VERSION "$Format:%h$"

NS_ :

BS_:

BU_: APB APP APS BCCEN BDY DAS DBG EAS EPAS EPAS2 EPAS3S EPB EPBM ESP GTW GTWU IBST IC MCU OCS PARK PARK3 RADAR RCM RT3000 SCCM SDM SEC TAS TAS2 TAS2DBG TOOL TPMS VCSEATD VCSEATP

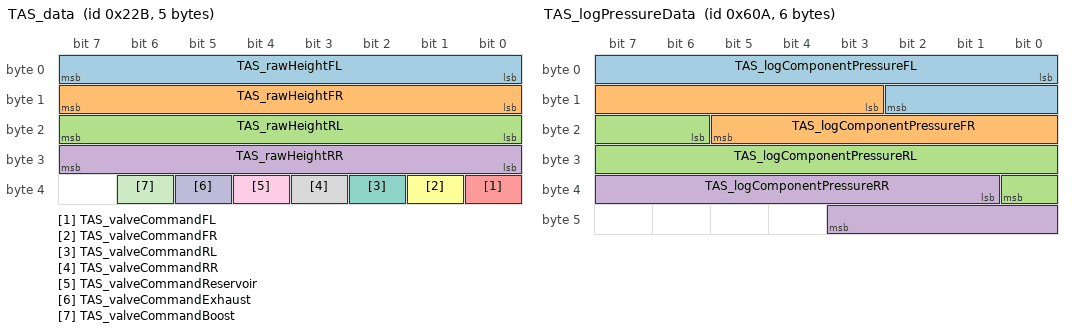
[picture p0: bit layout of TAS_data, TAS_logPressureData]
BO_ 555 TAS_data: 5 TAS
 SG_ TAS_rawHeightFL : 0|8@1+ (1,-128) [-128|127] "mm" GTW
 SG_ TAS_rawHeightFR : 8|8@1+ (1,-128) [-128|127] "mm" GTW
 SG_ TAS_rawHeightRL : 16|8@1+ (1,-128) [-128|127] "mm" GTW
 SG_ TAS_rawHeightRR : 24|8@1+ (1,-128) [-128|127] "mm" GTW
 SG_ TAS_valveCommandFL : 32|1@1+ (1,0) [0|1] "" GTW
 SG_ TAS_valveCommandFR : 33|1@1+ (1,0) [0|1] "" GTW
 SG_ TAS_valveCommandRL : 34|1@1+ (1,0) [0|1] "" GTW
 SG_ TAS_valveCommandRR : 35|1@1+ (1,0) [0|1] "" GTW
 SG_ TAS_valveCommandReservoir : 36|1@1+ (1,0) [0|1] "" GTW
 SG_ TAS_valveCommandExhaust : 37|1@1+ (1,0) [0|1] "" GTW
 SG_ TAS_valveCommandBoost : 38|1@1+ (1,0) [0|1] "" GTW

BO_ 1610 TAS_debugStates: 2 TAS
 SG_ TAS_debugStates M : 0|1@1+ (1,0) [0|1] "" Vector__XXX
 SG_ TAS_launchModeState m1 : 8|3@1+ (1,0) [0|4] "" Vector__XXX

BO_ 1307 TAS_info: 8 TAS
 SG_ TAS_infoIndex M : 0|8@1+ (1,0) [0|255] "" GTW,GTWU
 SG_ TAS_infoBuildType m10 : 8|8@1+ (1,0) [0|4] "" GTW
 SG_ TAS_infoBuildConfigId m10 : 16|16@1+ (1,0) [0|65535] "" GTW
 SG_ TAS_infoHardwareId m10 : 32|1@1+ (1,0) [0|1] "" GTW
 SG_ TAS_infoComponentId m10 : 48|16@1+ (1,0) [0|65535] "" GTW
 SG_ TAS_infoPcbaId m11 : 16|8@1+ (1,0) [0|255] "" GTW,GTWU
 SG_ TAS_infoAssemblyId m11 : 24|8@1+ (1,0) [0|255] "" GTW,GTWU
 SG_ TAS_infoUsageId m11 : 32|16@1+ (1,0) [0|65535] "" GTW,GTWU
 SG_ TAS_infoSubUsageId m11 : 48|16@1+ (1,0) [0|65535] "" GTW
 SG_ TAS_infoAppCrc m13 : 32|32@1+ (1,0) [0|4294967295] "" GTW,GTWU
 SG_ TAS_infoBootloaderSvnRevision m14 : 8|24@1+ (1,0) [0|16777215] "" GTW
 SG_ TAS_infoAppGitHash m17 : 8|56@1+ (1,0) [0|7.20575940379279E+16] "" GTW
 SG_ TAS_infoBootGitHash m18 : 8|56@1+ (1,0) [0|7.20575940379279E+16] "" GTW
 SG_ TAS_infoPlatformType m19 : 8|8@1+ (1,0) [0|255] "" GTW
 SG_ TAS_infoMajorVersion m19 : 16|8@1+ (1,0) [0|255] "" GTW
 SG_ TAS_infoBranchOrigin m19 : 24|8@1+ (1,0) [0|255] "" GTW
 SG_ TAS_infoMaturity m19 : 32|8@1+ (1,0) [0|255] "" GTW
 SG_ TAS_infoHardwareRevision m19 : 40|8@1+ (1,0) [0|255] "" GTW
 SG_ TAS_infoBootUdsProtoVersion m20 : 8|8@1+ (1,0) [0|255] "" GTW,GTWU
 SG_ TAS_infoBootCrc m20 : 32|32@1+ (1,0) [0|4294967295] "" GTW

BO_ 1546 TAS_logPressureData: 6 TAS
 SG_ TAS_logComponentPressureFL : 0|11@1+ (0.01,0) [0|20.47] "bara" GTW
 SG_ TAS_logComponentPressureFR : 11|11@1+ (0.01,0) [0|20.47] "bara" GTW
 SG_ TAS_logComponentPressureRL : 22|11@1+ (0.01,0) [0|20.47] "bara" GTW
 SG_ TAS_logComponentPressureRR : 33|11@1+ (0.01,0) [0|20.47] "bara" GTW

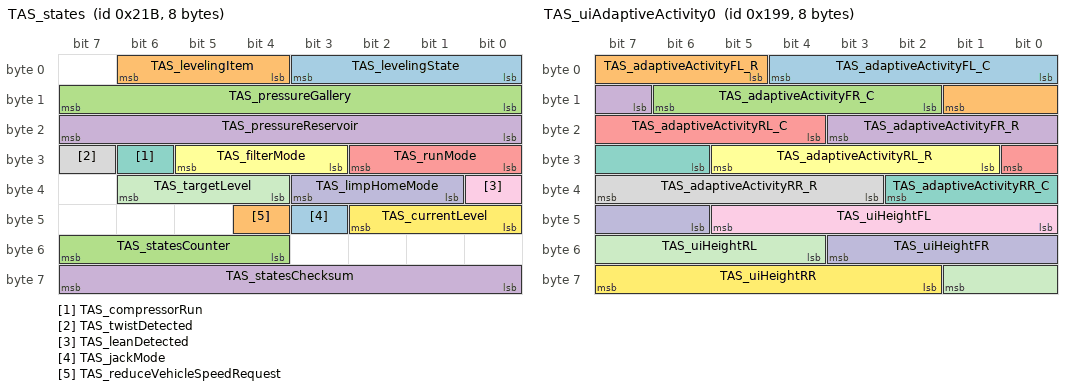
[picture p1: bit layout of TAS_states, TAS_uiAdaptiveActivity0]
BO_ 539 TAS_states: 8 TAS
 SG_ TAS_levelingState : 0|4@1+ (1,0) [0|12] "" GTW
 SG_ TAS_levelingItem : 4|3@1+ (1,0) [0|7] "" BCCEN,GTW
 SG_ TAS_pressureGallery : 8|8@1+ (0.1,0) [0|25.5] "bara" GTW
 SG_ TAS_pressureReservoir : 16|8@1+ (0.1,0) [0|25.5] "bara" GTW
 SG_ TAS_runMode : 24|3@1+ (1,0) [0|6] "" GTW
 SG_ TAS_filterMode : 27|3@1+ (1,0) [0|7] "" GTW
 SG_ TAS_compressorRun : 30|1@1+ (1,0) [0|1] "" GTW
 SG_ TAS_twistDetected : 31|1@1+ (1,0) [0|1] "" GTW
 SG_ TAS_leanDetected : 32|1@1+ (1,0) [0|1] "" GTW
 SG_ TAS_limpHomeMode : 33|3@1+ (1,0) [0|4] "" GTW
 SG_ TAS_targetLevel : 36|3@1+ (1,0) [0|4] "" GTW
 SG_ TAS_currentLevel : 40|3@1+ (1,0) [0|4] "" DAS,GTW
 SG_ TAS_jackMode : 43|1@1+ (1,0) [0|1] "" GTW
 SG_ TAS_reduceVehicleSpeedRequest : 44|1@1+ (1,0) [0|1] "" GTW
 SG_ TAS_statesCounter : 52|4@1+ (1,0) [0|15] "" GTW
 SG_ TAS_statesChecksum : 56|8@1+ (1,0) [0|255] "" GTW

BO_ 1627 TAS_udsResponse: 8 TAS
 SG_ TAS_udsResponseData : 7|64@0+ (1,0) [0|1.84467440737096E+19] "" GTW,GTWU

BO_ 409 TAS_uiAdaptiveActivity0: 8 TAS
 SG_ TAS_adaptiveActivityFL_C : 0|5@1+ (0.04,0) [0|1] "-" GTW
 SG_ TAS_adaptiveActivityFL_R : 5|5@1+ (0.04,0) [0|1] "-" GTW
 SG_ TAS_adaptiveActivityFR_C : 10|5@1+ (0.04,0) [0|1] "-" GTW
 SG_ TAS_adaptiveActivityFR_R : 15|5@1+ (0.04,0) [0|1] "-" GTW
 SG_ TAS_adaptiveActivityRL_C : 20|5@1+ (0.04,0) [0|1] "-" GTW
 SG_ TAS_adaptiveActivityRL_R : 25|5@1+ (0.04,0) [0|1] "-" GTW
 SG_ TAS_adaptiveActivityRR_C : 30|5@1+ (0.04,0) [0|1] "-" GTW
 SG_ TAS_adaptiveActivityRR_R : 35|5@1+ (0.04,0) [0|1] "-" GTW
 SG_ TAS_uiHeightFL : 40|6@1+ (4,-128) [-128|124] "mm" GTW
 SG_ TAS_uiHeightFR : 46|6@1+ (4,-128) [-128|124] "mm" GTW
 SG_ TAS_uiHeightRL : 52|6@1+ (4,-128) [-128|124] "mm" GTW
 SG_ TAS_uiHeightRR : 58|6@1+ (4,-128) [-128|124] "mm" GTW

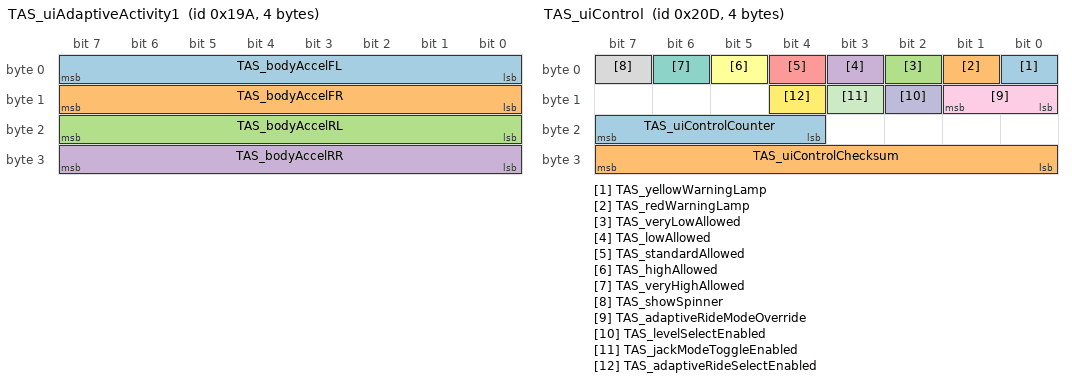
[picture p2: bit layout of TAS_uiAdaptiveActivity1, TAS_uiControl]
BO_ 410 TAS_uiAdaptiveActivity1: 4 TAS
 SG_ TAS_bodyAccelFL : 0|8@1+ (0.05,-5) [-5|5] "g" GTW
 SG_ TAS_bodyAccelFR : 8|8@1+ (0.05,-5) [-5|5] "g" GTW
 SG_ TAS_bodyAccelRL : 16|8@1+ (0.05,-5) [-5|5] "g" GTW
 SG_ TAS_bodyAccelRR : 24|8@1+ (0.05,-5) [-5|5] "g" GTW

BO_ 525 TAS_uiControl: 4 TAS
 SG_ TAS_yellowWarningLamp : 0|1@1+ (1,0) [0|1] "" GTW
 SG_ TAS_redWarningLamp : 1|1@1+ (1,0) [0|1] "" GTW
 SG_ TAS_veryLowAllowed : 2|1@1+ (1,0) [0|1] "" GTW
 SG_ TAS_lowAllowed : 3|1@1+ (1,0) [0|1] "" GTW
 SG_ TAS_standardAllowed : 4|1@1+ (1,0) [0|1] "" GTW
 SG_ TAS_highAllowed : 5|1@1+ (1,0) [0|1] "" GTW
 SG_ TAS_veryHighAllowed : 6|1@1+ (1,0) [0|1] "" GTW
 SG_ TAS_showSpinner : 7|1@1+ (1,0) [0|1] "" GTW
 SG_ TAS_adaptiveRideModeOverride : 8|2@1+ (1,0) [0|3] "" GTW
 SG_ TAS_levelSelectEnabled : 10|1@1+ (1,0) [0|1] "" GTW
 SG_ TAS_jackModeToggleEnabled : 11|1@1+ (1,0) [0|1] "" GTW
 SG_ TAS_adaptiveRideSelectEnabled : 12|1@1+ (1,0) [0|1] "" GTW
 SG_ TAS_uiControlCounter : 20|4@1+ (1,0) [0|15] "" GTW
 SG_ TAS_uiControlChecksum : 24|8@1+ (1,0) [0|255] "" GTW

BO_ 843 TAS_warningMatrix1: 8 TAS
 SG_ TAS_a001_WatchdogReset : 0|1@1+ (1,0) [0|1] "" GTW
 SG_ TAS_a002_PowerLossReset : 1|1@1+ (1,0) [0|1] "" GTW
 SG_ TAS_a003_SWAssertion : 2|1@1+ (1,0) [0|1] "" GTW
 SG_ TAS_a012_CPUReset : 11|1@1+ (1,0) [0|1] "" GTW
 SG_ TAS_a015_NVMMAlert : 14|1@1+ (1,0) [0|1] "" GTW
 SG_ TAS_a021_TaskSchedulerError : 20|1@1+ (1,0) [0|1] "" GTW
 SG_ TAS_a022_TaskInitError : 21|1@1+ (1,0) [0|1] "" GTW
 SG_ TAS_a025_CrashEvent : 24|1@1+ (1,0) [0|1] "" GTW
 SG_ TAS_a030_PWMerrorFL : 29|1@1+ (1,0) [0|1] "" GTW
 SG_ TAS_a031_PWMerrorFR : 30|1@1+ (1,0) [0|1] "" GTW
 SG_ TAS_a032_PWMerrorRL : 31|1@1+ (1,0) [0|1] "" GTW
 SG_ TAS_a033_PWMerrorRR : 32|1@1+ (1,0) [0|1] "" GTW
 SG_ TAS_a034_PWMshortFL : 33|1@1+ (1,0) [0|1] "" GTW
 SG_ TAS_a035_PWMshortFR : 34|1@1+ (1,0) [0|1] "" GTW
 SG_ TAS_a036_PWMshortRL : 35|1@1+ (1,0) [0|1] "" GTW
 SG_ TAS_a037_PWMshortRR : 36|1@1+ (1,0) [0|1] "" GTW
 SG_ TAS_a038_PWMopenFL : 37|1@1+ (1,0) [0|1] "" GTW
 SG_ TAS_a039_PWMopenFR : 38|1@1+ (1,0) [0|1] "" GTW
 SG_ TAS_a040_PWMopenRL : 39|1@1+ (1,0) [0|1] "" GTW
 SG_ TAS_a041_PWMopenRR : 40|1@1+ (1,0) [0|1] "" GTW
 SG_ TAS_a043_Task1msError : 42|1@1+ (1,0) [0|1] "" GTW
 SG_ TAS_a044_Task10msError : 43|1@1+ (1,0) [0|1] "" GTW
 SG_ TAS_a045_Task100msError : 44|1@1+ (1,0) [0|1] "" GTW
 SG_ TAS_a046_Task1000msError : 45|1@1+ (1,0) [0|1] "" GTW
 SG_ TAS_a061_XCPConnected : 60|1@1+ (1,0) [0|1] "" GTW
 SG_ TAS_a062_XCPWasConnected : 61|1@1+ (1,0) [0|1] "" GTW

BO_ 859 TAS_warningMatrix2: 8 TAS
 SG_ TAS_a070_underVoltage12V : 5|1@1+ (1,0) [0|1] "" GTW
 SG_ TAS_a071_overVoltage12V : 6|1@1+ (1,0) [0|1] "" GTW
 SG_ TAS_a072_shortCircuit5VOnBoard : 7|1@1+ (1,0) [0|1] "" GTW
 SG_ TAS_a073_underVoltage5VOnBoard : 8|1@1+ (1,0) [0|1] "" GTW
 SG_ TAS_a074_shortCircuit5VOffBoard : 9|1@1+ (1,0) [0|1] "" GTW
 SG_ TAS_a075_underVoltage5VOffBoard : 10|1@1+ (1,0) [0|1] "" GTW
 SG_ TAS_a076_overVoltage5VOffBoard : 11|1@1+ (1,0) [0|1] "" GTW
 SG_ TAS_a077_pressureSigVTooLow : 12|1@1+ (1,0) [0|1] "" GTW
 SG_ TAS_a078_pressureSigVTooHigh : 13|1@1+ (1,0) [0|1] "" GTW
 SG_ TAS_a093_OTPError : 28|1@1+ (1,0) [0|1] "" GTW
 SG_ TAS_a098_MCU_MIA : 33|1@1+ (1,0) [0|1] "" GTW
 SG_ TAS_a099_EFUSE_MIA : 34|1@1+ (1,0) [0|1] "" GTW
 SG_ TAS_a100_SCCM_MIA : 35|1@1+ (1,0) [0|1] "" GTW
 SG_ TAS_a101_ESP_MIA : 36|1@1+ (1,0) [0|1] "" GTW
 SG_ TAS_a102_DI_MIA : 37|1@1+ (1,0) [0|1] "" GTW
 SG_ TAS_a103_GTW_MIA : 38|1@1+ (1,0) [0|1] "" GTW
 SG_ TAS_a105_ECUDebugMode : 40|1@1+ (1,0) [0|1] "" GTW
 SG_ TAS_a106_HighCPULoad : 41|1@1+ (1,0) [0|1] "" GTW
 SG_ TAS_a107_HighStackUsage : 42|1@1+ (1,0) [0|1] "" GTW
 SG_ TAS_a121_maxDutyFL : 56|1@1+ (1,0) [0|1] "" GTW
 SG_ TAS_a122_maxDutyFR : 57|1@1+ (1,0) [0|1] "" GTW
 SG_ TAS_a123_maxDutyRL : 58|1@1+ (1,0) [0|1] "" GTW
 SG_ TAS_a124_maxDutyRR : 59|1@1+ (1,0) [0|1] "" GTW
 SG_ TAS_a125_maxDutyReservoir : 60|1@1+ (1,0) [0|1] "" GTW
 SG_ TAS_a126_maxDutyExhaust : 61|1@1+ (1,0) [0|1] "" GTW
 SG_ TAS_a127_maxDutyBoost : 62|1@1+ (1,0) [0|1] "" GTW
 SG_ TAS_a128_maxDutyCompressor : 63|1@1+ (1,0) [0|1] "" GTW

BO_ 875 TAS_warningMatrix3: 8 TAS
 SG_ TAS_a129_openCircuitFL : 0|1@1+ (1,0) [0|1] "" GTW
 SG_ TAS_a130_openCircuitFR : 1|1@1+ (1,0) [0|1] "" GTW
 SG_ TAS_a131_openCircuitRL : 2|1@1+ (1,0) [0|1] "" GTW
 SG_ TAS_a132_openCircuitRR : 3|1@1+ (1,0) [0|1] "" GTW
 SG_ TAS_a133_openCircuitReservoir : 4|1@1+ (1,0) [0|1] "" GTW
 SG_ TAS_a134_openCircuitExhaust : 5|1@1+ (1,0) [0|1] "" GTW
 SG_ TAS_a135_openCircuitBoost : 6|1@1+ (1,0) [0|1] "" GTW
 SG_ TAS_a136_openCircuitCompressor : 7|1@1+ (1,0) [0|1] "" GTW
 SG_ TAS_a137_shortCircuitFL : 8|1@1+ (1,0) [0|1] "" GTW
 SG_ TAS_a138_shortCircuitFR : 9|1@1+ (1,0) [0|1] "" GTW
 SG_ TAS_a139_shortCircuitRL : 10|1@1+ (1,0) [0|1] "" GTW
 SG_ TAS_a140_shortCircuitRR : 11|1@1+ (1,0) [0|1] "" GTW
 SG_ TAS_a141_shortCircuitReservoir : 12|1@1+ (1,0) [0|1] "" GTW
 SG_ TAS_a142_shortCircuitExhaust : 13|1@1+ (1,0) [0|1] "" GTW
 SG_ TAS_a143_shortCircuitBoost : 14|1@1+ (1,0) [0|1] "" GTW
 SG_ TAS_a144_shortCircuitCompressor : 15|1@1+ (1,0) [0|1] "" GTW
 SG_ TAS_a145_boardFaultFL : 16|1@1+ (1,0) [0|1] "" GTW
 SG_ TAS_a146_boardFaultFR : 17|1@1+ (1,0) [0|1] "" GTW
 SG_ TAS_a147_boardFaultRL : 18|1@1+ (1,0) [0|1] "" GTW
 SG_ TAS_a148_boardFaultRR : 19|1@1+ (1,0) [0|1] "" GTW
 SG_ TAS_a149_boardFaultReservoir : 20|1@1+ (1,0) [0|1] "" GTW
 SG_ TAS_a150_boardFaultExhaust : 21|1@1+ (1,0) [0|1] "" GTW
 SG_ TAS_a151_boardFaultBoost : 22|1@1+ (1,0) [0|1] "" GTW
 SG_ TAS_a152_boardFaultCompressor : 23|1@1+ (1,0) [0|1] "" GTW
 SG_ TAS_a153_otherCircuitFL : 24|1@1+ (1,0) [0|1] "" GTW
 SG_ TAS_a154_otherCircuitFR : 25|1@1+ (1,0) [0|1] "" GTW
 SG_ TAS_a155_otherCircuitRL : 26|1@1+ (1,0) [0|1] "" GTW
 SG_ TAS_a156_otherCircuitRR : 27|1@1+ (1,0) [0|1] "" GTW
 SG_ TAS_a157_otherCircuitReservoir : 28|1@1+ (1,0) [0|1] "" GTW
 SG_ TAS_a158_otherCircuitExhaust : 29|1@1+ (1,0) [0|1] "" GTW
 SG_ TAS_a159_otherCircuitBoost : 30|1@1+ (1,0) [0|1] "" GTW
 SG_ TAS_a160_otherCircuitCompressor : 31|1@1+ (1,0) [0|1] "" GTW
 SG_ TAS_a161_valveBlockOpenGND : 32|1@1+ (1,0) [0|1] "" GTW
 SG_ TAS_a162_compressorValveOpenGND : 33|1@1+ (1,0) [0|1] "" GTW
 SG_ TAS_a163_reservoirFillDisabled : 34|1@1+ (1,0) [0|1] "" GTW
 SG_ TAS_a173_staticLeakDetectFL : 44|1@1+ (1,0) [0|1] "" GTW
 SG_ TAS_a174_staticLeakDetectFR : 45|1@1+ (1,0) [0|1] "" GTW
 SG_ TAS_a175_staticLeakDetectRL : 46|1@1+ (1,0) [0|1] "" GTW
 SG_ TAS_a176_staticLeakDetectRR : 47|1@1+ (1,0) [0|1] "" GTW

BO_ 891 TAS_warningMatrix4: 8 TAS
 SG_ TAS_a200_jackModeActive : 7|1@1+ (1,0) [0|1] "" GTW
 SG_ TAS_a201_lowHVBattery : 8|1@1+ (1,0) [0|1] "" GTW
 SG_ TAS_a210_outOfRangeCalibration : 17|1@1+ (1,0) [0|1] "" GTW
 SG_ TAS_a211_noRideHeightCalib : 18|1@1+ (1,0) [0|1] "" GTW
 SG_ TAS_a213_yellowWarningLamp : 20|1@1+ (1,0) [0|1] "" GTW
 SG_ TAS_a214_redWarningLamp : 21|1@1+ (1,0) [0|1] "" GTW
 SG_ TAS_a215_limpHomeMode10 : 22|1@1+ (1,0) [0|1] "" GTW
 SG_ TAS_a216_limpHomeMode20 : 23|1@1+ (1,0) [0|1] "" GTW
 SG_ TAS_a217_limpHomeMode30 : 24|1@1+ (1,0) [0|1] "" GTW
 SG_ TAS_a218_limpHomeMode40 : 25|1@1+ (1,0) [0|1] "" GTW
 SG_ TAS_a220_exhaustGalleryFault : 27|1@1+ (1,0) [0|1] "" GTW
 SG_ TAS_a221_valveLeakDetected : 28|1@1+ (1,0) [0|1] "" GTW
 SG_ TAS_a222_compressorPrefillFault : 29|1@1+ (1,0) [0|1] "" GTW
 SG_ TAS_a223_blockedAirline : 30|1@1+ (1,0) [0|1] "" GTW
 SG_ TAS_a224_openAirline : 31|1@1+ (1,0) [0|1] "" GTW
 SG_ TAS_a225_galleryPressureTooHigh : 32|1@1+ (1,0) [0|1] "" GTW
 SG_ TAS_a226_PWMfastDetectFL : 33|1@1+ (1,0) [0|1] "" GTW
 SG_ TAS_a227_PWMfastDetectFR : 34|1@1+ (1,0) [0|1] "" GTW
 SG_ TAS_a228_PWMfastDetectRL : 35|1@1+ (1,0) [0|1] "" GTW
 SG_ TAS_a229_PWMfastDetectRR : 36|1@1+ (1,0) [0|1] "" GTW
 SG_ TAS_a230_geofenceNotification : 37|1@1+ (1,0) [0|1] "" GTW

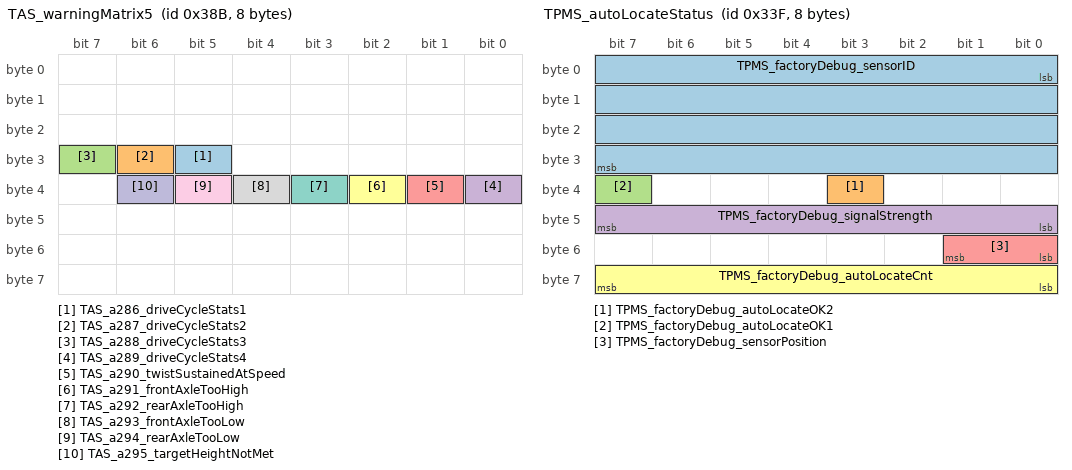
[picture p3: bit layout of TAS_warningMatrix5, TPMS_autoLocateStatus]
BO_ 907 TAS_warningMatrix5: 8 TAS
 SG_ TAS_a286_driveCycleStats1 : 29|1@1+ (1,0) [0|1] "" GTW
 SG_ TAS_a287_driveCycleStats2 : 30|1@1+ (1,0) [0|1] "" GTW
 SG_ TAS_a288_driveCycleStats3 : 31|1@1+ (1,0) [0|1] "" GTW
 SG_ TAS_a289_driveCycleStats4 : 32|1@1+ (1,0) [0|1] "" GTW
 SG_ TAS_a290_twistSustainedAtSpeed : 33|1@1+ (1,0) [0|1] "" GTW
 SG_ TAS_a291_frontAxleTooHigh : 34|1@1+ (1,0) [0|1] "" GTW
 SG_ TAS_a292_rearAxleTooHigh : 35|1@1+ (1,0) [0|1] "" GTW
 SG_ TAS_a293_frontAxleTooLow : 36|1@1+ (1,0) [0|1] "" GTW
 SG_ TAS_a294_rearAxleTooLow : 37|1@1+ (1,0) [0|1] "" GTW
 SG_ TAS_a295_targetHeightNotMet : 38|1@1+ (1,0) [0|1] "" GTW

BO_ 1851 TAS_xcpResponse: 8 TAS
 SG_ TAS_xcpResponse : 7|64@0+ (1,0) [0|1.84467440737096E+19] "" DBG

BO_ 895 TPMS_DebugC: 8 TPMS

BO_ 879 TPMS_StatusC: 8 TPMS
 SG_ TPMS_c_globalHardWarning : 0|1@1+ (1,0) [0|0] "" GTW,RCM
 SG_ TPMS_c_globalSoftWarning : 1|1@1+ (1,0) [0|0] "" GTW,RCM
 SG_ TPMS_systemMalfunction : 2|1@1+ (1,0) [0|0] "" GTW,RCM
 SG_ TPMS_WA_version : 3|1@1+ (1,0) [0|0] "" GTW
 SG_ TPMS_globalDeltaPressure : 4|1@1+ (1,0) [0|0] "" GTW
 SG_ TPMS_newSensorLearnt : 5|1@1+ (1,0) [0|0] "" GTW
 SG_ TPMS_softWarningRR : 8|1@1+ (1,0) [0|0] "" GTW
 SG_ TPMS_hardWarningRR : 9|1@1+ (1,0) [0|0] "" GTW
 SG_ TPMS_softWarningRL : 10|1@1+ (1,0) [0|0] "" GTW
 SG_ TPMS_hardWarningRL : 11|1@1+ (1,0) [0|0] "" GTW
 SG_ TPMS_softWarningFR : 12|1@1+ (1,0) [0|0] "" GTW
 SG_ TPMS_hardWarningFR : 13|1@1+ (1,0) [0|0] "" GTW
 SG_ TPMS_softWarningFL : 14|1@1+ (1,0) [0|0] "" GTW
 SG_ TPMS_hardWarningFL : 15|1@1+ (1,0) [0|0] "" GTW
 SG_ TPMS_learningStatus : 16|2@1+ (1,0) [0|0] "" GTW
 SG_ TPMS_localisationStatus : 18|2@1+ (1,0) [0|0] "" GTW
 SG_ TPMS_deltaPressWarningFL : 20|1@1+ (1,0) [0|0] "" GTW
 SG_ TPMS_deltaPressWarningFR : 21|1@1+ (1,0) [0|0] "" GTW
 SG_ TPMS_deltaPressWarningRL : 22|1@1+ (1,0) [0|0] "" GTW
 SG_ TPMS_deltaPressWarningRR : 23|1@1+ (1,0) [0|0] "" GTW
 SG_ TPMS_sensorNoResponseFL : 24|1@1+ (1,0) [0|0] "" GTW
 SG_ TPMS_sensorNoResponseFR : 25|1@1+ (1,0) [0|0] "" GTW
 SG_ TPMS_sensorNoResponseRL : 26|1@1+ (1,0) [0|0] "" GTW
 SG_ TPMS_sensorNoResponseRR : 27|1@1+ (1,0) [0|0] "" GTW
 SG_ TPMS_sensorThermShutdownFL : 28|1@1+ (1,0) [0|0] "" GTW
 SG_ TPMS_sensorThermShutdownFR : 29|1@1+ (1,0) [0|0] "" GTW
 SG_ TPMS_sensorThermShutdownRL : 30|1@1+ (1,0) [0|0] "" GTW
 SG_ TPMS_sensorThermShutdownRR : 31|1@1+ (1,0) [0|0] "" GTW
 SG_ TPMS_c_sensorBatteryLowFL : 32|1@1+ (1,0) [0|0] "" GTW
 SG_ TPMS_c_sensorBatteryLowFR : 33|1@1+ (1,0) [0|0] "" GTW
 SG_ TPMS_c_sensorBatteryLowRL : 34|1@1+ (1,0) [0|0] "" GTW
 SG_ TPMS_c_sensorBatteryLowRR : 35|1@1+ (1,0) [0|0] "" GTW
 SG_ TPMS_sensorDefectiveFL : 36|1@1+ (1,0) [0|0] "" GTW
 SG_ TPMS_sensorDefectiveFR : 37|1@1+ (1,0) [0|0] "" GTW
 SG_ TPMS_sensorDefectiveRL : 38|1@1+ (1,0) [0|0] "" GTW
 SG_ TPMS_sensorDefectiveRR : 39|1@1+ (1,0) [0|0] "" GTW
 SG_ TPMS_ecuUnderVoltage : 40|1@1+ (1,0) [0|0] "" GTW
 SG_ TPMS_ecuOverVoltage : 41|1@1+ (1,0) [0|0] "" GTW
 SG_ TPMS_ecuRamRomNvMFail : 42|1@1+ (1,0) [0|0] "" GTW
 SG_ TPMS_rfReceiverFail : 43|1@1+ (1,0) [0|0] "" GTW
 SG_ TPMS_wheelPulseMissing : 44|1@1+ (1,0) [0|0] "" GTW
 SG_ TPMS_vehicleSpeedFail : 45|1@1+ (1,0) [0|0] "" GTW
 SG_ TPMS_externalTemperatureFail : 46|1@1+ (1,0) [0|0] "" GTW
 SG_ TPMS_eolNotCompleted : 47|1@1+ (1,0) [0|0] "" GTW
 SG_ TPMS_rcpFront : 48|8@1+ (0.025,0) [0|6.375] "bar" GTW
 SG_ TPMS_rcpRear : 56|8@1+ (0.025,0) [0|6.375] "bar" GTW

BO_ 863 TPMS_antennaStatus: 8 TPMS
 SG_ TPMS_startupFlagRR : 0|1@1+ (1,0) [0|0] "" GTW
 SG_ TPMS_startupFlagRL : 1|1@1+ (1,0) [0|0] "" GTW
 SG_ TPMS_startupFlagFR : 2|1@1+ (1,0) [0|0] "" GTW
 SG_ TPMS_startupFlagFL : 3|1@1+ (1,0) [0|0] "" GTW
 SG_ TPMS_startupFlagTPMS : 4|1@1+ (1,0) [0|0] "" GTW
 SG_ TPMS_autoLearnFinishedFlag : 6|1@1+ (1,0) [0|0] "" GTW
 SG_ TPMS_requiredAutoLearnResult : 7|1@1+ (1,0) [0|0] "" GTW
 SG_ TPMS_IDWriteErrorFlag : 8|1@1+ (1,0) [0|0] "" GTW
 SG_ TPMS_modeInfoTPMS : 9|1@1+ (1,0) [0|0] "" GTW
 SG_ TPMS_wheelSizeInfo : 10|1@1+ (1,0) [0|0] "" GTW
 SG_ TPMS_autoLearnDebugInfo : 11|1@1+ (1,0) [0|0] "" GTW
 SG_ TPMS_errorRSSI : 14|1@1+ (1,0) [0|0] "" GTW
 SG_ TPMS_sideInformationError : 15|1@1+ (1,0) [0|0] "" GTW
 SG_ TPMS_startUpTimeout : 16|8@1+ (1,0) [0|0] "" GTW
 SG_ TPMS_speedUpTimeout : 24|8@1+ (1,0) [0|0] "" GTW
 SG_ TPMS_noResponseTimeoutFL : 32|8@1+ (1,0) [0|0] "" GTW
 SG_ TPMS_noResponseTimeoutFR : 40|8@1+ (1,0) [0|0] "" GTW
 SG_ TPMS_noResponseTimeoutRL : 48|8@1+ (1,0) [0|0] "" GTW
 SG_ TPMS_noResponseTimeoutRR : 56|8@1+ (1,0) [0|0] "" GTW

BO_ 831 TPMS_autoLocateStatus: 8 TPMS
 SG_ TPMS_factoryDebug_sensorID : 0|32@1+ (1,0) [0|0] "" DBG
 SG_ TPMS_factoryDebug_autoLocateOK2 : 35|1@1+ (1,0) [0|0] "" DBG
 SG_ TPMS_factoryDebug_autoLocateOK1 : 39|1@1+ (1,0) [0|0] "" DBG
 SG_ TPMS_factoryDebug_signalStrength : 40|8@1+ (1,0) [0|0] "" DBG
 SG_ TPMS_factoryDebug_sensorPosition : 48|2@1+ (1,0) [0|0] "" DBG
 SG_ TPMS_factoryDebug_autoLocateCnt : 56|8@1+ (1,0) [0|0] "" DBG

BO_ 1535 TPMS_bootID: 8 TPMS
 SG_ TPMS_bootIdData : 0|64@1+ (1,0) [0|0] "" GTWU

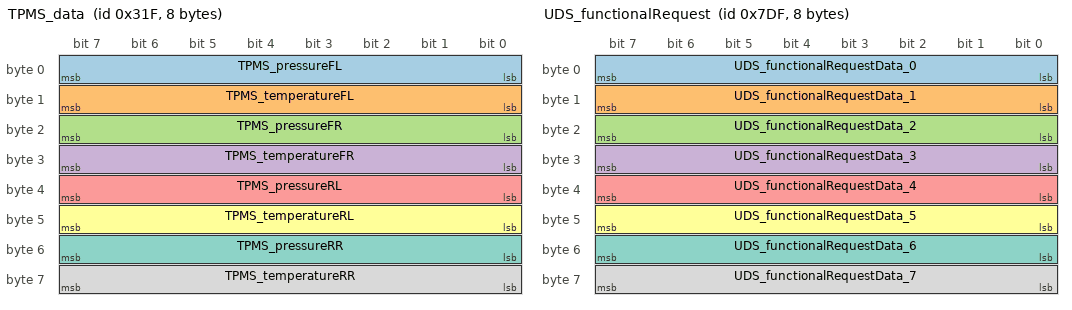
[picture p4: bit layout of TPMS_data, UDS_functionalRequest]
BO_ 799 TPMS_data: 8 TPMS
 SG_ TPMS_pressureFL : 0|8@1+ (0.025,0) [0|6.375] "bar" GTW
 SG_ TPMS_temperatureFL : 8|8@1+ (1,-40) [-40|215] "C" GTW
 SG_ TPMS_pressureFR : 16|8@1+ (0.025,0) [0|6.375] "bar" GTW
 SG_ TPMS_temperatureFR : 24|8@1+ (1,-40) [-40|215] "C" GTW
 SG_ TPMS_pressureRL : 32|8@1+ (0.025,0) [0|6.375] "bar" GTW
 SG_ TPMS_temperatureRL : 40|8@1+ (1,-40) [-40|215] "C" GTW
 SG_ TPMS_pressureRR : 48|8@1+ (0.025,0) [0|6.375] "bar" GTW
 SG_ TPMS_temperatureRR : 56|8@1+ (1,-40) [-40|215] "C" GTW

BO_ 1519 TPMS_info: 8 TPMS
 SG_ TPMS_infoIdx M : 0|8@1+ (1,0) [0|0] "" GTW,GTWU
 SG_ TPMS_infoComponentID m10 : 48|16@1+ (1,0) [0|0] "" GTW,GTWU
 SG_ TPMS_infoPcbaID m11 : 16|8@1+ (1,0) [0|0] "" GTW,GTWU
 SG_ TPMS_infoAssemblyID m11 : 24|8@1+ (1,0) [0|255] "" GTW,GTWU
 SG_ TPMS_infoUsageID m11 : 32|16@1+ (1,0) [0|65535] "" GTW,GTWU
 SG_ TPMS_infoApplicationCRC m13 : 32|32@1+ (1,0) [0|0] "" GTW,GTWU
 SG_ TPMS_infoBootUdsProtoVersion m20 : 8|8@1+ (1,0) [0|0] "" GTW,GTWU
 SG_ TPMS_infoBootloaderCRC m20 : 32|32@1+ (1,0) [0|0] "" GTW

BO_ 882 TPMS_sensorIDs: 8 TPMS
 SG_ TPMS_sensorIDIndex M : 0|8@1+ (1,0) [0|3] "" GTW
 SG_ TPMS_sensorIDFL m0 : 32|32@1+ (1,0) [0|4294967295] "" GTW
 SG_ TPMS_sensorIDRR m1 : 32|32@1+ (1,0) [0|4294967295] "" GTW
 SG_ TPMS_sensorIDFR m2 : 32|32@1+ (1,0) [0|4294967295] "" GTW
 SG_ TPMS_sensorIDRL m3 : 32|32@1+ (1,0) [0|4294967295] "" GTW

BO_ 783 TPMS_status: 8 TPMS
 SG_ TPMS_globalHardWarning : 0|1@1+ (1,0) [0|0] "" GTW
 SG_ TPMS_globalSoftWarning : 1|1@1+ (1,0) [0|0] "" GTW
 SG_ TPMS_globalVMaxPresWarning : 2|1@1+ (1,0) [0|0] "" GTW
 SG_ TPMS_globalOverPresWarning : 3|1@1+ (1,0) [0|0] "" GTW
 SG_ TPMS_globalLowPresWarning : 4|1@1+ (1,0) [0|0] "" GTW
 SG_ TPMS_globalDeltaPressureWarning : 5|1@1+ (1,0) [0|0] "" GTW
 SG_ TPMS_globalTireTempWarning : 6|1@1+ (1,0) [0|0] "" GTW
 SG_ TPMS_globalRunFlatWarning : 7|1@1+ (1,0) [0|0] "" GTW
 SG_ TPMS_batteryVoltageLow : 16|1@1+ (1,0) [0|0] "" GTW
 SG_ TPMS_batteryVoltageHigh : 17|1@1+ (1,0) [0|0] "" GTW
 SG_ TPMS_circuitVoltageLow : 18|1@1+ (1,0) [0|0] "" GTW
 SG_ TPMS_circuitVoltageHigh : 19|1@1+ (1,0) [0|0] "" GTW
 SG_ TPMS_referenceVoltageLow : 20|1@1+ (1,0) [0|0] "" GTW
 SG_ TPMS_referenceVoltageHigh : 21|1@1+ (1,0) [0|0] "" GTW
 SG_ TPMS_noPingReponseFL : 24|1@1+ (1,0) [0|0] "" GTW
 SG_ TPMS_noPingResponseFR : 25|1@1+ (1,0) [0|0] "" GTW
 SG_ TPMS_noPingResponseRL : 26|1@1+ (1,0) [0|0] "" GTW
 SG_ TPMS_noPingResponseRR : 27|1@1+ (1,0) [0|0] "" GTW
 SG_ TPMS_unableToLearnFL : 28|1@1+ (1,0) [0|0] "" GTW
 SG_ TPMS_unableToLearnFR : 29|1@1+ (1,0) [0|0] "" GTW
 SG_ TPMS_unableToLearnRL : 30|1@1+ (1,0) [0|0] "" GTW
 SG_ TPMS_unableToLearnRR : 31|1@1+ (1,0) [0|0] "" GTW
 SG_ TPMS_sensorBatteryLowFL : 32|1@1+ (1,0) [0|0] "" GTW
 SG_ TPMS_sensorBatteryLowFR : 33|1@1+ (1,0) [0|0] "" GTW
 SG_ TPMS_sensorBatteryLowRL : 34|1@1+ (1,0) [0|0] "" GTW
 SG_ TPMS_sensorBatteryLowRR : 35|1@1+ (1,0) [0|0] "" GTW
 SG_ TPMS_sensorInfoErrorFL : 36|1@1+ (1,0) [0|0] "" GTW
 SG_ TPMS_sensorInfoErrorFR : 37|1@1+ (1,0) [0|0] "" GTW
 SG_ TPMS_sensorInfoErrorRL : 38|1@1+ (1,0) [0|0] "" GTW
 SG_ TPMS_sensorInfoErrorRR : 39|1@1+ (1,0) [0|0] "" GTW
 SG_ TPMS_overflowPressureFL : 40|1@1+ (1,0) [0|0] "" GTW
 SG_ TPMS_overflowPressureFR : 41|1@1+ (1,0) [0|0] "" GTW
 SG_ TPMS_overflowPressureRL : 42|1@1+ (1,0) [0|0] "" GTW
 SG_ TPMS_overflowPressureRR : 43|1@1+ (1,0) [0|0] "" GTW
 SG_ TPMS_sensorTempWarnFlagFL : 44|1@1+ (1,0) [0|0] "" GTW
 SG_ TPMS_sensorTempWarnFlagFR : 45|1@1+ (1,0) [0|0] "" GTW
 SG_ TPMS_sensorTempWarnFlagRL : 46|1@1+ (1,0) [0|0] "" GTW
 SG_ TPMS_sensorTempWarnFlagRR : 47|1@1+ (1,0) [0|0] "" GTW
 SG_ TPMS_carMovingFlag : 48|1@1+ (1,0) [0|0] "" GTW
 SG_ TPMS_systemFault : 49|1@1+ (1,0) [0|0] "" GTW
 SG_ TPMS_overTempPSU : 51|1@1+ (1,0) [0|0] "" GTW
 SG_ TPMS_noDataRxCANError : 52|1@1+ (1,0) [0|0] "" GTW
 SG_ TPMS_dataRxCANError : 53|1@1+ (1,0) [0|0] "" GTW
 SG_ TPMS_lowPressHiSpeedMode : 54|1@1+ (1,0) [0|0] "" GTW
 SG_ TPMS_checkingInProgress : 56|1@1+ (1,0) [0|0] "" GTW
 SG_ TPMS_learningInProgress : 57|1@1+ (1,0) [0|0] "" GTW
 SG_ TPMS_statusLearned : 58|1@1+ (1,0) [0|0] "" GTW
 SG_ TPMS_autoLearnResult : 59|1@1+ (1,0) [0|0] "" GTW
 SG_ TPMS_autoLocationResult : 60|1@1+ (1,0) [0|0] "" GTW
 SG_ TPMS_IDLearnActiveByPwrON : 61|1@1+ (1,0) [0|0] "" GTW
 SG_ TPMS_autoLocationRequired : 62|1@1+ (1,0) [0|0] "" GTW
 SG_ TPMS_autoLearnRequired : 63|1@1+ (1,0) [0|0] "" GTW

BO_ 1631 TPMS_udsResponse: 8 TPMS
 SG_ TPMS_udsResponseData : 7|64@0+ (1,0) [0|0] "" GTW,GTWU

BO_ 1609 UDS_dasRequest: 8 GTW
 SG_ UDS_dasRequestData : 7|64@0+ (1,0) [0|0] "" DAS

BO_ 1584 UDS_epas3pRequest: 8 GTW
 SG_ UDS_epas3pRequestData : 7|64@0+ (1,0) [0|1.84467440737095E+19] "" DAS

BO_ 1840 UDS_epasRequest: 8 GTW
 SG_ UDS_epasRequestData : 7|64@0+ (1,0) [0|0] "" EPAS,EPAS2,EPAS3S

BO_ 1604 UDS_epbRequest: 8 GTW
 SG_ UDS_epbRequestData_H : 7|32@0+ (1,0) [0|4294967295] "" EPB
 SG_ UDS_epbRequestData_L : 39|32@0+ (1,0) [0|4294967295] "" EPB

BO_ 1607 UDS_epbmRequest: 8 GTW
 SG_ UDS_epbmRequestData_H : 7|32@0+ (1,0) [0|4294967295] "" EPBM
 SG_ UDS_epbmRequestData_L : 39|32@0+ (1,0) [0|4294967295] "" EPBM

BO_ 1605 UDS_espRequest: 8 GTW
 SG_ UDS_espRequestData : 7|64@0+ (1,0) [0|0] "" ESP

BO_ 2015 UDS_functionalRequest: 8 GTW
 SG_ UDS_functionalRequestData_0 : 7|8@0+ (1,0) [0|0] "" PARK,EAS,TPMS,SCCM,EPAS,EPAS2,EPAS3S,OCS,ESP,RCM,SDM,TAS,DAS
 SG_ UDS_functionalRequestData_1 : 15|8@0+ (1,0) [0|0] "" PARK,EAS,TPMS,SCCM,EPAS,EPAS2,EPAS3S,OCS,ESP,RCM,SDM,TAS,DAS
 SG_ UDS_functionalRequestData_2 : 23|8@0+ (1,0) [0|0] "" PARK,EAS,TPMS,SCCM,EPAS,EPAS2,EPAS3S,OCS,ESP,RCM,SDM,TAS,DAS
 SG_ UDS_functionalRequestData_3 : 31|8@0+ (1,0) [0|0] "" PARK,EAS,TPMS,SCCM,EPAS,EPAS2,EPAS3S,OCS,ESP,RCM,SDM,TAS,DAS
 SG_ UDS_functionalRequestData_4 : 39|8@0+ (1,0) [0|0] "" PARK,EAS,TPMS,SCCM,EPAS,EPAS2,EPAS3S,OCS,ESP,RCM,SDM,TAS,DAS
 SG_ UDS_functionalRequestData_5 : 47|8@0+ (1,0) [0|0] "" PARK,EAS,TPMS,SCCM,EPAS,EPAS2,EPAS3S,OCS,ESP,RCM,SDM,TAS,DAS
 SG_ UDS_functionalRequestData_6 : 55|8@0+ (1,0) [0|0] "" PARK,EAS,TPMS,SCCM,EPAS,EPAS2,EPAS3S,OCS,ESP,RCM,SDM,TAS,DAS
 SG_ UDS_functionalRequestData_7 : 63|8@0+ (1,0) [0|0] "" PARK,EAS,TPMS,SCCM,EPAS,EPAS2,EPAS3S,OCS,ESP,RCM,SDM,TAS,DAS

BO_ 1613 UDS_ibstRequest: 8 GTW
 SG_ UDS_ibstRequestData : 7|64@0+ (1,0) [0|0] "" IBST

BO_ 1612 UDS_icRequest: 8 GTW
 SG_ UDS_icRequestData : 7|64@0+ (1,0) [0|0] "" IC

BO_ 1603 UDS_ocsRequest: 8 GTW
 SG_ UDS_ocsRequestData : 7|64@0+ (1,0) [0|0] "" OCS

BO_ 1614 UDS_parkRequest: 8 GTW
 SG_ UDS_parkRequestData : 7|64@0+ (1,0) [0|0] "" PARK

BO_ 1649 UDS_radcRequest: 8 GTW
 SG_ UDS_radcRequestData : 7|64@0+ (1,0) [0|0] "" DAS

BO_ 1652 UDS_radflRequest: 8 GTW
 SG_ UDS_radflRequestData : 7|64@0+ (1,0) [0|0] "" Vector__XXX

BO_ 1653 UDS_radfrRequest: 8 GTW
 SG_ UDS_radfrRequestData : 7|64@0+ (1,0) [0|0] "" Vector__XXX

BO_ 1650 UDS_radrlRequest: 8 GTW
 SG_ UDS_radrlRequestData : 7|64@0+ (1,0) [0|0] "" Vector__XXX

BO_ 1651 UDS_radrrRequest: 8 GTW
 SG_ UDS_radrrRequestData : 7|64@0+ (1,0) [0|0] "" Vector__XXX

BO_ 2033 UDS_rcmDisposalRequest: 8 GTW
 SG_ UDS_rcmDisposalRequestData : 7|64@0+ (1,0) [0|0] "" RCM,OCS

BO_ 1601 UDS_rcmRequest: 8 GTW
 SG_ UDS_rcmRequestData : 7|64@0+ (1,0) [0|0] "" RCM

BO_ 1936 UDS_sccmRequest: 8 GTW
 SG_ UDS_sccmRequestData : 7|64@0+ (1,0) [0|0] "" SCCM

BO_ 1611 UDS_tasRequest: 8 GTW
 SG_ UDS_tasRequestData_H : 7|32@0+ (1,0) [0|4294967295] "" TAS
 SG_ UDS_tasRequestData_L : 39|32@0+ (1,0) [0|4294967295] "" TAS

BO_ 1615 UDS_tpmsRequest: 8 GTW
 SG_ UDS_tpmsRequestData : 7|64@0+ (1,0) [0|0] "" TPMS

BO_ 1760 UDS_vcseatdRequest: 8 DBG
 SG_ UDS_vcseatdRequestData_H : 7|32@0+ (1,0) [0|4294967295] "" VCSEATD
 SG_ UDS_vcseatdRequestData_L : 39|32@0+ (1,0) [0|4294967295] "" VCSEATD

BO_ 1762 UDS_vcseatpRequest: 8 DBG
 SG_ UDS_vcseatpRequestData_H : 7|32@0+ (1,0) [0|4294967295] "" VCSEATP
 SG_ UDS_vcseatpRequestData_L : 39|32@0+ (1,0) [0|4294967295] "" VCSEATP

BO_ 1006 UI_autopilotControl: 8 GTW
 SG_ UI_autopilotControlIndex M : 0|3@1+ (1,0) [0|7] "" APP,APS
 SG_ UI_hovEnabled m0 : 3|1@1+ (1,0) [0|0] "" APP,APS
 SG_ UI_donDisableAutoWiperDuration m0 : 4|3@1+ (1,0) [0|0] "" APP,APS
 SG_ UI_donDisableOnAutoWiperSpeed m0 : 7|4@1+ (1,0) [0|0] "" APP,APS
 SG_ UI_blindspotMinSpeed m0 : 11|4@1+ (1,0) [0|0] "" APP,APS
 SG_ UI_blindspotDistance m0 : 15|3@1+ (1,0) [0|0] "" APP,APS
 SG_ UI_blindspotTTC m0 : 18|3@1+ (1,0) [0|0] "" APP,APS
 SG_ UI_donStopEndOfRampBuffer m0 : 21|3@1+ (1,0) [0|0] "" APP,APS
 SG_ UI_donDisableCutin m0 : 24|1@1+ (1,0) [0|0] "" APP,APS
 SG_ UI_donMinGoreWidthForAbortMap m0 : 25|4@1+ (1,0) [0|0] "" APP,APS
 SG_ UI_donAlcProgGoreAbortThres m0 : 29|4@1+ (1,0) [0|0] "" APP,APS
 SG_ UI_donMinGoreWidthForAbortNotMap m0 : 33|4@1+ (1,0) [0|0] "" APP,APS
 SG_ UI_fsdVisualizationEnabled m0 : 37|1@1+ (1,0) [0|1] "" APP
 SG_ UI_fsdStopsControlEnabled m0 : 38|1@1+ (1,0) [0|1] "" APP
 SG_ UI_homelinkNearby m0 : 45|1@1+ (1,0) [0|0] "" APP,APS
 SG_ UI_driverMonitorConfirmation m1 : 17|1@1+ (1,0) [0|0] "" APP,APS
 SG_ UI_applyEceR79 m1 : 19|1@1+ (1,0) [0|0] "" APP,APS
 SG_ UI_enableMapStops m1 : 20|1@1+ (1,0) [0|0] "" APP,APS
 SG_ UI_disableMain m1 : 23|1@1+ (1,0) [0|0] "" APP,APS
 SG_ UI_disableNarrow m1 : 24|1@1+ (1,0) [0|0] "" APP,APS
 SG_ UI_disableFisheye m1 : 25|1@1+ (1,0) [0|0] "" APP,APS
 SG_ UI_disableLeftPillar m1 : 26|1@1+ (1,0) [0|0] "" APP,APS
 SG_ UI_disableRightPillar m1 : 27|1@1+ (1,0) [0|0] "" APP,APS
 SG_ UI_disableLeftRepeater m1 : 28|1@1+ (1,0) [0|0] "" APP,APS
 SG_ UI_disableRightRepeater m1 : 29|1@1+ (1,0) [0|0] "" APP,APS
 SG_ UI_disableBackup m1 : 30|1@1+ (1,0) [0|0] "" APP,APS
 SG_ UI_disableRadar m1 : 31|1@1+ (1,0) [0|0] "" APP,APS
 SG_ UI_noStalkConfirmAlertHaptic m1 : 32|1@1+ (1,0) [0|0] "" APP,APS
 SG_ UI_ulcSnooze m1 : 36|1@1+ (1,0) [0|0] "" APP,APS
 SG_ UI_noStalkConfirmAlertChime m1 : 37|1@1+ (1,0) [0|0] "" APP,APS
 SG_ UI_cameraPoweringOff m1 : 38|1@1+ (1,0) [0|0] "" APP,APS
 SG_ UI_factorySummonEnable m1 : 39|1@1+ (1,0) [0|0] "" APP,APS
 SG_ UI_apmv3Branch m1 : 40|3@1+ (1,0) [0|7] "" APP,APS
 SG_ UI_enableAutopilotStopWarning m1 : 44|1@1+ (1,0) [0|1] "" APP,APS
 SG_ UI_showLaneGraph m1 : 45|1@1+ (1,0) [0|1] "" APP,APS
 SG_ UI_showTrackLabels m1 : 46|1@1+ (1,0) [0|1] "" APP,APS
 SG_ UI_hardCoreSummon m1 : 47|1@1+ (1,0) [0|1] "" APP,APS

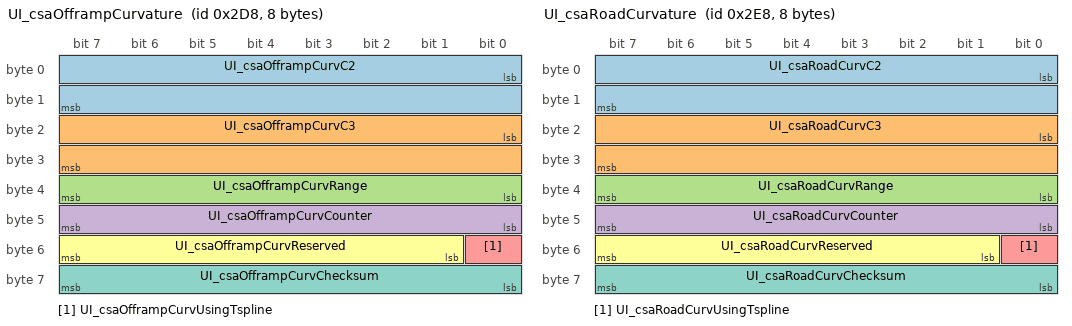
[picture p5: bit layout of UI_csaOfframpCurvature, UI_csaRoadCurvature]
BO_ 728 UI_csaOfframpCurvature: 8 GTW
 SG_ UI_csaOfframpCurvC2 : 0|16@1- (1E-06,0) [-0.032768|0.032767] "1/m" DAS
 SG_ UI_csaOfframpCurvC3 : 16|16@1- (4E-09,0) [-0.000131072|0.000131068] "1/m2" DAS
 SG_ UI_csaOfframpCurvRange : 32|8@1+ (2,0) [0|510] "m" DAS
 SG_ UI_csaOfframpCurvCounter : 40|8@1+ (1,0) [0|255] "" Vector__XXX
 SG_ UI_csaOfframpCurvUsingTspline : 48|1@1+ (1,0) [0|1] "" DAS
 SG_ UI_csaOfframpCurvReserved : 49|7@1+ (1,0) [0|0] "" Vector__XXX
 SG_ UI_csaOfframpCurvChecksum : 56|8@1+ (1,0) [0|0] "" Vector__XXX

BO_ 744 UI_csaRoadCurvature: 8 GTW
 SG_ UI_csaRoadCurvC2 : 0|16@1- (1E-06,0) [-0.032768|0.032767] "1/m" DAS
 SG_ UI_csaRoadCurvC3 : 16|16@1- (4E-09,0) [-0.000131072|0.000131068] "1/m2" DAS
 SG_ UI_csaRoadCurvRange : 32|8@1+ (2,0) [0|510] "m" DAS
 SG_ UI_csaRoadCurvCounter : 40|8@1+ (1,0) [0|255] "" Vector__XXX
 SG_ UI_csaRoadCurvUsingTspline : 48|1@1+ (1,0) [0|1] "" DAS
 SG_ UI_csaRoadCurvReserved : 49|7@1+ (1,0) [0|0] "" Vector__XXX
 SG_ UI_csaRoadCurvChecksum : 56|8@1+ (1,0) [0|0] "" Vector__XXX

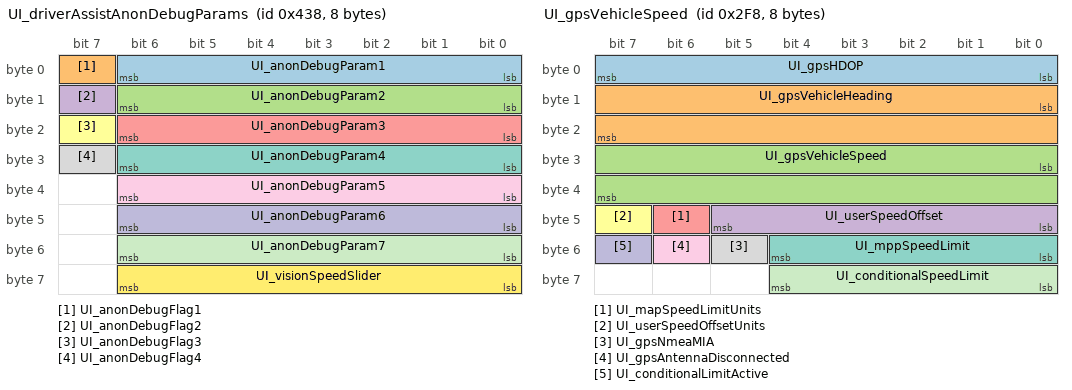
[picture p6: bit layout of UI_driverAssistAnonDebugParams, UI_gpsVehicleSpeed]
BO_ 1080 UI_driverAssistAnonDebugParams: 8 GTW
 SG_ UI_anonDebugParam1 : 0|7@1+ (1,0) [0|100] "" DAS
 SG_ UI_anonDebugFlag1 : 7|1@1+ (1,0) [0|0] "" DAS
 SG_ UI_anonDebugParam2 : 8|7@1+ (1,0) [0|100] "" DAS
 SG_ UI_anonDebugFlag2 : 15|1@1+ (1,0) [0|0] "" DAS
 SG_ UI_anonDebugParam3 : 16|7@1+ (1,0) [0|100] "" DAS
 SG_ UI_anonDebugFlag3 : 23|1@1+ (1,0) [0|0] "" DAS
 SG_ UI_anonDebugParam4 : 24|7@1+ (1,0) [0|100] "" DAS
 SG_ UI_anonDebugFlag4 : 31|1@1+ (1,0) [0|0] "" DAS
 SG_ UI_anonDebugParam5 : 32|7@1+ (1,0) [0|100] "" DAS
 SG_ UI_anonDebugParam6 : 40|7@1+ (1,0) [0|100] "" DAS
 SG_ UI_anonDebugParam7 : 48|7@1+ (1,0) [0|100] "" DAS
 SG_ UI_visionSpeedSlider : 56|7@1+ (1,0) [0|100] "" DAS

BO_ 1000 UI_driverAssistControl: 8 GTW
 SG_ UI_autopilotControlRequest : 0|1@1+ (1,0) [1|0] "" DAS
 SG_ UI_ulcStalkConfirm : 1|1@1+ (1,0) [1|0] "" DAS
 SG_ UI_summonHeartbeat : 2|2@1+ (1,0) [0|0] "" DAS
 SG_ UI_curvSpeedAdaptDisable : 4|1@1+ (1,0) [0|0] "" DAS
 SG_ UI_dasDeveloper : 5|1@1+ (1,0) [0|0] "" DAS
 SG_ UI_enableVinAssociation : 6|1@1+ (1,0) [0|0] "" DAS
 SG_ UI_lssLkaEnabled : 7|1@1+ (1,0) [0|0] "" DAS
 SG_ UI_lssLdwEnabled : 8|1@1+ (1,0) [0|0] "" DAS
 SG_ UI_coastToCoast : 9|1@1+ (1,0) [0|1] "" APP
 SG_ UI_autoSummonEnable : 10|1@1+ (1,0) [0|1] "" DAS
 SG_ UI_exceptionListEnable : 11|1@1+ (1,0) [0|1] "" APP
 SG_ UI_roadCheckDisable : 12|1@1+ (1,0) [0|0] "" DAS
 SG_ UI_driveOnMapsEnable : 13|1@1+ (1,0) [0|0] "" DAS
 SG_ UI_handsOnRequirementDisable : 14|1@1+ (1,0) [0|0] "" DAS
 SG_ UI_fuseLanesDisable : 16|1@1+ (1,0) [0|0] "" DAS
 SG_ UI_fuseHPPDisable : 17|1@1+ (1,0) [0|0] "" DAS
 SG_ UI_fuseVehiclesDisable : 18|1@1+ (1,0) [0|0] "" DAS
 SG_ UI_visionSpeedType : 20|2@1+ (1,0) [0|0] "" APP
 SG_ UI_curvatureDatabaseOnly : 22|1@1+ (1,0) [0|0] "" DAS
 SG_ UI_lssElkEnabled : 23|1@1+ (1,0) [0|0] "" DAS
 SG_ UI_summonExitType : 24|2@1+ (1,0) [0|3] "" DAS
 SG_ UI_summonEntryType : 26|2@1+ (1,0) [0|3] "" DAS
 SG_ UI_selfParkRequest : 28|4@1+ (1,0) [0|15] "" DAS,PARK
 SG_ UI_summonReverseDist : 32|6@1+ (1,0) [0|63] "" DAS
 SG_ UI_undertakeAssistEnable : 38|1@1+ (1,0) [0|0] "" DAS
 SG_ UI_adaptiveSetSpeedEnable : 39|1@1+ (1,0) [0|0] "" DAS
 SG_ UI_drivingSide : 40|2@1+ (1,0) [0|3] "" DAS
 SG_ UI_enableClipTelemetry : 42|1@1+ (1,0) [0|0] "" APP
 SG_ UI_enableTripTelemetry : 43|1@1+ (1,0) [0|0] "" APP
 SG_ UI_enableRoadSegmentTelemetry : 44|1@1+ (1,0) [0|0] "" APP
 SG_ UI_followNavRouteEnable : 46|1@1+ (1,0) [0|0] "" APP
 SG_ UI_hasDriveOnNav : 47|1@1+ (1,0) [0|0] "" APP
 SG_ UI_ulcSpeedConfig : 48|2@1+ (1,0) [0|3] "" APP
 SG_ UI_ulcBlindSpotConfig : 50|2@1+ (1,0) [0|3] "" APP
 SG_ UI_alcOffHighwayEnable : 54|1@1+ (1,0) [0|1] "" APP
 SG_ UI_validationLoop : 55|1@1+ (1,0) [0|1] "" APP
 SG_ UI_ulcOffHighway : 56|1@1+ (1,0) [0|1] "" APP
 SG_ UI_smartSummonType : 57|2@1+ (1,0) [0|0] "" APP
 SG_ UI_bluetoothDeviceInRange : 59|1@1+ (1,0) [0|1] "" DAS
 SG_ UI_source3D : 60|3@1+ (1,0) [0|7] "" APP
 SG_ UI_enableVisionOnlyStops : 63|1@1+ (1,0) [0|1] "" APP

BO_ 968 UI_driverAssistMapData: 8 GTW
 SG_ UI_mapSpeedLimitDependency : 0|3@1+ (1,0) [0|0] "" DAS
 SG_ UI_roadClass : 3|3@1+ (1,0) [0|0] "" DAS
 SG_ UI_inSuperchargerGeofence : 6|1@1+ (1,0) [0|0] "" DAS
 SG_ UI_mapSpeedUnits : 7|1@1+ (1,0) [0|0] "" DAS
 SG_ UI_mapSpeedLimit : 8|5@1+ (1,0) [0|0] "" DAS
 SG_ UI_mapSpeedLimitType : 13|3@1+ (1,0) [0|0] "" DAS
 SG_ UI_countryCode : 16|10@1+ (1,0) [0|0] "" DAS
 SG_ UI_streetCount : 26|2@1+ (1,0) [0|0] "" DAS
 SG_ UI_gpsRoadMatch : 28|1@1+ (1,0) [0|0] "" DAS
 SG_ UI_navRouteActive : 29|1@1+ (1,0) [0|0] "" DAS
 SG_ UI_parallelAutoparkEnabled : 30|1@1+ (1,0) [0|1] "" DAS
 SG_ UI_perpendicularAutoparkEnabled : 31|1@1+ (1,0) [0|1] "" DAS
 SG_ UI_nextBranchDist : 32|5@1+ (10,0) [0|300] "m" DAS
 SG_ UI_controlledAccess : 37|1@1+ (1,0) [0|0] "" DAS,TAS
 SG_ UI_nextBranchLeftOffRamp : 38|1@1+ (1,0) [0|0] "" DAS
 SG_ UI_nextBranchRightOffRamp : 39|1@1+ (1,0) [0|0] "" DAS
 SG_ UI_rejectLeftLane : 40|1@1+ (1,0) [0|0] "" DAS
 SG_ UI_rejectRightLane : 41|1@1+ (1,0) [0|0] "" DAS
 SG_ UI_rejectHPP : 42|1@1+ (1,0) [0|0] "" DAS
 SG_ UI_rejectNav : 43|1@1+ (1,0) [0|0] "" DAS
 SG_ UI_rejectLeftFreeSpace : 44|1@1+ (1,0) [0|0] "" DAS
 SG_ UI_rejectRightFreeSpace : 45|1@1+ (1,0) [0|0] "" DAS
 SG_ UI_rejectAutosteer : 46|1@1+ (1,0) [0|0] "" DAS
 SG_ UI_rejectHandsOn : 47|1@1+ (1,0) [0|0] "" DAS
 SG_ UI_acceptBottsDots : 48|1@1+ (1,0) [0|0] "" DAS
 SG_ UI_autosteerRestricted : 49|1@1+ (1,0) [0|0] "" DAS
 SG_ UI_pmmEnabled : 50|1@1+ (1,0) [0|0] "" DAS
 SG_ UI_scaEnabled : 51|1@1+ (1,0) [0|0] "" DAS
 SG_ UI_mapDataCounter : 52|4@1+ (1,0) [0|0] "" DAS
 SG_ UI_mapDataChecksum : 56|8@1+ (1,0) [0|0] "" DAS

BO_ 568 UI_driverAssistRoadSign: 8 GTW
 SG_ UI_roadSign M : 0|8@1+ (1,0) [0|0] "" DAS
 SG_ UI_splineLocConfidence : 40|7@1+ (1,0) [0|100] "" DAS
 SG_ UI_splineID : 48|4@1+ (1,0) [0|15] "" Vector__XXX
 SG_ UI_roadSignCounter : 52|4@1+ (1,0) [0|0] "" Vector__XXX
 SG_ UI_roadSignChecksum : 56|8@1+ (1,0) [0|0] "" Vector__XXX
 SG_ UI_dummyData m0 : 8|1@1+ (1,0) [0|0] "" Vector__XXX
 SG_ UI_stopSignStopLineDist m1 : 8|10@1+ (0.25,-8) [-8|247.5] "m" Vector__XXX
 SG_ UI_stopSignStopLineConf m1 : 18|7@1+ (1,0) [0|100] "" Vector__XXX
 SG_ UI_trafficLightStopLineDist m2 : 8|10@1+ (0.25,-8) [-8|247.5] "m" Vector__XXX
 SG_ UI_trafficLightStopLineConf m2 : 18|7@1+ (1,0) [0|100] "" Vector__XXX
 SG_ UI_baseMapSpeedLimitMPS m3 : 8|8@1+ (0.25,0) [0|63.75] "m/s" DAS
 SG_ UI_bottomQrtlFleetSpeedMPS m3 : 16|8@1+ (0.25,0) [0|63.75] "m/s" DAS
 SG_ UI_topQrtlFleetSpeedMPS m3 : 24|8@1+ (0.25,0) [0|63.75] "m/s" DAS
 SG_ UI_meanFleetSplineSpeedMPS m4 : 8|8@1+ (0.25,0) [0|63.75] "m/s" DAS
 SG_ UI_medianFleetSpeedMPS m4 : 16|8@1+ (0.25,0) [0|63.75] "m/s" DAS
 SG_ UI_meanFleetSplineAccelMPS2 m4 : 24|8@1+ (0.05,-6.35) [-6.35|6.4] "m/s^2" DAS
 SG_ UI_rampType m4 : 32|3@1+ (1,0) [0|7] "" DAS
 SG_ UI_valhallaRamp m4 : 35|2@1+ (1,0) [0|3] "" APP
 SG_ UI_overRideACM m4 : 37|1@1+ (1,0) [0|1] "" APP
 SG_ UI_overrideACMFleetSpeed m4 : 38|1@1+ (1,0) [0|1] "" APP
 SG_ UI_currSplineIdFull m5 : 8|32@1+ (1,0) [0|1] "" APP

BO_ 641 UI_driverProfileRecall: 8 GTW
 SG_ UI_driverProfileRecallIndex M : 0|3@1+ (1,0) [0|5] "" VCSEATD
 SG_ UI_driverProfileRecallStop : 3|1@1+ (1,0) [0|1] "" VCSEATD
 SG_ UI_frontSeatRecallActive m1 : 4|1@1+ (1,0) [0|1] "" VCSEATD
 SG_ UI_frontSeatTrackPos m1 : 5|10@1- (4,0) [-2048|2044] "mm" VCSEATD
 SG_ UI_frontSeatBackPos m1 : 16|12@1- (0.1,0) [-204.8|204.7] "deg" VCSEATD
 SG_ UI_frontSeatLiftPos m1 : 32|10@1- (4,0) [-2048|2044] "mm" VCSEATD
 SG_ UI_frontSeatTiltPos m1 : 48|12@1- (0.1,0) [-204.8|204.7] "deg" VCSEATD
 SG_ UI_columnAndLumbarRecallActive m2 : 4|1@1+ (1,0) [0|1] "" VCSEATD
 SG_ UI_lumbarAPressureHpa m2 : 16|16@1+ (1,0) [0|65535] "" VCSEATD
 SG_ UI_lumbarBPressureHpa m2 : 32|16@1+ (1,0) [0|65535] "" VCSEATD

BO_ 760 UI_gpsVehicleSpeed: 8 GTW
 SG_ UI_gpsHDOP : 0|8@1+ (0.1,0) [0|25.5] "1" DAS
 SG_ UI_gpsVehicleHeading : 8|16@1+ (0.0078125,0) [0|511.9921875] "deg" DAS
 SG_ UI_gpsVehicleSpeed : 24|16@1+ (0.00390625,0) [0|250.996] "km/hr" Vector__XXX
 SG_ UI_userSpeedOffset : 40|6@1+ (1,-30) [-30|33] "kph/mph" DAS
 SG_ UI_mapSpeedLimitUnits : 46|1@1+ (1,0) [0|1] "" DAS
 SG_ UI_userSpeedOffsetUnits : 47|1@1+ (1,0) [0|1] "" DAS
 SG_ UI_mppSpeedLimit : 48|5@1+ (5,0) [0|155] "kph/mph" DAS
 SG_ UI_gpsNmeaMIA : 53|1@1+ (1,0) [0|0] "" DAS
 SG_ UI_gpsAntennaDisconnected : 54|1@1+ (1,0) [0|0] "" DAS
 SG_ UI_conditionalLimitActive : 55|1@1+ (1,0) [0|1] "" APP
 SG_ UI_conditionalSpeedLimit : 56|5@1+ (5,0) [0|150] "kph/mph" APP

BO_ 990 UI_locationOffset: 8 GTW
 SG_ UI_latitudeOffset : 0|28@1- (1E-06,0) [0|0] "deg" APS,APP
 SG_ UI_longitudeOffset : 28|29@1- (1E-06,0) [0|0] "deg" APS,APP

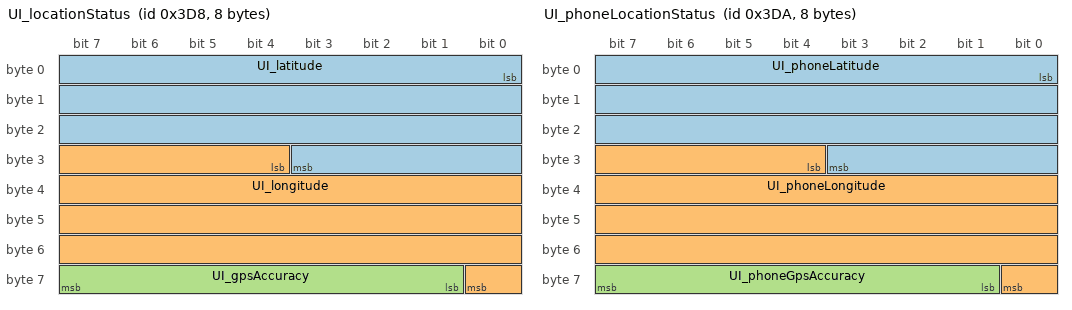
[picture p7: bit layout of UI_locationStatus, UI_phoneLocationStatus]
BO_ 984 UI_locationStatus: 8 GTW
 SG_ UI_latitude : 0|28@1- (1E-06,0) [0|0] "deg" DAS
 SG_ UI_longitude : 28|29@1- (1E-06,0) [0|0] "deg" DAS
 SG_ UI_gpsAccuracy : 57|7@1+ (0.2,0) [0|0] "m" DAS

BO_ 986 UI_phoneLocationStatus: 8 GTW
 SG_ UI_phoneLatitude : 0|28@1- (1E-06,0) [0|0] "deg" APS,APP
 SG_ UI_phoneLongitude : 28|29@1- (1E-06,0) [0|0] "deg" APS,APP
 SG_ UI_phoneGpsAccuracy : 57|7@1+ (0.5,0) [0|0] "m" APP

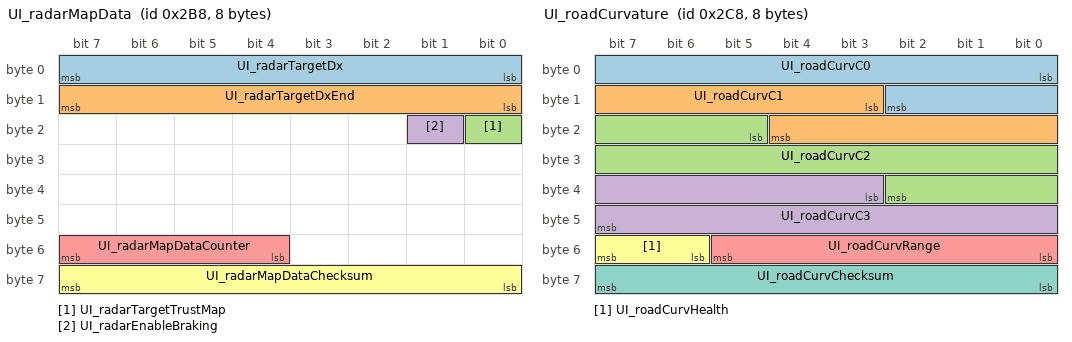
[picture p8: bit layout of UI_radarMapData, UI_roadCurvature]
BO_ 696 UI_radarMapData: 8 GTW
 SG_ UI_radarTargetDx : 0|8@1+ (1,-95) [-95|160] "m" DAS
 SG_ UI_radarTargetDxEnd : 8|8@1+ (1,0) [0|255] "m" DAS
 SG_ UI_radarTargetTrustMap : 16|1@1+ (1,0) [0|1] "" DAS
 SG_ UI_radarEnableBraking : 17|1@1+ (1,0) [0|1] "" DAS
 SG_ UI_radarMapDataCounter : 52|4@1+ (1,0) [0|0] "" DAS
 SG_ UI_radarMapDataChecksum : 56|8@1+ (1,0) [0|0] "" DAS

BO_ 712 UI_roadCurvature: 8 GTW
 SG_ UI_roadCurvC0 : 0|11@1- (0.02,0) [-20.48|20.46] "m" DAS
 SG_ UI_roadCurvC1 : 11|10@1- (0.00075,0) [-0.384|0.38325] "1" DAS
 SG_ UI_roadCurvC2 : 21|14@1- (7.5E-06,0) [-0.03072|0.03071625] "1/m" DAS
 SG_ UI_roadCurvC3 : 35|13@1- (3E-08,0) [-0.00012288|0.00012285] "1/m2" DAS
 SG_ UI_roadCurvRange : 48|6@1+ (4,0) [0|252] "m" DAS
 SG_ UI_roadCurvHealth : 54|2@1+ (1,0) [0|0] "" DAS
 SG_ UI_roadCurvChecksum : 56|8@1+ (1,0) [0|0] "" Vector__XXX

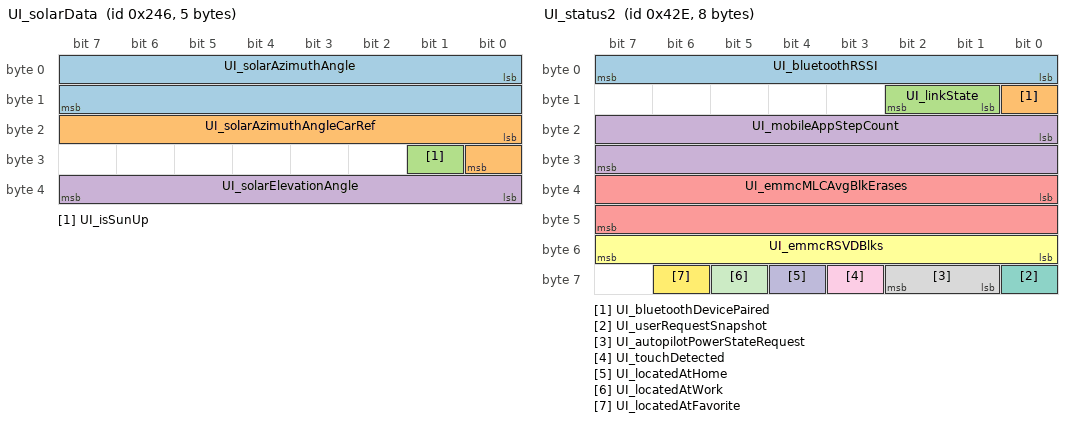
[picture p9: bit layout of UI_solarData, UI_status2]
BO_ 582 UI_solarData: 5 GTW
 SG_ UI_solarAzimuthAngle : 0|16@1- (1,0) [0|360] "deg" Vector__XXX
 SG_ UI_solarAzimuthAngleCarRef : 16|9@1- (1,0) [-180|180] "deg" Vector__XXX
 SG_ UI_isSunUp : 25|1@1+ (1,0) [0|0] "" Vector__XXX
 SG_ UI_solarElevationAngle : 32|8@1- (1,0) [-90|90] "deg" APP

BO_ 824 UI_status: 8 GTW
 SG_ UI_touchActive : 0|1@1+ (1,0) [0|0] "" IC
 SG_ UI_audioActive : 1|1@1+ (1,0) [0|0] "" IC,APP
 SG_ UI_bluetoothActive : 2|1@1+ (1,0) [0|0] "" IC
 SG_ UI_cellActive : 3|1@1+ (1,0) [0|0] "" IC
 SG_ UI_displayReady : 4|1@1+ (1,0) [0|0] "" IC
 SG_ UI_gpsActive : 5|1@1+ (1,0) [0|0] "" IC
 SG_ UI_wifiConnected : 6|1@1+ (1,0) [0|0] "" IC,APP
 SG_ UI_systemActive : 7|1@1+ (1,0) [0|0] "" IC
 SG_ UI_xmActive : 8|1@1+ (1,0) [0|0] "" IC
 SG_ UI_displayOn : 9|1@1+ (1,0) [0|0] "" IC,APP
 SG_ UI_readyForDrive : 10|1@1+ (1,0) [0|0] "" IC
 SG_ UI_cellConnected : 11|1@1+ (1,0) [0|0] "" IC,APP
 SG_ UI_vpnActive : 12|1@1+ (1,0) [0|0] "" IC,APP
 SG_ UI_wifiActive : 13|1@1+ (1,0) [0|0] "" IC
 SG_ UI_cameraActive : 14|1@1+ (1,0) [0|0] "" IC,APP
 SG_ UI_usbActive : 15|1@1+ (1,0) [0|0] "" IC
 SG_ UI_screenshotActive : 16|1@1+ (1,0) [0|0] "" IC,APP
 SG_ UI_monitorModemPower : 17|1@1+ (1,0) [0|0] "" Vector__XXX
 SG_ UI_factoryReset : 18|2@1+ (1,0) [0|3] "" Vector__XXX
 SG_ UI_cellNetworkTechnology : 20|4@1+ (1,0) [0|15] "" APP
 SG_ UI_tegraCoreTemperature : 24|8@1+ (1,-64) [0|0] "deg C" IC
 SG_ UI_tegraAmbientTemperature : 32|8@1+ (1,-64) [0|0] "deg C" IC
 SG_ UI_googleWifiUsages : 40|8@1+ (1,0) [0|0] "" Vector__XXX
 SG_ UI_autopilotTrial : 48|2@1+ (1,0) [0|0] "" APP
 SG_ UI_cellSignalBars : 50|3@1+ (1,0) [0|7] "" APP
 SG_ UI_hardwareType : 53|2@1+ (1,0) [0|3] "" DAS
 SG_ UI_developmentCar : 55|1@1+ (1,0) [0|0] "" Vector__XXX
 SG_ UI_cellReceiverPower : 56|8@1+ (1,-128) [-128|127] "dB" APP

BO_ 1070 UI_status2: 8 GTW
 SG_ UI_bluetoothRSSI : 0|8@1+ (1,-254) [-254|1] "dB" APP
 SG_ UI_bluetoothDevicePaired : 8|1@1+ (1,0) [0|1] "" APP
 SG_ UI_linkState : 9|2@1+ (1,0) [0|2] "" APP
 SG_ UI_mobileAppStepCount : 16|16@1+ (1,0) [0|65535] "" APP
 SG_ UI_emmcMLCAvgBlkErases : 32|16@1+ (1,0) [0|8191] "" Vector__XXX
 SG_ UI_emmcRSVDBlks : 48|8@1+ (1,0) [0|255] "" Vector__XXX
 SG_ UI_userRequestSnapshot : 56|1@1+ (1,0) [0|1] "" APP
 SG_ UI_autopilotPowerStateRequest : 57|2@1+ (1,0) [0|2] "" APP,APS
 SG_ UI_touchDetected : 59|1@1+ (1,0) [0|1] "" APP
 SG_ UI_locatedAtHome : 60|1@1+ (1,0) [0|1] "" APP
 SG_ UI_locatedAtWork : 61|1@1+ (1,0) [0|1] "" APP
 SG_ UI_locatedAtFavorite : 62|1@1+ (1,0) [0|1] "" APP

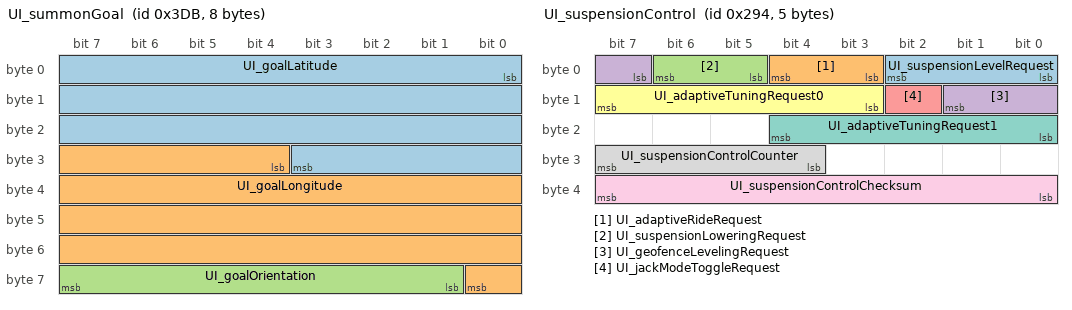
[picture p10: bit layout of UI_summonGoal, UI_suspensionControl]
BO_ 987 UI_summonGoal: 8 GTW
 SG_ UI_goalLatitude : 0|28@1- (1E-06,0) [0|0] "deg" APS,APP
 SG_ UI_goalLongitude : 28|29@1- (1E-06,0) [0|0] "deg" APS,APP
 SG_ UI_goalOrientation : 57|7@1+ (2.8125,0) [0|357.1875] "deg" APS,APP

BO_ 660 UI_suspensionControl: 5 GTW
 SG_ UI_suspensionLevelRequest : 0|3@1+ (1,0) [0|7] "" TAS
 SG_ UI_adaptiveRideRequest : 3|2@1+ (1,0) [0|3] "" TAS
 SG_ UI_suspensionLoweringRequest : 5|2@1+ (1,0) [0|3] "" TAS
 SG_ UI_geofenceLevelingRequest : 7|3@1+ (1,0) [0|5] "" TAS
 SG_ UI_jackModeToggleRequest : 10|1@1+ (1,0) [0|1] "" TAS
 SG_ UI_adaptiveTuningRequest0 : 11|5@1- (0.1,0) [-1|1] "-" TAS
 SG_ UI_adaptiveTuningRequest1 : 16|5@1- (0.1,0) [-1|1] "-" TAS
 SG_ UI_suspensionControlCounter : 28|4@1+ (1,0) [0|15] "" TAS
 SG_ UI_suspensionControlChecksum : 32|8@1+ (1,0) [0|255] "" TAS

BO_ 1064 UI_telemetryControl: 8 GTW
 SG_ UI_TCR_enable : 0|1@1+ (1,0) [0|0] "" DAS
 SG_ UI_TCR_moveStateStanding : 1|1@1+ (1,0) [0|0] "" DAS
 SG_ UI_TCR_moveStateStopped : 2|1@1+ (1,0) [0|0] "" DAS
 SG_ UI_TCR_moveStateMoving : 3|1@1+ (1,0) [0|0] "" DAS
 SG_ UI_TCR_moveStateIndeterm : 4|1@1+ (1,0) [0|0] "" DAS
 SG_ UI_TCR_classConstElem : 5|1@1+ (1,0) [0|0] "" DAS
 SG_ UI_TCR_classMovingPed : 6|1@1+ (1,0) [0|0] "" DAS
 SG_ UI_TCR_classMovingTwoWheel : 7|1@1+ (1,0) [0|0] "" DAS
 SG_ UI_TCR_classMovingFourWheel : 8|1@1+ (1,0) [0|0] "" DAS
 SG_ UI_TCR_classUnknown : 9|1@1+ (1,0) [0|0] "" DAS
 SG_ UI_TCR_downSampleFactor : 16|4@1+ (1,0) [0|15] "" Vector__XXX
 SG_ UI_TCR_wExist : 24|5@1+ (1,0) [0|31] "" Vector__XXX
 SG_ UI_TCR_vehSpeed : 32|8@1+ (1,0) [0|0] "" Vector__XXX
 SG_ UI_TCR_minRCS : 40|8@1+ (0.25,-14) [-14|49.75] "dB" Vector__XXX
 SG_ UI_TCR_maxDy : 48|5@1+ (0.5,0) [0|15.5] "m" Vector__XXX
 SG_ UI_TCR_maxObjects : 56|5@1+ (1,0) [0|31] "" Vector__XXX
 SG_ UI_TCR_maxRoadClass : 61|3@1+ (1,0) [0|7] "" Vector__XXX

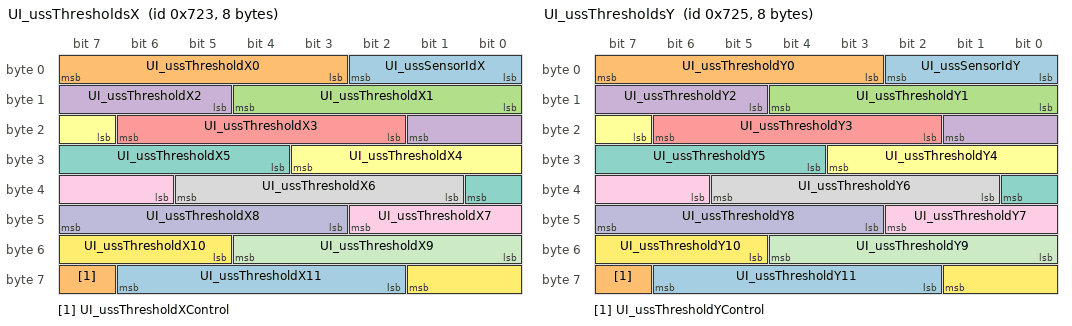
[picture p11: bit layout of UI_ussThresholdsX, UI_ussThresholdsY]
BO_ 1827 UI_ussThresholdsX: 8 GTW
 SG_ UI_ussSensorIdX : 0|3@1+ (1,0) [0|7] "" APS
 SG_ UI_ussThresholdX0 : 3|5@1+ (1,0) [0|31] "" APS
 SG_ UI_ussThresholdX1 : 8|5@1+ (1,0) [0|31] "" APS
 SG_ UI_ussThresholdX2 : 13|5@1+ (1,0) [0|31] "" APS
 SG_ UI_ussThresholdX3 : 18|5@1+ (1,0) [0|31] "" APS
 SG_ UI_ussThresholdX4 : 23|5@1+ (1,0) [0|31] "" APS
 SG_ UI_ussThresholdX5 : 28|5@1+ (1,0) [0|31] "" APS
 SG_ UI_ussThresholdX6 : 33|5@1+ (1,0) [0|31] "" APS
 SG_ UI_ussThresholdX7 : 38|5@1+ (1,0) [0|31] "" APS
 SG_ UI_ussThresholdX8 : 43|5@1+ (1,0) [0|31] "" APS
 SG_ UI_ussThresholdX9 : 48|5@1+ (1,0) [0|31] "" APS
 SG_ UI_ussThresholdX10 : 53|5@1+ (1,0) [0|31] "" APS
 SG_ UI_ussThresholdX11 : 58|5@1+ (1,0) [0|31] "" APS
 SG_ UI_ussThresholdXControl : 63|1@1+ (1,0) [0|1] "" APS

BO_ 1829 UI_ussThresholdsY: 8 GTW
 SG_ UI_ussSensorIdY : 0|3@1+ (1,0) [0|7] "" APS
 SG_ UI_ussThresholdY0 : 3|5@1+ (1,0) [0|31] "" APS
 SG_ UI_ussThresholdY1 : 8|5@1+ (1,0) [0|31] "" APS
 SG_ UI_ussThresholdY2 : 13|5@1+ (1,0) [0|31] "" APS
 SG_ UI_ussThresholdY3 : 18|5@1+ (1,0) [0|31] "" APS
 SG_ UI_ussThresholdY4 : 23|5@1+ (1,0) [0|31] "" APS
 SG_ UI_ussThresholdY5 : 28|5@1+ (1,0) [0|31] "" APS
 SG_ UI_ussThresholdY6 : 33|5@1+ (1,0) [0|31] "" APS
 SG_ UI_ussThresholdY7 : 38|5@1+ (1,0) [0|31] "" APS
 SG_ UI_ussThresholdY8 : 43|5@1+ (1,0) [0|31] "" APS
 SG_ UI_ussThresholdY9 : 48|5@1+ (1,0) [0|31] "" APS
 SG_ UI_ussThresholdY10 : 53|5@1+ (1,0) [0|31] "" APS
 SG_ UI_ussThresholdY11 : 58|5@1+ (1,0) [0|31] "" APS
 SG_ UI_ussThresholdYControl : 63|1@1+ (1,0) [0|1] "" APS

BO_ 627 UI_vehicleControl: 6 GTW
 SG_ UI_driverSeatHeatReq : 42|2@1+ (1,0) [0|3] "" VCSEATD
 SG_ UI_passengerSeatHeatReq : 44|2@1+ (1,0) [0|3] "" VCSEATP

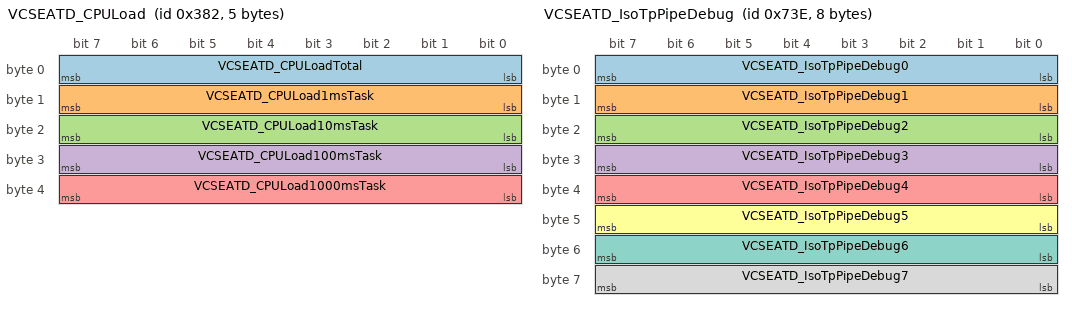
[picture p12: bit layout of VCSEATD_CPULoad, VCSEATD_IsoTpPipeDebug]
BO_ 898 VCSEATD_CPULoad: 5 VCSEATD
 SG_ VCSEATD_CPULoadTotal : 0|8@1+ (1,0) [0|255] "" Vector__XXX
 SG_ VCSEATD_CPULoad1msTask : 8|8@1+ (1,0) [0|255] "" Vector__XXX
 SG_ VCSEATD_CPULoad10msTask : 16|8@1+ (1,0) [0|255] "" Vector__XXX
 SG_ VCSEATD_CPULoad100msTask : 24|8@1+ (1,0) [0|255] "" Vector__XXX
 SG_ VCSEATD_CPULoad1000msTask : 32|8@1+ (1,0) [0|255] "" Vector__XXX

BO_ 1854 VCSEATD_IsoTpPipeDebug: 8 VCSEATD
 SG_ VCSEATD_IsoTpPipeDebug0 : 0|8@1+ (1,0) [0|255] "" Vector__XXX
 SG_ VCSEATD_IsoTpPipeDebug1 : 8|8@1+ (1,0) [0|255] "" Vector__XXX
 SG_ VCSEATD_IsoTpPipeDebug2 : 16|8@1+ (1,0) [0|255] "" Vector__XXX
 SG_ VCSEATD_IsoTpPipeDebug3 : 24|8@1+ (1,0) [0|255] "" Vector__XXX
 SG_ VCSEATD_IsoTpPipeDebug4 : 32|8@1+ (1,0) [0|255] "" Vector__XXX
 SG_ VCSEATD_IsoTpPipeDebug5 : 40|8@1+ (1,0) [0|255] "" Vector__XXX
 SG_ VCSEATD_IsoTpPipeDebug6 : 48|8@1+ (1,0) [0|255] "" Vector__XXX
 SG_ VCSEATD_IsoTpPipeDebug7 : 56|8@1+ (1,0) [0|255] "" Vector__XXX

BO_ 578 VCSEATD_LVPowerState: 1 VCSEATD
 SG_ VCSEATD_lumbarLVState : 0|2@1+ (1,0) [0|3] "" GTW

BO_ 1314 VCSEATD_alertCleared: 2 VCSEATD
 SG_ VCSEATD_alertClearedID : 0|15@1+ (1,0) [0|445] "" Vector__XXX

BO_ 1373 VCSEATD_alertLog: 8 VCSEATD
 SG_ VCSEATD_alertID M : 0|15@1+ (1,0) [0|445] "" GTW
 SG_ VCSEATD_alertType : 15|1@1+ (1,0) [0|1] "" GTW
 SG_ VCSEATD_a000_alertDataW0 m0 : 16|16@1+ (1,0) [0|65535] "" Vector__XXX
 SG_ VCSEATD_a000_alertDataW1 m0 : 32|16@1+ (1,0) [0|65535] "" Vector__XXX
 SG_ VCSEATD_a000_alertDataW2 m0 : 48|16@1+ (1,0) [0|65535] "" Vector__XXX
 SG_ VCSEATD_a001_InternalWatchdog m1 : 16|1@1+ (1,0) [0|1] "" GTW
 SG_ VCSEATD_a002_CPUUndervoltage m2 : 16|1@1+ (1,0) [0|1] "" GTW
 SG_ VCSEATD_a002_PowerOnReset m2 : 17|1@1+ (1,0) [0|1] "" GTW
 SG_ VCSEATD_a003_AssertID m3 : 16|16@1+ (1,0) [0|65535] "" GTW
 SG_ VCSEATD_a003_LineNumber m3 : 32|16@1+ (1,0) [0|65535] "" GTW
 SG_ VCSEATD_a003_Data m3 : 48|16@1+ (1,0) [0|65535] "" GTW
 SG_ VCSEATD_a005_busID0 m5 : 16|4@1+ (1,0) [0|15] "" GTW
 SG_ VCSEATD_a005_faults0 m5 : 20|12@1+ (1,0) [0|4095] "" GTW
 SG_ VCSEATD_a005_busID1 m5 : 32|4@1+ (1,0) [0|15] "" GTW
 SG_ VCSEATD_a005_faults1 m5 : 36|12@1+ (1,0) [0|4095] "" GTW
 SG_ VCSEATD_a010_UnderVoltDetected m10 : 16|1@1+ (1,0) [0|1] "" GTW
 SG_ VCSEATD_a010_UnderVoltTimeout m10 : 17|1@1+ (1,0) [0|1] "" GTW
 SG_ VCSEATD_a012_ClockError m12 : 16|1@1+ (1,0) [0|1] "" GTW
 SG_ VCSEATD_a012_FlashError m12 : 17|1@1+ (1,0) [0|1] "" GTW
 SG_ VCSEATD_a012_SoftwareReset m12 : 18|1@1+ (1,0) [0|1] "" GTW
 SG_ VCSEATD_a012_CheckstopReset m12 : 19|1@1+ (1,0) [0|1] "" GTW
 SG_ VCSEATD_a012_DebugReset m12 : 20|1@1+ (1,0) [0|1] "" GTW
 SG_ VCSEATD_a012_ExternalReset m12 : 21|1@1+ (1,0) [0|1] "" GTW
 SG_ VCSEATD_a013_LogQueueFull m13 : 16|1@1+ (1,0) [0|1] "" GTW
 SG_ VCSEATD_a013_ClearQueueFull m13 : 17|1@1+ (1,0) [0|1] "" GTW
 SG_ VCSEATD_a015_NVMMRecordNotFound m15 : 16|1@1+ (1,0) [0|1] "" GTW
 SG_ VCSEATD_a015_NVMMCRCMismatch m15 : 17|1@1+ (1,0) [0|1] "" GTW
 SG_ VCSEATD_a015_NVMMVersionMismatch m15 : 18|1@1+ (1,0) [0|1] "" GTW
 SG_ VCSEATD_a015_NVMMRecordUpgraded m15 : 19|1@1+ (1,0) [0|1] "" GTW
 SG_ VCSEATD_a015_NVMMMemOverflow m15 : 20|1@1+ (1,0) [0|1] "" GTW
 SG_ VCSEATD_a015_NVMMWriteFailed m15 : 21|1@1+ (1,0) [0|1] "" GTW
 SG_ VCSEATD_a021_Task1msLate m21 : 16|1@1+ (1,0) [0|1] "" GTW
 SG_ VCSEATD_a021_Task1msStarved m21 : 17|1@1+ (1,0) [0|1] "" GTW
 SG_ VCSEATD_a021_Task1msMissed m21 : 18|1@1+ (1,0) [0|1] "" GTW
 SG_ VCSEATD_a021_Task10msLate m21 : 19|1@1+ (1,0) [0|1] "" GTW
 SG_ VCSEATD_a021_Task10msStarved m21 : 20|1@1+ (1,0) [0|1] "" GTW
 SG_ VCSEATD_a021_Task10msMissed m21 : 21|1@1+ (1,0) [0|1] "" GTW
 SG_ VCSEATD_a021_Task100msLate m21 : 22|1@1+ (1,0) [0|1] "" GTW
 SG_ VCSEATD_a021_Task100msStarved m21 : 23|1@1+ (1,0) [0|1] "" GTW
 SG_ VCSEATD_a021_Task100msMissed m21 : 24|1@1+ (1,0) [0|1] "" GTW
 SG_ VCSEATD_a021_Task1000msLate m21 : 25|1@1+ (1,0) [0|1] "" GTW
 SG_ VCSEATD_a021_Task1000msStarved m21 : 26|1@1+ (1,0) [0|1] "" GTW
 SG_ VCSEATD_a021_Task1000msMissed m21 : 27|1@1+ (1,0) [0|1] "" GTW
 SG_ VCSEATD_a022_TaskInitErrorCount m22 : 16|8@1+ (1,0) [0|255] "" GTW
 SG_ VCSEATD_a022_TaskInitError0 m22 : 24|8@1+ (1,0) [0|255] "" GTW
 SG_ VCSEATD_a022_TaskInitError1 m22 : 32|8@1+ (1,0) [0|255] "" GTW
 SG_ VCSEATD_a022_TaskInitError2 m22 : 40|8@1+ (1,0) [0|255] "" GTW
 SG_ VCSEATD_a022_TaskInitError3 m22 : 48|8@1+ (1,0) [0|255] "" GTW
 SG_ VCSEATD_a022_TaskInitError4 m22 : 56|8@1+ (1,0) [0|255] "" GTW
 SG_ VCSEATD_a030_logId m30 : 16|4@1+ (1,0) [0|15] "" GTW
 SG_ VCSEATD_a031_uds_bytes_0 m31 : 16|8@1+ (1,0) [0|255] "" GTW
 SG_ VCSEATD_a031_uds_bytes_1 m31 : 24|8@1+ (1,0) [0|255] "" GTW
 SG_ VCSEATD_a031_uds_bytes_2 m31 : 32|8@1+ (1,0) [0|255] "" GTW
 SG_ VCSEATD_a031_uds_bytes_3 m31 : 40|8@1+ (1,0) [0|255] "" GTW
 SG_ VCSEATD_a031_uds_bytes_4 m31 : 48|8@1+ (1,0) [0|255] "" GTW
 SG_ VCSEATD_a031_uds_bytes_5 m31 : 56|8@1+ (1,0) [0|255] "" GTW
 SG_ VCSEATD_a041_CPULoadTotal m41 : 16|8@1+ (1,0) [0|255] "" GTW
 SG_ VCSEATD_a041_CPULoad1msTask m41 : 24|8@1+ (1,0) [0|255] "" GTW
 SG_ VCSEATD_a041_CPULoad10msTask m41 : 32|8@1+ (1,0) [0|255] "" GTW
 SG_ VCSEATD_a041_CPULoad100msTask m41 : 40|8@1+ (1,0) [0|255] "" GTW
 SG_ VCSEATD_a041_CPULoad1000msTask m41 : 48|8@1+ (1,0) [0|255] "" GTW
 SG_ VCSEATD_a041_CPULoadNVMMTask m41 : 56|8@1+ (1,0) [0|255] "" GTW
 SG_ VCSEATD_a042_Usage1msTask m42 : 16|8@1+ (1,0) [0|255] "" GTW
 SG_ VCSEATD_a042_Usage10msTask m42 : 24|8@1+ (1,0) [0|255] "" GTW
 SG_ VCSEATD_a042_Usage100msTask m42 : 32|8@1+ (1,0) [0|255] "" GTW
 SG_ VCSEATD_a042_Usage1000msTask m42 : 40|8@1+ (1,0) [0|255] "" GTW
 SG_ VCSEATD_a042_UsageUDSTask m42 : 48|8@1+ (1,0) [0|255] "" GTW
 SG_ VCSEATD_a042_UsageNVMMTask m42 : 56|8@1+ (1,0) [0|255] "" GTW
 SG_ VCSEATD_a043_CallTrace0 m43 : 16|24@1+ (1,0) [0|16777215] "" GTW
 SG_ VCSEATD_a043_CallTrace1 m43 : 40|24@1+ (1,0) [0|16777215] "" GTW
 SG_ VCSEATD_a044_CallTrace0 m44 : 16|24@1+ (1,0) [0|16777215] "" GTW
 SG_ VCSEATD_a044_CallTrace1 m44 : 40|24@1+ (1,0) [0|16777215] "" GTW
 SG_ VCSEATD_a045_CallTrace0 m45 : 16|24@1+ (1,0) [0|16777215] "" GTW
 SG_ VCSEATD_a045_CallTrace1 m45 : 40|24@1+ (1,0) [0|16777215] "" GTW
 SG_ VCSEATD_a046_CallTrace0 m46 : 16|24@1+ (1,0) [0|16777215] "" GTW
 SG_ VCSEATD_a046_CallTrace1 m46 : 40|24@1+ (1,0) [0|16777215] "" GTW
 SG_ VCSEATD_a058_voltageDrop m58 : 16|12@1+ (0.005443676098,0) [0|22.29185362131] "V" GTW
 SG_ VCSEATD_a058_current m58 : 28|11@1+ (0.1,0) [0|204.7] "A" GTW
 SG_ VCSEATD_a058_prevREstimate m58 : 39|12@1+ (0.00061,0) [0|2.49795] "Ohms" GTW
 SG_ VCSEATD_a058_newREstimate m58 : 51|12@1+ (0.00061,0) [0|2.49795] "Ohms" GTW
 SG_ VCSEATD_a058_faultReason m58 : 63|1@1+ (1,0) [0|1] "" GTW
 SG_ VCSEATD_a059_voltageDrop m59 : 16|12@1+ (0.005443676098,0) [0|22.29185362131] "V" GTW
 SG_ VCSEATD_a059_resistanceEstimate m59 : 28|12@1+ (0.00244,0) [0|9.9918] "Ohms" GTW
 SG_ VCSEATD_a059_current m59 : 40|12@1+ (0.05,0) [0|204.75] "A" GTW
 SG_ VCSEATD_a060_lockoutDisabled m60 : 16|1@1+ (1,0) [0|1] "" GTW
 SG_ VCSEATD_a060_resetUnlocked m60 : 17|1@1+ (1,0) [0|1] "" GTW
 SG_ VCSEATD_a063_switchChannel m63 : 16|8@1+ (1,0) [0|255] "" GTW
 SG_ VCSEATD_a063_switchType m63 : 24|8@1+ (1,0) [0|255] "" GTW
 SG_ VCSEATD_a063_ADCVoltage m63 : 32|8@1+ (0.025,0) [0|6.375] "V" GTW
 SG_ VCSEATD_a063_disconnected m63 : 40|1@1+ (1,0) [0|1] "" GTW
 SG_ VCSEATD_a063_indeterminate m63 : 41|1@1+ (1,0) [0|1] "" GTW
 SG_ VCSEATD_a063_stuckActive m63 : 42|1@1+ (1,0) [0|1] "" GTW
 SG_ VCSEATD_a063_faulted m63 : 43|1@1+ (1,0) [0|1] "" GTW
 SG_ VCSEATD_a064_busBitField m64 : 16|8@1+ (1,0) [0|255] "" GTW
 SG_ VCSEATD_a200_voltage m200 : 16|7@1+ (0.15,0) [0|19] "V" GTW
 SG_ VCSEATD_a200_motorChannels m200 : 23|16@1+ (1,0) [0|65535] "" GTW
 SG_ VCSEATD_a200_encoderVoltage m200 : 39|6@1+ (0.15,0) [0|9] "V" GTW
 SG_ VCSEATD_a200_encoder8vEn m200 : 45|1@1+ (1,0) [0|1] "" GTW
 SG_ VCSEATD_a200_motorPosition m200 : 46|7@1+ (20,0) [0|2540] "ticks" GTW
 SG_ VCSEATD_a200_phantomTicks m200 : 53|11@1- (1,0) [-1024|1023] "ticks" GTW
 SG_ VCSEATD_a201_voltage m201 : 16|7@1+ (0.15,0) [0|19] "V" GTW
 SG_ VCSEATD_a201_motorChannels m201 : 24|16@1+ (1,0) [0|65535] "" GTW
 SG_ VCSEATD_a218_motorChannels m218 : 16|16@1+ (1,0) [0|65535] "" GTW
 SG_ VCSEATD_a218_voltage m218 : 32|10@1+ (0.02,0) [0|19] "V" GTW
 SG_ VCSEATD_a218_motorCurrent m218 : 42|10@1- (0.04,0) [-20|20] "A" GTW
 SG_ VCSEATD_a218_motorDutyCycle m218 : 52|10@1+ (0.1,0) [0|100] "A" GTW
 SG_ VCSEATD_a219_motorChannels m219 : 16|16@1+ (1,0) [0|65535] "" GTW
 SG_ VCSEATD_a219_dropoutCount m219 : 32|12@1+ (1,0) [0|4095] "" GTW
 SG_ VCSEATD_a220_seatMotorCalibrated m220 : 16|1@1+ (1,0) [0|1] "" GTW
 SG_ VCSEATD_a220_seatMotorCurrent m220 : 17|12@1- (0.01,0) [-20.48|20.47] "A" GTW
 SG_ VCSEATD_a220_seatMotorPosReal m220 : 32|12@1- (1,0) [-2048|2047] "mm" GTW
 SG_ VCSEATD_a220_seatMotorState m220 : 44|3@1+ (1,0) [0|5] "" GTW
 SG_ VCSEATD_a220_seatSwitchBack m220 : 48|2@1+ (1,0) [0|3] "" GTW
 SG_ VCSEATD_a220_seatSwitchForward m220 : 50|2@1+ (1,0) [0|3] "" GTW
 SG_ VCSEATD_a221_seatMotorCalibrated m221 : 16|1@1+ (1,0) [0|1] "" GTW
 SG_ VCSEATD_a221_seatMotorCurrent m221 : 17|12@1- (0.01,0) [-20.48|20.47] "A" GTW
 SG_ VCSEATD_a221_seatMotorPosReal m221 : 32|12@1- (1,0) [-2048|2047] "mm" GTW
 SG_ VCSEATD_a221_seatMotorState m221 : 44|3@1+ (1,0) [0|5] "" GTW
 SG_ VCSEATD_a221_seatSwitchBack m221 : 48|2@1+ (1,0) [0|3] "" GTW
 SG_ VCSEATD_a221_seatSwitchForward m221 : 50|2@1+ (1,0) [0|3] "" GTW
 SG_ VCSEATD_a222_seatMotorCalibrated m222 : 16|1@1+ (1,0) [0|1] "" GTW
 SG_ VCSEATD_a222_seatMotorCurrent m222 : 17|12@1- (0.01,0) [-20.48|20.47] "A" GTW
 SG_ VCSEATD_a222_seatMotorPosReal m222 : 32|12@1- (1,0) [-2048|2047] "mm" GTW
 SG_ VCSEATD_a222_seatMotorState m222 : 44|3@1+ (1,0) [0|5] "" GTW
 SG_ VCSEATD_a222_seatSwitchBack m222 : 48|2@1+ (1,0) [0|3] "" GTW
 SG_ VCSEATD_a222_seatSwitchForward m222 : 50|2@1+ (1,0) [0|3] "" GTW
 SG_ VCSEATD_a223_seatMotorCalibrated m223 : 16|1@1+ (1,0) [0|1] "" GTW
 SG_ VCSEATD_a223_seatMotorCurrent m223 : 17|12@1- (0.01,0) [-20.48|20.47] "A" GTW
 SG_ VCSEATD_a223_seatMotorPosReal m223 : 32|12@1- (1,0) [-2048|2047] "mm" GTW
 SG_ VCSEATD_a223_seatMotorState m223 : 44|3@1+ (1,0) [0|5] "" GTW
 SG_ VCSEATD_a223_seatSwitchBack m223 : 48|2@1+ (1,0) [0|3] "" GTW
 SG_ VCSEATD_a223_seatSwitchForward m223 : 50|2@1+ (1,0) [0|3] "" GTW
 SG_ VCSEATD_a224_seatMotorCalibrated m224 : 16|1@1+ (1,0) [0|1] "" GTW
 SG_ VCSEATD_a224_seatMotorCurrent m224 : 17|12@1- (0.01,0) [-20.48|20.47] "A" GTW
 SG_ VCSEATD_a224_seatMotorState m224 : 29|3@1+ (1,0) [0|5] "" GTW
 SG_ VCSEATD_a224_seatSwitchBack m224 : 32|2@1+ (1,0) [0|3] "" GTW
 SG_ VCSEATD_a224_seatSwitchForward m224 : 34|2@1+ (1,0) [0|3] "" GTW
 SG_ VCSEATD_a225_seatMotorCalibrated m225 : 16|1@1+ (1,0) [0|1] "" GTW
 SG_ VCSEATD_a225_seatMotorCurrent m225 : 17|12@1- (0.01,0) [-20.48|20.47] "A" GTW
 SG_ VCSEATD_a225_seatMotorState m225 : 29|3@1+ (1,0) [0|5] "" GTW
 SG_ VCSEATD_a225_seatSwitchBack m225 : 32|2@1+ (1,0) [0|3] "" GTW
 SG_ VCSEATD_a225_seatSwitchForward m225 : 34|2@1+ (1,0) [0|3] "" GTW
 SG_ VCSEATD_a226_seatMotorCalibrated m226 : 16|1@1+ (1,0) [0|1] "" GTW
 SG_ VCSEATD_a226_seatMotorCurrent m226 : 17|12@1- (0.01,0) [-20.48|20.47] "A" GTW
 SG_ VCSEATD_a226_seatMotorState m226 : 29|3@1+ (1,0) [0|5] "" GTW
 SG_ VCSEATD_a226_seatSwitchBack m226 : 32|2@1+ (1,0) [0|3] "" GTW
 SG_ VCSEATD_a226_seatSwitchForward m226 : 34|2@1+ (1,0) [0|3] "" GTW
 SG_ VCSEATD_a227_seatMotorCalibrated m227 : 16|1@1+ (1,0) [0|1] "" GTW
 SG_ VCSEATD_a227_seatMotorCurrent m227 : 17|12@1- (0.01,0) [-20.48|20.47] "A" GTW
 SG_ VCSEATD_a227_seatMotorState m227 : 29|3@1+ (1,0) [0|5] "" GTW
 SG_ VCSEATD_a227_seatSwitchBack m227 : 32|2@1+ (1,0) [0|3] "" GTW
 SG_ VCSEATD_a227_seatSwitchForward m227 : 34|2@1+ (1,0) [0|3] "" GTW
 SG_ VCSEATD_a228_seatMotorCalibrated m228 : 16|1@1+ (1,0) [0|1] "" GTW
 SG_ VCSEATD_a228_seatMotorCurrent m228 : 17|12@1- (0.01,0) [-20.48|20.47] "A" GTW
 SG_ VCSEATD_a228_seatMotorPosReal m228 : 32|12@1- (1,0) [-2048|2047] "mm" GTW
 SG_ VCSEATD_a228_seatMotorState m228 : 44|3@1+ (1,0) [0|5] "" GTW
 SG_ VCSEATD_a228_seatSwitchBack m228 : 48|2@1+ (1,0) [0|3] "" GTW
 SG_ VCSEATD_a228_seatSwitchForward m228 : 50|2@1+ (1,0) [0|3] "" GTW
 SG_ VCSEATD_a229_seatMotorCalibrated m229 : 16|1@1+ (1,0) [0|1] "" GTW
 SG_ VCSEATD_a229_seatMotorCurrent m229 : 17|12@1- (0.01,0) [-20.48|20.47] "A" GTW
 SG_ VCSEATD_a229_seatMotorPosReal m229 : 32|12@1- (1,0) [-2048|2047] "mm" GTW
 SG_ VCSEATD_a229_seatMotorState m229 : 44|3@1+ (1,0) [0|5] "" GTW
 SG_ VCSEATD_a229_seatSwitchBack m229 : 48|2@1+ (1,0) [0|3] "" GTW
 SG_ VCSEATD_a229_seatSwitchForward m229 : 50|2@1+ (1,0) [0|3] "" GTW
 SG_ VCSEATD_a230_seatMotorCalibrated m230 : 16|1@1+ (1,0) [0|1] "" GTW
 SG_ VCSEATD_a230_seatMotorCurrent m230 : 17|12@1- (0.01,0) [-20.48|20.47] "A" GTW
 SG_ VCSEATD_a230_seatMotorPosReal m230 : 32|12@1- (1,0) [-2048|2047] "mm" GTW
 SG_ VCSEATD_a230_seatMotorState m230 : 44|3@1+ (1,0) [0|5] "" GTW
 SG_ VCSEATD_a230_seatSwitchBack m230 : 48|2@1+ (1,0) [0|3] "" GTW
 SG_ VCSEATD_a230_seatSwitchForward m230 : 50|2@1+ (1,0) [0|3] "" GTW
 SG_ VCSEATD_a231_seatMotorCalibrated m231 : 16|1@1+ (1,0) [0|1] "" GTW
 SG_ VCSEATD_a231_seatMotorCurrent m231 : 17|12@1- (0.01,0) [-20.48|20.47] "A" GTW
 SG_ VCSEATD_a231_seatMotorPosReal m231 : 32|12@1- (1,0) [-2048|2047] "mm" GTW
 SG_ VCSEATD_a231_seatMotorState m231 : 44|3@1+ (1,0) [0|5] "" GTW
 SG_ VCSEATD_a231_seatSwitchBack m231 : 48|2@1+ (1,0) [0|3] "" GTW
 SG_ VCSEATD_a231_seatSwitchForward m231 : 50|2@1+ (1,0) [0|3] "" GTW
 SG_ VCSEATD_a232_seatMotorCurrent m232 : 16|12@1- (0.01,0) [-20.48|20.47] "A" GTW
 SG_ VCSEATD_a232_seatMotorPosReal m232 : 28|12@1- (1,0) [-2048|2047] "mm" GTW
 SG_ VCSEATD_a232_seatMotorState m232 : 40|3@1+ (1,0) [0|5] "" GTW
 SG_ VCSEATD_a232_seatSwitchBack m232 : 43|2@1+ (1,0) [0|3] "" GTW
 SG_ VCSEATD_a232_seatSwitchForward m232 : 45|2@1+ (1,0) [0|3] "" GTW
 SG_ VCSEATD_a233_seatMotorCurrent m233 : 16|12@1- (0.01,0) [-20.48|20.47] "A" GTW
 SG_ VCSEATD_a233_seatMotorPosReal m233 : 28|12@1- (1,0) [-2048|2047] "mm" GTW
 SG_ VCSEATD_a233_seatMotorState m233 : 40|3@1+ (1,0) [0|5] "" GTW
 SG_ VCSEATD_a233_seatSwitchBack m233 : 43|2@1+ (1,0) [0|3] "" GTW
 SG_ VCSEATD_a233_seatSwitchForward m233 : 45|2@1+ (1,0) [0|3] "" GTW
 SG_ VCSEATD_a234_seatMotorCurrent m234 : 16|12@1- (0.01,0) [-20.48|20.47] "A" GTW
 SG_ VCSEATD_a234_seatMotorPosReal m234 : 28|12@1- (1,0) [-2048|2047] "mm" GTW
 SG_ VCSEATD_a234_seatMotorState m234 : 40|3@1+ (1,0) [0|5] "" GTW
 SG_ VCSEATD_a234_seatSwitchBack m234 : 43|2@1+ (1,0) [0|3] "" GTW
 SG_ VCSEATD_a234_seatSwitchForward m234 : 45|2@1+ (1,0) [0|3] "" GTW
 SG_ VCSEATD_a235_seatMotorCurrent m235 : 16|12@1- (0.01,0) [-20.48|20.47] "A" GTW
 SG_ VCSEATD_a235_seatMotorPosReal m235 : 28|12@1- (1,0) [-2048|2047] "mm" GTW
 SG_ VCSEATD_a235_seatMotorState m235 : 40|3@1+ (1,0) [0|5] "" GTW
 SG_ VCSEATD_a235_seatSwitchBack m235 : 43|2@1+ (1,0) [0|3] "" GTW
 SG_ VCSEATD_a235_seatSwitchForward m235 : 45|2@1+ (1,0) [0|3] "" GTW
 SG_ VCSEATD_a236_lumbarAPressureHpa m236 : 16|16@1+ (1,0) [0|65535] "" GTW
 SG_ VCSEATD_a236_lumbarBPressureHpa m236 : 32|16@1+ (1,0) [0|65535] "" GTW
 SG_ VCSEATD_a236_lumbarDiagStatus m236 : 48|1@1+ (1,0) [0|1] "" GTW
 SG_ VCSEATD_a236_lumbarAState m236 : 49|3@1+ (1,0) [0|5] "" GTW
 SG_ VCSEATD_a236_lumbarBState m236 : 52|3@1+ (1,0) [0|5] "" GTW
 SG_ VCSEATD_a237_lumbarAPressureHpa m237 : 16|16@1+ (1,0) [0|65535] "" GTW
 SG_ VCSEATD_a237_lumbarBPressureHpa m237 : 32|16@1+ (1,0) [0|65535] "" GTW
 SG_ VCSEATD_a237_lumbarDiagStatus m237 : 48|1@1+ (1,0) [0|1] "" GTW
 SG_ VCSEATD_a237_lumbarAState m237 : 49|3@1+ (1,0) [0|5] "" GTW
 SG_ VCSEATD_a237_lumbarBState m237 : 52|3@1+ (1,0) [0|5] "" GTW
 SG_ VCSEATD_a238_lumbarAPressureHpa m238 : 16|16@1+ (1,0) [0|65535] "" GTW
 SG_ VCSEATD_a238_lumbarBPressureHpa m238 : 32|16@1+ (1,0) [0|65535] "" GTW
 SG_ VCSEATD_a238_lumbarDiagStatus m238 : 48|1@1+ (1,0) [0|1] "" GTW
 SG_ VCSEATD_a238_lumbarAState m238 : 49|3@1+ (1,0) [0|5] "" GTW
 SG_ VCSEATD_a238_lumbarBState m238 : 52|3@1+ (1,0) [0|5] "" GTW
 SG_ VCSEATD_a239_seatHeatCurrent m239 : 16|12@1+ (0.01,0) [0|40.95] "A" GTW
 SG_ VCSEATD_a239_seatHeatTmp m239 : 28|12@1- (0.05,0) [-40|80] "degC" GTW
 SG_ VCSEATD_a239_seatHeatTmpTarget m239 : 40|8@1- (0.5,0) [0|60] "degC" GTW
 SG_ VCSEATD_a240_seatHeatCurrent m240 : 16|12@1+ (0.01,0) [0|40.95] "A" GTW
 SG_ VCSEATD_a240_seatHeatTmp m240 : 28|12@1- (0.05,0) [-40|80] "degC" GTW
 SG_ VCSEATD_a241_seatHeatTmp m241 : 16|12@1- (0.05,0) [-40|80] "degC" GTW
 SG_ VCSEATD_a241_seatHeatTmpTarget m241 : 32|8@1- (0.5,0) [0|60] "degC" GTW
 SG_ VCSEATD_a242_snsShortCircuit m242 : 16|1@1+ (1,0) [0|1] "" GTW
 SG_ VCSEATD_a242_snsDisconnect m242 : 17|1@1+ (1,0) [0|1] "" GTW
 SG_ VCSEATD_a242_snsRateChangeUp m242 : 18|1@1+ (1,0) [0|1] "" GTW
 SG_ VCSEATD_a242_snsRateChangeDown m242 : 19|1@1+ (1,0) [0|1] "" GTW
 SG_ VCSEATD_a251_seatMotorCurrent m251 : 16|12@1- (0.01,0) [-20.48|20.47] "A" GTW
 SG_ VCSEATD_a251_seatMotorPosReal m251 : 28|12@1- (1,0) [-2048|2047] "mm" GTW
 SG_ VCSEATD_a251_seatMotorState m251 : 40|3@1+ (1,0) [0|5] "" GTW
 SG_ VCSEATD_a251_seatSwitchBack m251 : 43|2@1+ (1,0) [0|3] "" GTW
 SG_ VCSEATD_a251_seatSwitchForward m251 : 45|2@1+ (1,0) [0|3] "" GTW
 SG_ VCSEATD_a252_seatMotorCurrent m252 : 16|12@1- (0.01,0) [-20.48|20.47] "A" GTW
 SG_ VCSEATD_a252_seatMotorPosReal m252 : 28|12@1- (1,0) [-2048|2047] "mm" GTW
 SG_ VCSEATD_a252_seatMotorState m252 : 40|3@1+ (1,0) [0|5] "" GTW
 SG_ VCSEATD_a252_seatSwitchBack m252 : 43|2@1+ (1,0) [0|3] "" GTW
 SG_ VCSEATD_a252_seatSwitchForward m252 : 45|2@1+ (1,0) [0|3] "" GTW
 SG_ VCSEATD_a253_seatMotorCurrent m253 : 16|12@1- (0.01,0) [-20.48|20.47] "A" GTW
 SG_ VCSEATD_a253_seatMotorPosReal m253 : 28|12@1- (1,0) [-2048|2047] "mm" GTW
 SG_ VCSEATD_a253_seatMotorState m253 : 40|3@1+ (1,0) [0|5] "" GTW
 SG_ VCSEATD_a253_seatSwitchBack m253 : 43|2@1+ (1,0) [0|3] "" GTW
 SG_ VCSEATD_a253_seatSwitchForward m253 : 45|2@1+ (1,0) [0|3] "" GTW
 SG_ VCSEATD_a254_seatMotorCurrent m254 : 16|12@1- (0.01,0) [-20.48|20.47] "A" GTW
 SG_ VCSEATD_a254_seatMotorPosReal m254 : 28|12@1- (1,0) [-2048|2047] "mm" GTW
 SG_ VCSEATD_a254_seatMotorState m254 : 40|3@1+ (1,0) [0|5] "" GTW
 SG_ VCSEATD_a254_seatSwitchBack m254 : 43|2@1+ (1,0) [0|3] "" GTW
 SG_ VCSEATD_a254_seatSwitchForward m254 : 45|2@1+ (1,0) [0|3] "" GTW
 SG_ VCSEATD_a263_seatMotorCurrent m263 : 16|12@1- (0.01,0) [-20.48|20.47] "A" GTW
 SG_ VCSEATD_a263_seatMotorDCurrent m263 : 28|12@1- (0.01,0) [-20.48|20.47] "A" GTW
 SG_ VCSEATD_a263_seatMotorPosReal m263 : 40|12@1- (1,0) [-2048|2047] "mm" GTW
 SG_ VCSEATD_a263_seatMotorState m263 : 52|3@1+ (1,0) [0|5] "" GTW
 SG_ VCSEATD_a264_seatMotorCurrent m264 : 16|12@1- (0.01,0) [-20.48|20.47] "A" GTW
 SG_ VCSEATD_a264_seatMotorDCurrent m264 : 28|12@1- (0.01,0) [-20.48|20.47] "A" GTW
 SG_ VCSEATD_a264_seatMotorPosReal m264 : 40|12@1- (1,0) [-2048|2047] "mm" GTW
 SG_ VCSEATD_a264_seatMotorState m264 : 52|3@1+ (1,0) [0|5] "" GTW
 SG_ VCSEATD_a265_seatMotorCurrent m265 : 16|12@1- (0.01,0) [-20.48|20.47] "A" GTW
 SG_ VCSEATD_a265_seatMotorDCurrent m265 : 28|12@1- (0.01,0) [-20.48|20.47] "A" GTW
 SG_ VCSEATD_a265_seatMotorPosReal m265 : 40|12@1- (1,0) [-2048|2047] "mm" GTW
 SG_ VCSEATD_a265_seatMotorState m265 : 52|3@1+ (1,0) [0|5] "" GTW
 SG_ VCSEATD_a266_seatMotorCurrent m266 : 16|12@1- (0.01,0) [-20.48|20.47] "A" GTW
 SG_ VCSEATD_a266_seatMotorDCurrent m266 : 28|12@1- (0.01,0) [-20.48|20.47] "A" GTW
 SG_ VCSEATD_a266_seatMotorPosReal m266 : 40|12@1- (1,0) [-2048|2047] "mm" GTW
 SG_ VCSEATD_a266_seatMotorState m266 : 52|3@1+ (1,0) [0|5] "" GTW
 SG_ VCSEATD_a267_seatMotorCurrent m267 : 16|12@1- (0.01,0) [-20.48|20.47] "A" GTW
 SG_ VCSEATD_a267_seatMotorDCurrent m267 : 28|12@1- (0.01,0) [-20.48|20.47] "A" GTW
 SG_ VCSEATD_a267_seatMotorPosReal m267 : 40|12@1- (1,0) [-2048|2047] "mm" GTW
 SG_ VCSEATD_a267_seatMotorState m267 : 52|3@1+ (1,0) [0|5] "" GTW
 SG_ VCSEATD_a268_seatMotorCurrent m268 : 16|12@1- (0.01,0) [-20.48|20.47] "A" GTW
 SG_ VCSEATD_a268_seatMotorDCurrent m268 : 28|12@1- (0.01,0) [-20.48|20.47] "A" GTW
 SG_ VCSEATD_a268_seatMotorPosReal m268 : 40|12@1- (1,0) [-2048|2047] "mm" GTW
 SG_ VCSEATD_a268_seatMotorState m268 : 52|3@1+ (1,0) [0|5] "" GTW
 SG_ VCSEATD_a269_seatMotorCurrent m269 : 16|12@1- (0.01,0) [-20.48|20.47] "A" GTW
 SG_ VCSEATD_a269_seatMotorDCurrent m269 : 28|12@1- (0.01,0) [-20.48|20.47] "A" GTW
 SG_ VCSEATD_a269_seatMotorPosReal m269 : 40|12@1- (1,0) [-2048|2047] "mm" GTW
 SG_ VCSEATD_a269_seatMotorState m269 : 52|3@1+ (1,0) [0|5] "" GTW
 SG_ VCSEATD_a270_seatMotorCurrent m270 : 16|12@1- (0.01,0) [-20.48|20.47] "A" GTW
 SG_ VCSEATD_a270_seatMotorDCurrent m270 : 28|12@1- (0.01,0) [-20.48|20.47] "A" GTW
 SG_ VCSEATD_a270_seatMotorPosReal m270 : 40|12@1- (1,0) [-2048|2047] "mm" GTW
 SG_ VCSEATD_a270_seatMotorState m270 : 52|3@1+ (1,0) [0|5] "" GTW
 SG_ VCSEATD_a290_occupancySensorV m290 : 16|12@1- (0.01,0) [-20.48|20.47] "V" GTW
 SG_ VCSEATD_a290_railVoltage m290 : 28|12@1- (0.01,0) [-20.48|20.47] "V" GTW
 SG_ VCSEATD_a291_buckleSensorVoltage m291 : 16|12@1+ (0.01,0) [0|40.95] "V" GTW
 SG_ VCSEATD_a291_railVoltage m291 : 28|12@1+ (0.01,0) [0|40.95] "V" GTW
 SG_ VCSEATD_a380_ocsCushionRaw m380 : 16|16@1+ (1,0) [0|65535] "" GTW
 SG_ VCSEATD_a380_ocsSpareRaw m380 : 32|16@1+ (1,0) [0|65535] "" GTW
 SG_ VCSEATD_a380_ocsTempRaw m380 : 48|9@1+ (0.5,-45) [-45|130] "degC" GTW
 SG_ VCSEATD_a380_ocsHumidityRaw m380 : 57|7@1+ (1,0) [0|100] "%" GTW
 SG_ VCSEATD_a381_ocsCushionRaw m381 : 16|16@1+ (1,0) [0|65535] "" GTW
 SG_ VCSEATD_a381_ocsSpareRaw m381 : 32|16@1+ (1,0) [0|65535] "" GTW
 SG_ VCSEATD_a381_ocsTempRaw m381 : 48|9@1+ (0.5,-45) [-45|130] "degC" GTW
 SG_ VCSEATD_a381_ocsHumidityRaw m381 : 57|7@1+ (1,0) [0|100] "%" GTW
 SG_ VCSEATD_a382_ocsCushionRaw m382 : 16|16@1+ (1,0) [0|65535] "" GTW
 SG_ VCSEATD_a382_ocsSpareRaw m382 : 32|16@1+ (1,0) [0|65535] "" GTW
 SG_ VCSEATD_a382_ocsTempRaw m382 : 48|9@1+ (0.5,-45) [-45|130] "degC" GTW
 SG_ VCSEATD_a382_ocsHumidityRaw m382 : 57|7@1+ (1,0) [0|100] "%" GTW
 SG_ VCSEATD_a386_ocsCushionRaw m386 : 16|16@1+ (1,0) [0|65535] "" GTW
 SG_ VCSEATD_a386_ocsSpareRaw m386 : 32|16@1+ (1,0) [0|65535] "" GTW
 SG_ VCSEATD_a386_ocsTempRaw m386 : 48|9@1+ (0.5,-45) [-45|130] "degC" GTW
 SG_ VCSEATD_a386_ocsHumidityRaw m386 : 57|7@1+ (1,0) [0|100] "%" GTW
 SG_ VCSEATD_a387_ocsCushionRaw m387 : 16|16@1+ (1,0) [0|65535] "" GTW
 SG_ VCSEATD_a387_ocsSpareRaw m387 : 32|16@1+ (1,0) [0|65535] "" GTW
 SG_ VCSEATD_a387_ocsTempRaw m387 : 48|9@1+ (0.5,-45) [-45|130] "degC" GTW
 SG_ VCSEATD_a387_ocsHumidityRaw m387 : 57|7@1+ (1,0) [0|100] "%" GTW
 SG_ VCSEATD_a388_ocsCushionRaw m388 : 16|16@1+ (1,0) [0|65535] "" GTW
 SG_ VCSEATD_a388_ocsSpareRaw m388 : 32|16@1+ (1,0) [0|65535] "" GTW
 SG_ VCSEATD_a388_ocsTempRaw m388 : 48|9@1+ (0.5,-45) [-45|130] "degC" GTW
 SG_ VCSEATD_a388_ocsHumidityRaw m388 : 57|7@1+ (1,0) [0|100] "%" GTW
 SG_ VCSEATD_a389_ocsTempRaw m389 : 16|16@1+ (0.002670328832,-45) [-45|130] "degC" GTW
 SG_ VCSEATD_a389_ocsHumidityRaw m389 : 32|16@1+ (0.00152590219,0) [0|100] "%" GTW
 SG_ VCSEATD_a394_ocsCushionCalib m394 : 16|16@1+ (1,0) [0|65535] "" GTW
 SG_ VCSEATD_a396_ocsSpareCalib m396 : 16|16@1+ (1,0) [0|65535] "" GTW
 SG_ VCSEATD_a397_ocsTempCalib m397 : 16|16@1+ (0.002670328832,-45) [-45|130] "degC" GTW
 SG_ VCSEATD_a397_ocsHumidityCalib m397 : 32|16@1+ (0.00152590219,0) [0|100] "%" GTW
 SG_ VCSEATD_a400_ocsCushionRaw m400 : 16|16@1+ (1,0) [0|65535] "" GTW
 SG_ VCSEATD_a401_ocsCushionRaw m401 : 16|13@1+ (1,23000) [23000|28000] "-" GTW
 SG_ VCSEATD_a401_ocsSpareRaw m401 : 32|13@1+ (1,23000) [23000|28000] "-" GTW
 SG_ VCSEATD_a401_ocsTempRaw m401 : 48|8@1+ (0.5,-40) [-40|85] "degC" GTW
 SG_ VCSEATD_a401_ocsHumidityRaw m401 : 56|6@1+ (2,0) [0|95] "%" GTW
 SG_ VCSEATD_a401_occupancySwitch m401 : 62|2@1+ (1,0) [0|3] "" GTW
 SG_ VCSEATD_a402_tosRelative m402 : 16|16@1- (1,0) [-32768|32767] "" GTW
 SG_ VCSEATD_a402_tosDeltaOffset m402 : 32|12@1- (1,0) [-2048|2047] "" GTW
 SG_ VCSEATD_a403_tosDeltaEmpty m403 : 16|16@1- (1,0) [-32768|32767] "" GTW
 SG_ VCSEATD_a403_tosDeltaOffset m403 : 32|12@1- (1,0) [-2048|2047] "" GTW
 SG_ VCSEATD_a404_tosDeltaCM m404 : 16|14@1- (1,0) [-8192|8191] "" GTW
 SG_ VCSEATD_a405_tosDeltaCM m405 : 16|14@1- (1,0) [-8192|8191] "" GTW
 SG_ VCSEATD_a406_tosDeltaCalibEmpty m406 : 16|16@1- (1,0) [-32768|32767] "" GTW
 SG_ VCSEATD_a406_tosDeltaCalibCM m406 : 32|16@1- (1,0) [-32768|32767] "" GTW
 SG_ VCSEATD_a408_tosDeltaEmpty m408 : 16|16@1- (1,0) [-32768|32767] "" GTW
 SG_ VCSEATD_a408_tosDeltaOffset m408 : 32|12@1- (1,0) [-2048|2047] "" GTW
 SG_ VCSEATD_a409_tosDeltaCM m409 : 16|16@1- (1,0) [-32768|32767] "" GTW
 SG_ VCSEATD_a410_tosDeltaEmpty m410 : 16|16@1- (1,0) [-32768|32767] "" GTW
 SG_ VCSEATD_a410_tosDeltaOffset m410 : 32|12@1- (1,0) [-2048|2047] "" GTW
 SG_ VCSEATD_a412_tosDeltaEmpty m412 : 16|16@1- (1,0) [-32768|32767] "" GTW
 SG_ VCSEATD_a412_tosDeltaOffset m412 : 32|12@1- (1,0) [-2048|2047] "" GTW
 SG_ VCSEATD_a413_sbrVoltage m413 : 16|10@1+ (0.01,0) [0|10.23] "V" GTW
 SG_ VCSEATD_a415_occupancyTimeMins m415 : 16|16@1+ (1,0) [0|65535] "" GTW
 SG_ VCSEATD_a444_channel m444 : 16|8@1+ (1,0) [0|255] "" GTW
 SG_ VCSEATD_a444_watchdog m444 : 24|1@1+ (1,0) [0|1] "" GTW
 SG_ VCSEATD_a444_gateDriver m444 : 25|1@1+ (1,0) [0|1] "" GTW
 SG_ VCSEATD_a444_overcurrent m444 : 26|1@1+ (1,0) [0|1] "" GTW
 SG_ VCSEATD_a444_supplyUndervoltage m444 : 27|1@1+ (1,0) [0|1] "" GTW
 SG_ VCSEATD_a444_cpUndervoltage m444 : 28|1@1+ (1,0) [0|1] "" GTW
 SG_ VCSEATD_a444_overTempShutdown m444 : 29|1@1+ (1,0) [0|1] "" GTW
 SG_ VCSEATD_a444_overTempWarning m444 : 30|1@1+ (1,0) [0|1] "" GTW
 SG_ VCSEATD_a444_highSide2GateDriver m444 : 31|1@1+ (1,0) [0|1] "" GTW
 SG_ VCSEATD_a444_lowSide2GateDriver m444 : 32|1@1+ (1,0) [0|1] "" GTW
 SG_ VCSEATD_a444_highSide1GateDriver m444 : 33|1@1+ (1,0) [0|1] "" GTW
 SG_ VCSEATD_a444_lowSide1GateDriver m444 : 34|1@1+ (1,0) [0|1] "" GTW
 SG_ VCSEATD_a444_highSide2OverCurent m444 : 35|1@1+ (1,0) [0|1] "" GTW
 SG_ VCSEATD_a444_lowSide2OverCurent m444 : 36|1@1+ (1,0) [0|1] "" GTW
 SG_ VCSEATD_a444_highSide1OverCurent m444 : 37|1@1+ (1,0) [0|1] "" GTW
 SG_ VCSEATD_a444_lowSide1OverCurent m444 : 38|1@1+ (1,0) [0|1] "" GTW
 SG_ VCSEATD_a444_spiInit m444 : 39|1@1+ (1,0) [0|1] "" GTW
 SG_ VCSEATD_a444_spiPeriodicCheck m444 : 40|1@1+ (1,0) [0|1] "" GTW
 SG_ VCSEATD_a444_spiFault m444 : 41|1@1+ (1,0) [0|1] "" GTW
 SG_ VCSEATD_a444_voltageMonitor m444 : 42|1@1+ (1,0) [0|1] "" GTW
 SG_ VCSEATD_a444_enableLow m444 : 43|1@1+ (1,0) [0|1] "" GTW
 SG_ VCSEATD_a445_checksFailedCount m445 : 16|2@1+ (1,0) [0|3] "" GTW
 SG_ VCSEATD_a445_SPIFaultCount m445 : 18|2@1+ (1,0) [0|3] "" GTW
 SG_ VCSEATD_a445_expectedMSB m445 : 24|8@1+ (1,0) [0|255] "" GTW
 SG_ VCSEATD_a445_expectedLSB m445 : 32|8@1+ (1,0) [0|255] "" GTW
 SG_ VCSEATD_a445_actualMSB m445 : 40|8@1+ (1,0) [0|255] "" GTW
 SG_ VCSEATD_a445_actualLSB m445 : 48|8@1+ (1,0) [0|255] "" GTW

BO_ 892 VCSEATD_alertMatrix: 8 VCSEATD
 SG_ VCSEATD_matrixIndex M : 0|4@1+ (1,0) [0|15] "" GTW
 SG_ VCSEATD_a001_WatchdogReset m0 : 4|1@1+ (1,0) [0|1] "" GTW
 SG_ VCSEATD_a002_PowerLossReset m0 : 5|1@1+ (1,0) [0|1] "" GTW
 SG_ VCSEATD_a003_SWAssertion m0 : 6|1@1+ (1,0) [0|1] "" GTW
 SG_ VCSEATD_a005_CANTXError m0 : 8|1@1+ (1,0) [0|1] "" GTW
 SG_ VCSEATD_a010_ExtSupplyVoltError m0 : 13|1@1+ (1,0) [0|1] "" GTW
 SG_ VCSEATD_a012_CPUReset m0 : 15|1@1+ (1,0) [0|1] "" GTW
 SG_ VCSEATD_a013_AlertManagerFault m0 : 16|1@1+ (1,0) [0|1] "" GTW
 SG_ VCSEATD_a015_NVMMAlert m0 : 18|1@1+ (1,0) [0|1] "" GTW
 SG_ VCSEATD_a021_TaskSchedulerError m0 : 24|1@1+ (1,0) [0|1] "" GTW
 SG_ VCSEATD_a022_TaskInitError m0 : 25|1@1+ (1,0) [0|1] "" GTW
 SG_ VCSEATD_a030_ECULogUploadRequest m0 : 33|1@1+ (1,0) [0|1] "" GTW
 SG_ VCSEATD_a031_UDSActive m0 : 34|1@1+ (1,0) [0|1] "" GTW
 SG_ VCSEATD_a041_HighCPULoad m0 : 44|1@1+ (1,0) [0|1] "" GTW
 SG_ VCSEATD_a042_HighStackUsage m0 : 45|1@1+ (1,0) [0|1] "" GTW
 SG_ VCSEATD_a043_Task1msError m0 : 46|1@1+ (1,0) [0|1] "" GTW
 SG_ VCSEATD_a044_Task10msError m0 : 47|1@1+ (1,0) [0|1] "" GTW
 SG_ VCSEATD_a045_Task100msError m0 : 48|1@1+ (1,0) [0|1] "" GTW
 SG_ VCSEATD_a046_Task1000msError m0 : 49|1@1+ (1,0) [0|1] "" GTW
 SG_ VCSEATD_a058_inputRHighSyncDebug m0 : 61|1@1+ (1,0) [0|1] "" GTW
 SG_ VCSEATD_a059_inputResistanceHigh m0 : 62|1@1+ (1,0) [0|1] "" GTW
 SG_ VCSEATD_a060_engineeringBuild m0 : 63|1@1+ (1,0) [0|1] "" GTW
 SG_ VCSEATD_a061_XCPConnected m1 : 4|1@1+ (1,0) [0|1] "" GTW
 SG_ VCSEATD_a062_XCPWasConnected m1 : 5|1@1+ (1,0) [0|1] "" GTW
 SG_ VCSEATD_a063_SwitchFault m1 : 6|1@1+ (1,0) [0|1] "" GTW
 SG_ VCSEATD_a064_busSleepReqTimeout m1 : 7|1@1+ (1,0) [0|1] "" GTW
 SG_ VCSEATD_a200_motorPhantomEncoder m3 : 23|1@1+ (1,0) [0|1] "" GTW
 SG_ VCSEATD_a201_motorDutyEncDisabl m3 : 24|1@1+ (1,0) [0|1] "" GTW
 SG_ VCSEATD_a218_motorDriverFault m3 : 41|1@1+ (1,0) [0|1] "" GTW
 SG_ VCSEATD_a219_motorCurrentDropout m3 : 42|1@1+ (1,0) [0|1] "" GTW
 SG_ VCSEATD_a220_seatCurrStallTrack m3 : 43|1@1+ (1,0) [0|1] "" GTW
 SG_ VCSEATD_a221_seatCurrStallBack m3 : 44|1@1+ (1,0) [0|1] "" GTW
 SG_ VCSEATD_a222_seatCurrStallTilt m3 : 45|1@1+ (1,0) [0|1] "" GTW
 SG_ VCSEATD_a223_seatCurrStallLift m3 : 46|1@1+ (1,0) [0|1] "" GTW
 SG_ VCSEATD_a224_seatEncStallTrack m3 : 47|1@1+ (1,0) [0|1] "" GTW
 SG_ VCSEATD_a225_seatEncStallBack m3 : 48|1@1+ (1,0) [0|1] "" GTW
 SG_ VCSEATD_a226_seatEncStallTilt m3 : 49|1@1+ (1,0) [0|1] "" GTW
 SG_ VCSEATD_a227_seatEncStallLift m3 : 50|1@1+ (1,0) [0|1] "" GTW
 SG_ VCSEATD_a228_seatEncOverTrack m3 : 51|1@1+ (1,0) [0|1] "" GTW
 SG_ VCSEATD_a229_seatEncOverBack m3 : 52|1@1+ (1,0) [0|1] "" GTW
 SG_ VCSEATD_a230_seatEncOverTilt m3 : 53|1@1+ (1,0) [0|1] "" GTW
 SG_ VCSEATD_a231_seatEncOverLift m3 : 54|1@1+ (1,0) [0|1] "" GTW
 SG_ VCSEATD_a232_seatCurrUnderTrack m3 : 55|1@1+ (1,0) [0|1] "" GTW
 SG_ VCSEATD_a233_seatCurrUnderBack m3 : 56|1@1+ (1,0) [0|1] "" GTW
 SG_ VCSEATD_a234_seatCurrUnderTilt m3 : 57|1@1+ (1,0) [0|1] "" GTW
 SG_ VCSEATD_a235_seatCurrUnderLift m3 : 58|1@1+ (1,0) [0|1] "" GTW
 SG_ VCSEATD_a236_lumbarOverPresA m3 : 59|1@1+ (1,0) [0|1] "" GTW
 SG_ VCSEATD_a237_lumbarOverPresB m3 : 60|1@1+ (1,0) [0|1] "" GTW
 SG_ VCSEATD_a238_lumbarValveMIA m3 : 61|1@1+ (1,0) [0|1] "" GTW
 SG_ VCSEATD_a239_seatHeatIFront m3 : 62|1@1+ (1,0) [0|1] "" GTW
 SG_ VCSEATD_a240_seatHeatShortFront m3 : 63|1@1+ (1,0) [0|1] "" GTW
 SG_ VCSEATD_a241_seatHeatMIAFront m4 : 4|1@1+ (1,0) [0|1] "" GTW
 SG_ VCSEATD_a242_seatHeatTmpFront m4 : 5|1@1+ (1,0) [0|1] "" GTW
 SG_ VCSEATD_a251_seatUncalTrack m4 : 14|1@1+ (1,0) [0|1] "" GTW
 SG_ VCSEATD_a252_seatUncalBack m4 : 15|1@1+ (1,0) [0|1] "" GTW
 SG_ VCSEATD_a253_seatUncalTilt m4 : 16|1@1+ (1,0) [0|1] "" GTW
 SG_ VCSEATD_a254_seatUncalLift m4 : 17|1@1+ (1,0) [0|1] "" GTW
 SG_ VCSEATD_a263_seatTrackStallDebug m4 : 26|1@1+ (1,0) [0|1] "" GTW
 SG_ VCSEATD_a264_seatBackStallDebug m4 : 27|1@1+ (1,0) [0|1] "" GTW
 SG_ VCSEATD_a265_seatTiltStallDebug m4 : 28|1@1+ (1,0) [0|1] "" GTW
 SG_ VCSEATD_a266_seatLiftStallDebug m4 : 29|1@1+ (1,0) [0|1] "" GTW
 SG_ VCSEATD_a267_seatTrackHCEncStl m4 : 30|1@1+ (1,0) [0|1] "" GTW
 SG_ VCSEATD_a268_seatBackHCEncStlDbg m4 : 31|1@1+ (1,0) [0|1] "" GTW
 SG_ VCSEATD_a269_seatTiltHCEncStlDbg m4 : 32|1@1+ (1,0) [0|1] "" GTW
 SG_ VCSEATD_a270_seatLiftHCEncStlDbg m4 : 33|1@1+ (1,0) [0|1] "" GTW
 SG_ VCSEATD_a290_occupancyFaultFront m4 : 53|1@1+ (1,0) [0|1] "" GTW
 SG_ VCSEATD_a291_buckleFaultedFront m4 : 54|1@1+ (1,0) [0|1] "" GTW
 SG_ VCSEATD_a380_ocsCushionHigh m6 : 23|1@1+ (1,0) [0|1] "" GTW
 SG_ VCSEATD_a381_ocsCushionLow m6 : 24|1@1+ (1,0) [0|1] "" GTW
 SG_ VCSEATD_a382_ocsCushionShort m6 : 25|1@1+ (1,0) [0|1] "" GTW
 SG_ VCSEATD_a386_ocsSpareHigh m6 : 29|1@1+ (1,0) [0|1] "" GTW
 SG_ VCSEATD_a387_ocsSpareLow m6 : 30|1@1+ (1,0) [0|1] "" GTW
 SG_ VCSEATD_a388_ocsSpareShort m6 : 31|1@1+ (1,0) [0|1] "" GTW
 SG_ VCSEATD_a389_ocsTHInvalid m6 : 32|1@1+ (1,0) [0|1] "" GTW
 SG_ VCSEATD_a390_ocsCushionNoCalib m6 : 33|1@1+ (1,0) [0|1] "" GTW
 SG_ VCSEATD_a392_ocsSpareNoCalib m6 : 35|1@1+ (1,0) [0|1] "" GTW
 SG_ VCSEATD_a393_ocsTHNoCalib m6 : 36|1@1+ (1,0) [0|1] "" GTW
 SG_ VCSEATD_a394_ocsCushionInvlCalib m6 : 37|1@1+ (1,0) [0|1] "" GTW
 SG_ VCSEATD_a396_ocsSpareInvalCalib m6 : 39|1@1+ (1,0) [0|1] "" GTW
 SG_ VCSEATD_a397_ocsTHInvalCalib m6 : 40|1@1+ (1,0) [0|1] "" GTW
 SG_ VCSEATD_a398_ocsTOSMIA m6 : 41|1@1+ (1,0) [0|1] "" GTW
 SG_ VCSEATD_a399_ocsTHMIA m6 : 42|1@1+ (1,0) [0|1] "" GTW
 SG_ VCSEATD_a400_ocsCushionMismatch m6 : 43|1@1+ (1,0) [0|1] "" GTW
 SG_ VCSEATD_a401_ocsDiagContext m6 : 44|1@1+ (1,0) [0|1] "" GTW
 SG_ VCSEATD_a402_ocsSensorLow m6 : 45|1@1+ (1,0) [0|1] "" GTW
 SG_ VCSEATD_a403_ocsSensorHigh m6 : 46|1@1+ (1,0) [0|1] "" GTW
 SG_ VCSEATD_a404_ocsBackDisconnect m6 : 47|1@1+ (1,0) [0|1] "" GTW
 SG_ VCSEATD_a405_ocsSensorDisconnect m6 : 48|1@1+ (1,0) [0|1] "" GTW
 SG_ VCSEATD_a406_ocsCalibMismatch m6 : 49|1@1+ (1,0) [0|1] "" GTW
 SG_ VCSEATD_a407_ocsManufactureInvld m6 : 50|1@1+ (1,0) [0|1] "" GTW
 SG_ VCSEATD_a408_ocsSensorDroop m6 : 51|1@1+ (1,0) [0|1] "" GTW
 SG_ VCSEATD_a409_ocsHeatPadNoConnect m6 : 52|1@1+ (1,0) [0|1] "" GTW
 SG_ VCSEATD_a410_ocsSlowDrift m6 : 53|1@1+ (1,0) [0|1] "" GTW
 SG_ VCSEATD_a411_ocsDataTimeout m6 : 54|1@1+ (1,0) [0|1] "" GTW
 SG_ VCSEATD_a412_ocsRebaselineDBG m6 : 55|1@1+ (1,0) [0|1] "" GTW
 SG_ VCSEATD_a413_ocsSBRFaulted m6 : 56|1@1+ (1,0) [0|1] "" GTW
 SG_ VCSEATD_a414_ocsMissedIngressDBG m6 : 57|1@1+ (1,0) [0|1] "" GTW
 SG_ VCSEATD_a415_ocsRebaseEgressDBG m6 : 58|1@1+ (1,0) [0|1] "" GTW
 SG_ VCSEATD_a444_drv8703Fault m7 : 27|1@1+ (1,0) [0|1] "" GTW
 SG_ VCSEATD_a445_drv8703SpiFaultDBG m7 : 28|1@1+ (1,0) [0|1] "" GTW

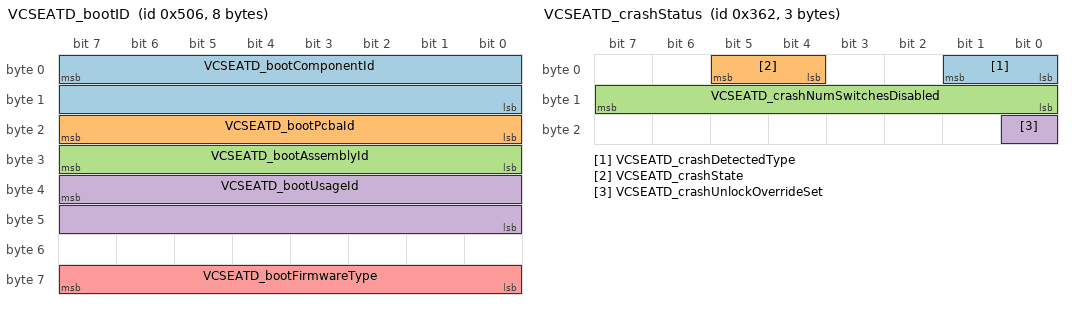
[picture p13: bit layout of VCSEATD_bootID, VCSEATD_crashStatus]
BO_ 1286 VCSEATD_bootID: 8 VCSEATD
 SG_ VCSEATD_bootComponentId : 7|16@0+ (1,0) [0|65535] "" Vector__XXX
 SG_ VCSEATD_bootPcbaId : 23|8@0+ (1,0) [0|255] "" Vector__XXX
 SG_ VCSEATD_bootAssemblyId : 31|8@0+ (1,0) [0|255] "" Vector__XXX
 SG_ VCSEATD_bootUsageId : 39|16@0+ (1,0) [0|65535] "" Vector__XXX
 SG_ VCSEATD_bootFirmwareType : 63|8@0+ (1,0) [0|255] "" Vector__XXX

BO_ 866 VCSEATD_crashStatus: 3 VCSEATD
 SG_ VCSEATD_crashDetectedType : 0|2@1+ (1,0) [0|3] "" GTW
 SG_ VCSEATD_crashState : 4|2@1+ (1,0) [0|3] "" GTW
 SG_ VCSEATD_crashNumSwitchesDisabled : 8|8@1+ (1,0) [0|255] "" GTW
 SG_ VCSEATD_crashUnlockOverrideSet : 16|1@1+ (1,0) [0|1] "" GTW

BO_ 770 VCSEATD_info: 8 VCSEATD
 SG_ VCSEATD_infoIndex M : 0|8@1+ (1,0) [0|255] "" GTW
 SG_ VCSEATD_infoBuildType m10 : 8|8@1+ (1,0) [0|4] "" GTW
 SG_ VCSEATD_infoBuildConfigId m10 : 16|16@1+ (1,0) [0|65535] "" GTW
 SG_ VCSEATD_infoHardwareId m10 : 32|16@1+ (1,0) [0|65535] "" Vector__XXX
 SG_ VCSEATD_infoComponentId m10 : 48|16@1+ (1,0) [0|65535] "" Vector__XXX
 SG_ VCSEATD_infoPcbaId m11 : 8|8@1+ (1,0) [0|255] "" Vector__XXX
 SG_ VCSEATD_infoAssemblyId m11 : 16|8@1+ (1,0) [0|255] "" Vector__XXX
 SG_ VCSEATD_infoUsageId m11 : 24|16@1+ (1,0) [0|65535] "" Vector__XXX
 SG_ VCSEATD_infoSubUsageId m11 : 40|16@1+ (1,0) [0|65535] "" Vector__XXX
 SG_ VCSEATD_infoAppCrc m13 : 32|32@1+ (1,0) [0|4294967295] "" GTW
 SG_ VCSEATD_infoSubcomponent1 m16 : 32|32@1+ (1,0) [0|4294967295] "" Vector__XXX
 SG_ VCSEATD_infoAppGitHash m17 : 8|56@1+ (1,0) [0|7.20575940379279E+16] "" Vector__XXX
 SG_ VCSEATD_infoBootGitHash m18 : 8|56@1+ (1,0) [0|7.20575940379279E+16] "" Vector__XXX
 SG_ VCSEATD_infoPlatformType m19 : 8|8@1+ (1,0) [0|255] "" GTW
 SG_ VCSEATD_infoBootUdsProtoVersion m20 : 8|16@1+ (1,0) [0|65535] "" Vector__XXX
 SG_ VCSEATD_infoBootCrc m20 : 24|32@1+ (1,0) [0|4294967295] "" Vector__XXX
 SG_ VCSEATD_infoSubcomponent2 m23 : 32|32@1+ (1,0) [0|4294967295] "" Vector__XXX
 SG_ VCSEATD_infoSubcomponent3 m24 : 32|32@1+ (1,0) [0|4294967295] "" Vector__XXX
 SG_ VCSEATD_infoSubcomponent4 m31 : 32|32@1+ (1,0) [0|4294967295] "" Vector__XXX
 SG_ VCSEATD_infoSubcomponent5 m32 : 32|32@1+ (1,0) [0|4294967295] "" Vector__XXX
 SG_ VCSEATD_infoSubcomponent6 m33 : 32|32@1+ (1,0) [0|4294967295] "" Vector__XXX

BO_ 1841 VCSEATD_ocsSensorStatus: 8 VCSEATD
 SG_ VCSEATD_ocsSensorStatusIndex M : 0|4@1+ (1,0) [0|6] "" Vector__XXX
 SG_ VCSEATD_tosRawCushion m0 : 8|16@1+ (1,0) [0|65535] "" GTW
 SG_ VCSEATD_tosRawSeatback m0 : 24|16@1+ (1,0) [0|65535] "" Vector__XXX
 SG_ VCSEATD_tosRawSpare m0 : 40|16@1+ (1,0) [0|65535] "" GTW
 SG_ VCSEATD_tosCountCushion m0 : 56|4@1+ (1,0) [0|15] "" Vector__XXX
 SG_ VCSEATD_tosCountSpare m0 : 60|4@1+ (1,0) [0|15] "" Vector__XXX
 SG_ VCSEATD_ocsTemperature m1 : 8|16@1+ (0.002670328832,-45) [-45|130] "degC" GTW
 SG_ VCSEATD_ocsHumidity m1 : 24|16@1+ (0.00152590219,0) [0|100] "%" GTW
 SG_ VCSEATD_tosFilteredCushion m2 : 4|16@1+ (1,0) [0|65535] "" GTW
 SG_ VCSEATD_tosFilteredSpare m2 : 20|16@1+ (1,0) [0|65535] "" GTW
 SG_ VCSEATD_tosDeltaDisconnected m2 : 50|14@1- (1,0) [-8192|8191] "" GTW
 SG_ VCSEATD_tosDeltaOffset m3 : 4|14@1- (1,0) [-8192|8191] "" GTW
 SG_ VCSEATD_tosDeltaEmpty m3 : 18|14@1- (1,0) [-8192|8191] "" GTW
 SG_ VCSEATD_tosRelative m3 : 32|14@1- (1,0) [-8192|8191] "" GTW
 SG_ VCSEATD_tosDeltaStable m3 : 46|1@1+ (1,0) [0|1] "" Vector__XXX
 SG_ VCSEATD_classificationLocked m3 : 47|1@1+ (1,0) [0|1] "" GTW
 SG_ VCSEATD_classificationRaw m3 : 48|3@1+ (1,0) [0|7] "" GTW
 SG_ VCSEATD_sandwichRawA1 m4 : 4|12@1- (1,0) [-2048|2047] "" Vector__XXX
 SG_ VCSEATD_sandwichRawA2_F m4 : 16|12@1- (1,0) [-2048|2047] "" Vector__XXX
 SG_ VCSEATD_sandwichRawA2_B m4 : 28|12@1- (1,0) [-2048|2047] "" Vector__XXX
 SG_ VCSEATD_sandwichRawB1 m4 : 40|12@1- (1,0) [-2048|2047] "" Vector__XXX
 SG_ VCSEATD_sandwichRawB2_F m4 : 52|12@1- (1,0) [-2048|2047] "" Vector__XXX
 SG_ VCSEATD_sandwichRawB2_B m5 : 4|12@1- (1,0) [-2048|2047] "" Vector__XXX
 SG_ VCSEATD_sandwichRawC2_F m5 : 16|12@1- (1,0) [-2048|2047] "" Vector__XXX
 SG_ VCSEATD_sandwichRawC2_B m5 : 28|12@1- (1,0) [-2048|2047] "" Vector__XXX

BO_ 1843 VCSEATD_ocsSensorStatus2: 8 VCSEATD
 SG_ VCSEATD_ocsSensorStatus2Index M : 0|4@1+ (1,0) [0|3] "" Vector__XXX
 SG_ VCSEATD_ocsCalibCushionEmpty m0 : 4|16@1+ (1,0) [0|65535] "" GTW
 SG_ VCSEATD_ocsCalibSpareEmpty m0 : 20|16@1+ (1,0) [0|65535] "" GTW
 SG_ VCSEATD_ocsCalibTempEmpty m0 : 36|16@1+ (0.002670328832,-45) [-45|130] "degC" GTW
 SG_ VCSEATD_ocsFieldCalibrated m0 : 52|1@1+ (1,0) [0|1] "" GTW
 SG_ VCSEATD_ocsCalibHumidityEmpty m1 : 4|16@1+ (0.00152590219,0) [0|100] "%" GTW
 SG_ VCSEATD_ocsCalibCushionDisc m1 : 20|16@1+ (1,0) [0|65535] "" GTW
 SG_ VCSEATD_ocsCalibSpareDisc m1 : 36|16@1+ (1,0) [0|65535] "" GTW
 SG_ VCSEATD_ocsCalibTempDisc m2 : 4|16@1+ (0.002670328832,-45) [-45|130] "degC" GTW
 SG_ VCSEATD_ocsCalibHumidityDisc m2 : 20|16@1+ (0.00152590219,0) [0|100] "%" GTW

BO_TX_BU_ 1609 : GTW,GTWU,TOOL;
BO_TX_BU_ 1840 : GTW,GTWU,TOOL;
BO_TX_BU_ 1604 : GTW,GTWU,TOOL;
BO_TX_BU_ 1607 : GTW,GTWU,TOOL;
BO_TX_BU_ 1605 : GTW,GTWU,TOOL;
BO_TX_BU_ 2015 : GTW,GTWU,TOOL;
BO_TX_BU_ 1613 : GTW,GTWU,TOOL;
BO_TX_BU_ 1612 : GTW,GTWU,TOOL;
BO_TX_BU_ 1603 : GTW,GTWU,TOOL;
BO_TX_BU_ 1614 : GTW,GTWU,TOOL;
BO_TX_BU_ 2033 : GTW,GTWU,TOOL;
BO_TX_BU_ 1601 : GTW,GTWU,TOOL;
BO_TX_BU_ 1936 : GTW,GTWU,TOOL;
BO_TX_BU_ 1615 : GTW,GTWU,TOOL;
CM_ BO_ 1627 "TAS UDS message.";
CM_ BO_ 843 "TAS alert matrix 1";
CM_ BO_ 859 "TAS alert matrix 2";
CM_ BO_ 875 "TAS alert matrix 3";
CM_ BO_ 891 "TAS alert matrix 4";
CM_ BO_ 907 "TAS alert matrix 5";
CM_ BO_ 1851 "XCP protocol response message";
CM_ BO_ 895 "Continental TPMS Debug Message, Only used during development";
CM_ BO_ 1936 "APPL_SG_SCCM2";
CM_ BO_ 578 "Power State of systems controlled by VCSEATD";
CM_ BO_ 892 "VCSEATD alert matrix";
CM_ SG_ 1546 TAS_logComponentPressureFL "to do";
CM_ SG_ 1546 TAS_logComponentPressureFR "to do";
CM_ SG_ 1546 TAS_logComponentPressureRL "to do";
CM_ SG_ 1546 TAS_logComponentPressureRR "to do";
CM_ SG_ 539 TAS_levelingState "to do";
CM_ SG_ 539 TAS_levelingItem "to do";
CM_ SG_ 539 TAS_pressureGallery "to do";
CM_ SG_ 539 TAS_pressureReservoir "to do";
CM_ SG_ 539 TAS_runMode "to do";
CM_ SG_ 539 TAS_filterMode "to do";
CM_ SG_ 539 TAS_limpHomeMode "to do";
CM_ SG_ 539 TAS_targetLevel "to do";
CM_ SG_ 539 TAS_currentLevel "to do";
CM_ SG_ 539 TAS_jackMode "to do";
CM_ SG_ 539 TAS_reduceVehicleSpeedRequest "to do";
CM_ SG_ 525 TAS_adaptiveRideModeOverride "to do";
CM_ SG_ 843 TAS_a001_WatchdogReset "Warns if the processor has experienced a reset due to watchdog reset.";
CM_ SG_ 843 TAS_a002_PowerLossReset "Warns if the processor has experienced a reset due to power loss.";
CM_ SG_ 843 TAS_a003_SWAssertion "An internal software assertion has failed.";
CM_ SG_ 843 TAS_a012_CPUReset "CPU detected a reset.";
CM_ SG_ 843 TAS_a015_NVMMAlert "An issue is indicated from the NVRAM Manager.";
CM_ SG_ 843 TAS_a021_TaskSchedulerError "If a task was not able to run at the appropriate time.";
CM_ SG_ 843 TAS_a022_TaskInitError "If a task failed to initialize.";
CM_ SG_ 843 TAS_a025_CrashEvent "Air suspension functionality is disabled due to vehicle crash reported by restraint module.";
CM_ SG_ 843 TAS_a030_PWMerrorFL "Abnormal PWM signal received from front left PWM height sensor.";
CM_ SG_ 843 TAS_a031_PWMerrorFR "Abnormal PWM signal received from front right PWM height sensor.";
CM_ SG_ 843 TAS_a032_PWMerrorRL "Abnormal PWM signal received from rear left PWM height sensor.";
CM_ SG_ 843 TAS_a033_PWMerrorRR "Abnormal PWM signal received from rear right PWM height sensor.";
CM_ SG_ 843 TAS_a034_PWMshortFL "Signal line from front left PWM height sensor shorted to ground.";
CM_ SG_ 843 TAS_a035_PWMshortFR "Signal line from front right PWM height sensor shorted to ground.";
CM_ SG_ 843 TAS_a036_PWMshortRL "Signal line from rear left PWM height sensor shorted to ground.";
CM_ SG_ 843 TAS_a037_PWMshortRR "Signal line from rear right PWM height sensor shorted to ground.";
CM_ SG_ 843 TAS_a038_PWMopenFL "Front left height sensor disconnected, or signal line from front left PWM height sensor floating.";
CM_ SG_ 843 TAS_a039_PWMopenFR "Front right height sensor disconnected, or signal line from front right PWM height sensor floating.";
CM_ SG_ 843 TAS_a040_PWMopenRL "Rear left height sensor disconnected, or signal line from rear left PWM height sensor floating.";
CM_ SG_ 843 TAS_a041_PWMopenRR "Rear right height sensor disconnected, or signal line from rear right PWM height sensor floating.";
CM_ SG_ 843 TAS_a043_Task1msError "Debug information for 1ms task errors. Set along with TaskSchedulerError.";
CM_ SG_ 843 TAS_a044_Task10msError "Debug information for 10ms task errors. Set along with TaskSchedulerError.";
CM_ SG_ 843 TAS_a045_Task100msError "Debug information for 100ms task errors. Set along with TaskSchedulerError.";
CM_ SG_ 843 TAS_a046_Task1000msError "Debug information for 1000ms task errors. Set along with TaskSchedulerError.";
CM_ SG_ 843 TAS_a061_XCPConnected "Indicates an active connection to the XCP state machine";
CM_ SG_ 843 TAS_a062_XCPWasConnected "Indicates there was an active connection to the XCP state machine";
CM_ SG_ 859 TAS_a070_underVoltage12V "Supply voltage to ECU is below 8.5V";
CM_ SG_ 859 TAS_a071_overVoltage12V "Supply voltage to ECU is above 16.5V";
CM_ SG_ 859 TAS_a072_shortCircuit5VOnBoard "On board 5V switched supply is measured to be approximately 0V.";
CM_ SG_ 859 TAS_a073_underVoltage5VOnBoard "On board 5V switched supply is measured to be below 4.5V.";
CM_ SG_ 859 TAS_a074_shortCircuit5VOffBoard "Off board 5V switched supply is measured to be approximately 0V.";
CM_ SG_ 859 TAS_a075_underVoltage5VOffBoard "Off board 5V switched supply is measured to be under 4.5V.";
CM_ SG_ 859 TAS_a076_overVoltage5VOffBoard "Off board 5V switched supply is measured to be over 5.5V.";
CM_ SG_ 859 TAS_a077_pressureSigVTooLow "Pressure sensor signal voltage too low; likely disconnected.";
CM_ SG_ 859 TAS_a078_pressureSigVTooHigh "Pressure sensor signal voltage too high.";
CM_ SG_ 859 TAS_a093_OTPError "The one time programmable memory driver has encountered an error.";
CM_ SG_ 859 TAS_a098_MCU_MIA "One or more CAN messages from MCU are not being received by the ECU.";
CM_ SG_ 859 TAS_a099_EFUSE_MIA "One or more CAN messages from EFUSE are not being received by the ECU.";
CM_ SG_ 859 TAS_a100_SCCM_MIA "One or more CAN messages from EFUSE are not being received by the ECU.";
CM_ SG_ 859 TAS_a101_ESP_MIA "One or more CAN messages from ESP are not being received by the ECU.";
CM_ SG_ 859 TAS_a102_DI_MIA "One or more CAN messages from DI are not being received by the ECU.";
CM_ SG_ 859 TAS_a103_GTW_MIA "One or more CAN messages from GTW are not being received by the ECU.";
CM_ SG_ 859 TAS_a105_ECUDebugMode "SBC has debug jumper set.";
CM_ SG_ 859 TAS_a106_HighCPULoad "to do";
CM_ SG_ 859 TAS_a107_HighStackUsage "to do";
CM_ SG_ 859 TAS_a121_maxDutyFL "Front left air valve has reached its duty cycle (on time) limit.";
CM_ SG_ 859 TAS_a122_maxDutyFR "Front right air valve has reached its duty cycle (on time) limit.";
CM_ SG_ 859 TAS_a123_maxDutyRL "Rear left air valve has reached its duty cycle (on time) limit.";
CM_ SG_ 859 TAS_a124_maxDutyRR "Rear right air valve has reached its duty cycle (on time) limit.";
CM_ SG_ 859 TAS_a125_maxDutyReservoir "Reservoir air valve has reached its duty cycle (on time) limit.";
CM_ SG_ 859 TAS_a126_maxDutyExhaust "Exhaust air valve has reached its duty cycle (on time) limit.";
CM_ SG_ 859 TAS_a127_maxDutyBoost "Boost air valve has reached its duty cycle (on time) limit.";
CM_ SG_ 859 TAS_a128_maxDutyCompressor "Air compressor has reached its duty cycle (on time) limit.";
CM_ SG_ 875 TAS_a129_openCircuitFL "Front left air valve detected open circuit.";
CM_ SG_ 875 TAS_a130_openCircuitFR "Front right air valve detected open circuit.";
CM_ SG_ 875 TAS_a131_openCircuitRL "Rear left air valve detected open circuit.";
CM_ SG_ 875 TAS_a132_openCircuitRR "Rear right air valve detected open circuit.";
CM_ SG_ 875 TAS_a133_openCircuitReservoir "Reservoir air valve detected open circuit.";
CM_ SG_ 875 TAS_a134_openCircuitExhaust "Exhaust air valve detected open circuit.";
CM_ SG_ 875 TAS_a135_openCircuitBoost "Boost air valve detected open circuit.";
CM_ SG_ 875 TAS_a136_openCircuitCompressor "Air compressor or air compressor relay detected open circuit.";
CM_ SG_ 875 TAS_a137_shortCircuitFL "Front left air valve detected short circuit.";
CM_ SG_ 875 TAS_a138_shortCircuitFR "Front right air valve detected short circuit.";
CM_ SG_ 875 TAS_a139_shortCircuitRL "Rear left air valve detected short circuit.";
CM_ SG_ 875 TAS_a140_shortCircuitRR "Rear right air valve detected short circuit.";
CM_ SG_ 875 TAS_a141_shortCircuitReservoir "Reservoir air valve detected short circuit.";
CM_ SG_ 875 TAS_a142_shortCircuitExhaust "Exhaust air valve detected short circuit.";
CM_ SG_ 875 TAS_a143_shortCircuitBoost "Boost air valve detected short circuit.";
CM_ SG_ 875 TAS_a144_shortCircuitCompressor "Air compressor or air compressor relay detected short circuit.";
CM_ SG_ 875 TAS_a145_boardFaultFL "Implausible condition detected on front left air valve circuit, possibly due to ECU hardware failure.";
CM_ SG_ 875 TAS_a146_boardFaultFR "Implausible condition detected on front right air valve circuit, possibly due to ECU hardware failure.";
CM_ SG_ 875 TAS_a147_boardFaultRL "Implausible condition detected on rear left air valve circuit, possibly due to ECU hardware failure.";
CM_ SG_ 875 TAS_a148_boardFaultRR "Implausible condition detected on rear right air valve circuit, possibly due to ECU hardware failure.";
CM_ SG_ 875 TAS_a149_boardFaultReservoir "Implausible condition detected on reservoir air valve circuit, possibly due to ECU hardware failure.";
CM_ SG_ 875 TAS_a150_boardFaultExhaust "Implausible condition detected on exhaust air valve circuit, possibly due to ECU hardware failure.";
CM_ SG_ 875 TAS_a151_boardFaultBoost "Implausible condition detected on boost air valve circuit, possibly due to ECU hardware failure.";
CM_ SG_ 875 TAS_a152_boardFaultCompressor "Implausible condition detected on air compressor or air compressor relay circuit, possibly due to ECU hardware failure.";
CM_ SG_ 875 TAS_a153_otherCircuitFL "Implausible condition detected on front left air valve circuit.";
CM_ SG_ 875 TAS_a154_otherCircuitFR "Implausible condition detected on front right air valve circuit.";
CM_ SG_ 875 TAS_a155_otherCircuitRL "Implausible condition detected on rear left air valve circuit.";
CM_ SG_ 875 TAS_a156_otherCircuitRR "Implausible condition detected on rear right air valve circuit.";
CM_ SG_ 875 TAS_a157_otherCircuitReservoir "Implausible condition detected on reservoir air valve circuit.";
CM_ SG_ 875 TAS_a158_otherCircuitExhaust "Implausible condition detected on exhaust air valve circuit.";
CM_ SG_ 875 TAS_a159_otherCircuitBoost "Implausible condition detected on boost air valve circuit.";
CM_ SG_ 875 TAS_a160_otherCircuitCompressor "Implausible condition detected on air compressor or air compressor relay circuit.";
CM_ SG_ 875 TAS_a161_valveBlockOpenGND "Ground return wire from corner/reservoir valve block detected disconnected.";
CM_ SG_ 875 TAS_a162_compressorValveOpenGND "Ground return wire from exhaust/boost valve block detected disconnected.";
CM_ SG_ 875 TAS_a163_reservoirFillDisabled "useless!";
CM_ SG_ 875 TAS_a173_staticLeakDetectFL "Static vehicle spring leak check detected a spring leak on the front left air spring.";
CM_ SG_ 875 TAS_a174_staticLeakDetectFR "Static vehicle spring leak check detected a spring leak on the front right air spring.";
CM_ SG_ 875 TAS_a175_staticLeakDetectRL "Static vehicle spring leak check detected a spring leak on the rear left air spring.";
CM_ SG_ 875 TAS_a176_staticLeakDetectRR "Static vehicle spring leak check detected a spring leak on the rear right air spring.";
CM_ SG_ 891 TAS_a200_jackModeActive "Air suspension is in jack mode.";
CM_ SG_ 891 TAS_a201_lowHVBattery "Received a 12V low shed request.";
CM_ SG_ 891 TAS_a210_outOfRangeCalibration "Received ride height sensor calibration values are outside of allowable range.";
CM_ SG_ 891 TAS_a211_noRideHeightCalib "No valid ride height sensor calibrations have been saved to the ECU.";
CM_ SG_ 891 TAS_a213_yellowWarningLamp "ECU has requested suspension yellow warning lamp to be displayed.";
CM_ SG_ 891 TAS_a214_redWarningLamp "ECU has requested suspension red warning lamp to be displayed.";
CM_ SG_ 891 TAS_a215_limpHomeMode10 "Air suspension system is operating under limp home mode 10 restrictions.";
CM_ SG_ 891 TAS_a216_limpHomeMode20 "Air suspension system is operating under limp home mode 20 restrictions.";
CM_ SG_ 891 TAS_a217_limpHomeMode30 "Air suspension system is operating under limp home mode 30 restrictions.";
CM_ SG_ 891 TAS_a218_limpHomeMode40 "Air suspension system is operating under limp home mode 40 restrictions.";
CM_ SG_ 891 TAS_a220_exhaustGalleryFault "Fault occurred while attempting to exhaust the air gallery.";
CM_ SG_ 891 TAS_a221_valveLeakDetected "Internal air spring or air reservoir valve leak detected.";
CM_ SG_ 891 TAS_a222_compressorPrefillFault "Air compressor failed to build pressure when powered.";
CM_ SG_ 891 TAS_a223_blockedAirline "An airline to the air springs or air reservoir has been detected blocked/crushed.";
CM_ SG_ 891 TAS_a224_openAirline "An airline to the air springs or air reservoir has been detected disconnected/open.";
CM_ SG_ 891 TAS_a225_galleryPressureTooHigh "Gallery pressure too high.";
CM_ SG_ 891 TAS_a226_PWMfastDetectFL "Abnormal PWM signal received from front left PWM height sensor. More sensitive than other ride height sensor alerts.";
CM_ SG_ 891 TAS_a227_PWMfastDetectFR "Abnormal PWM signal received from front right PWM height sensor. More sensitive than other ride height sensor alerts.";
CM_ SG_ 891 TAS_a228_PWMfastDetectRL "Abnormal PWM signal received from rear left PWM height sensor. More sensitive than other ride height sensor alerts.";
CM_ SG_ 891 TAS_a229_PWMfastDetectRR "Abnormal PWM signal received from rear right PWM height sensor. More sensitive than other ride height sensor alerts.";
CM_ SG_ 891 TAS_a230_geofenceNotification "Signal to UI to show suspension geofence notification.";
CM_ SG_ 907 TAS_a286_driveCycleStats1 "Drive cycle statistics.";
CM_ SG_ 907 TAS_a287_driveCycleStats2 "Drive cycle statistics.";
CM_ SG_ 907 TAS_a288_driveCycleStats3 "Drive cycle statistics.";
CM_ SG_ 907 TAS_a289_driveCycleStats4 "Drive cycle statistics.";
CM_ SG_ 907 TAS_a290_twistSustainedAtSpeed "Ride height sensors are measured to be in twisted or implausible state.";
CM_ SG_ 907 TAS_a291_frontAxleTooHigh "Front axle has been measured to be higher than any reasonable height.";
CM_ SG_ 907 TAS_a292_rearAxleTooHigh "Rear axle has been measured to be higher than any reasonable height.";
CM_ SG_ 907 TAS_a293_frontAxleTooLow "Front axle has been measured to be lower than any reasonable height.";
CM_ SG_ 907 TAS_a294_rearAxleTooLow "Rear axle has been measured to be lower than any reasonable height.";
CM_ SG_ 907 TAS_a295_targetHeightNotMet "Air suspension failed to adjust to target ride height.";
CM_ SG_ 863 TPMS_noResponseTimeoutFL "Number of timeouts since TPMS last received signal from front left sensor.";
CM_ SG_ 863 TPMS_noResponseTimeoutFR "Number of timeouts since TPMS last received signal from front right sensor.";
CM_ SG_ 863 TPMS_noResponseTimeoutRL "Number of timeouts since TPMS last received signal from rear left sensor.";
CM_ SG_ 863 TPMS_noResponseTimeoutRR "Number of timeouts since TPMS last received signal from rear right sensor.";
CM_ SG_ 799 TPMS_pressureFL "Pressure reading from the front left tire pressure sensor.";
CM_ SG_ 799 TPMS_pressureFR "Pressure reading from the front right tire pressure sensor.";
CM_ SG_ 799 TPMS_pressureRL "Pressure reading from the rear left tire pressure sensor.";
CM_ SG_ 799 TPMS_pressureRR "Pressure reading from the rear right tire pressure sensor.";
CM_ SG_ 882 TPMS_sensorIDFL "Front Left tire pressure sensor ID";
CM_ SG_ 882 TPMS_sensorIDRR "Rear Right tire pressure sensor ID";
CM_ SG_ 882 TPMS_sensorIDFR "Front Right tire pressure sensor ID";
CM_ SG_ 882 TPMS_sensorIDRL "Rear Left tire pressure sensor ID";
CM_ SG_ 783 TPMS_systemFault "Indicates TPMS is faulted.";
CM_ SG_ 1936 UDS_sccmRequestData "External application to ECU";
CM_ SG_ 968 UI_countryCode "Country Code from NAV as defined in http://en.wikipedia.org/wiki/ISO_3166-1_numeric";
CM_ SG_ 641 UI_driverProfileRecallIndex "multiplexer";
CM_ SG_ 641 UI_driverProfileRecallStop "notifies controller to stop profile recall action";
CM_ SG_ 641 UI_frontSeatRecallActive "signals when driver seat presets are being recalled";
CM_ SG_ 641 UI_frontSeatTrackPos "Track position of front seat";
CM_ SG_ 641 UI_frontSeatBackPos "Back tilt position of front seat";
CM_ SG_ 641 UI_frontSeatLiftPos "Lift position of front seat";
CM_ SG_ 641 UI_frontSeatTiltPos "Tilt position of front seat";
CM_ SG_ 641 UI_columnAndLumbarRecallActive "signals when column/lumbar presets are being recalled";
CM_ SG_ 641 UI_lumbarAPressureHpa "communicates current pressure of lumbar A";
CM_ SG_ 1070 UI_autopilotPowerStateRequest "Request to change Autopilot Power state";
CM_ SG_ 660 UI_suspensionLevelRequest "UI customer level request for suspension height or jack mode toggle.";
CM_ SG_ 660 UI_adaptiveRideRequest "UI customer adaptive ride request for air suspension.";
CM_ SG_ 660 UI_suspensionLoweringRequest "UI customer request for suspension lowering setting";
CM_ SG_ 660 UI_geofenceLevelingRequest "Geofence level request from customer";
CM_ SG_ 660 UI_jackModeToggleRequest "Customer request to toggle suspension jack mdoe state.";
CM_ SG_ 660 UI_adaptiveTuningRequest0 "UI customer adaptive ride custom tuning request for air suspension.";
CM_ SG_ 660 UI_adaptiveTuningRequest1 "UI customer adaptive ride custom tuning request for air suspension.";
CM_ SG_ 660 UI_suspensionControlCounter "Counter";
CM_ SG_ 660 UI_suspensionControlChecksum "Checksum method for UI_suspensionControl: sum of all bytes in message + originating CAN ID (0x2 + 0x93 = 0x95).";
CM_ SG_ 1373 VCSEATD_alertID "Numeric ID that identifies the alert.";
CM_ SG_ 1373 VCSEATD_alertType "VCSEATD alert state (set or cleared)";
CM_ SG_ 1373 VCSEATD_a000_alertDataW0 "Generic word access to alert data W0.";
CM_ SG_ 1373 VCSEATD_a000_alertDataW1 "Generic word access to alert data W1.";
CM_ SG_ 1373 VCSEATD_a000_alertDataW2 "Generic word access to alert data W2.";
CM_ SG_ 1373 VCSEATD_a030_logId "Log Identifier";
CM_ SG_ 1373 VCSEATD_a242_snsShortCircuit "Indicates that front seat heater temp sensor has a short circuit";
CM_ SG_ 1373 VCSEATD_a242_snsDisconnect "Indicates that front seat heater temp sensor is disconnected";
CM_ SG_ 1373 VCSEATD_a242_snsRateChangeUp "Indicates that front seat heater temp sensor rising rate of change was too high";
CM_ SG_ 1373 VCSEATD_a242_snsRateChangeDown "Indicates that front seat heater temp sensor falling rate of change was too high";
CM_ SG_ 892 VCSEATD_matrixIndex "Alert Matrix multiplexer index";
CM_ SG_ 892 VCSEATD_a001_WatchdogReset "Warns if the processor has experienced a reset due to watchdog reset.";
CM_ SG_ 892 VCSEATD_a002_PowerLossReset "Warns if the processor has experienced a reset due to power loss.";
CM_ SG_ 892 VCSEATD_a003_SWAssertion "An internal software assertion has failed.";
CM_ SG_ 892 VCSEATD_a005_CANTXError "An error has been detected with CAN transmission. Used by engineering to debug.";
CM_ SG_ 892 VCSEATD_a010_ExtSupplyVoltError "The external 12V supply voltage from the vehicle is out of range.";
CM_ SG_ 892 VCSEATD_a012_CPUReset "CPU detected a reset.";
CM_ SG_ 892 VCSEATD_a013_AlertManagerFault "Alert Manager encountered an internal processing error.";
CM_ SG_ 892 VCSEATD_a015_NVMMAlert "An issue is indicated from the non-volatile memory manager.";
CM_ SG_ 892 VCSEATD_a021_TaskSchedulerError "If a task was not able to run at the appropriate time.";
CM_ SG_ 892 VCSEATD_a022_TaskInitError "If a task failed to initialize.";
CM_ SG_ 892 VCSEATD_a030_ECULogUploadRequest "Triggers on board diagnostics service to upload log buffer.";
CM_ SG_ 892 VCSEATD_a031_UDSActive "A unified diagnostics services (UDS) request was made";
CM_ SG_ 892 VCSEATD_a041_HighCPULoad "CPU under heavy load.";
CM_ SG_ 892 VCSEATD_a042_HighStackUsage "High stack memory usage was detected";
CM_ SG_ 892 VCSEATD_a043_Task1msError "Debug information for 1ms task errors.";
CM_ SG_ 892 VCSEATD_a044_Task10msError "Debug information for 10ms task errors";
CM_ SG_ 892 VCSEATD_a045_Task100msError "Debug information for 100ms task errors.";
CM_ SG_ 892 VCSEATD_a046_Task1000msError "Debug information for 1000ms task errors.";
CM_ SG_ 892 VCSEATD_a058_inputRHighSyncDebug "Voltage drop on input power is high";
CM_ SG_ 892 VCSEATD_a059_inputResistanceHigh "Voltage drop on input power is high";
CM_ SG_ 892 VCSEATD_a060_engineeringBuild "The firmware on this car is for engineering use only";
CM_ SG_ 892 VCSEATD_a061_XCPConnected "Indicates an active connection to the universal measurement and calibration protocol state machine";
CM_ SG_ 892 VCSEATD_a062_XCPWasConnected "Indicates there was an active connection to the universal measurement and calibration protocol state machine";
CM_ SG_ 892 VCSEATD_a063_SwitchFault "An issue with a switch has been detected.";
CM_ SG_ 892 VCSEATD_a064_busSleepReqTimeout "Indicates if a bus has timed out of a sleep request from the network manager";
CM_ SG_ 892 VCSEATD_a200_motorPhantomEncoder "Motor encoders are moving without motor being driven";
CM_ SG_ 892 VCSEATD_a201_motorDutyEncDisabl "Motor is being driven, but encoders are locked";
CM_ SG_ 892 VCSEATD_a218_motorDriverFault "DRV8702 bridge driver has pulled its nFault pin low";
CM_ SG_ 892 VCSEATD_a219_motorCurrentDropout "Some motor current readings are unreliable";
CM_ SG_ 892 VCSEATD_a220_seatCurrStallTrack "The motor has unexpectedly stalled";
CM_ SG_ 892 VCSEATD_a221_seatCurrStallBack "The motor has unexpectedly stalled";
CM_ SG_ 892 VCSEATD_a222_seatCurrStallTilt "The motor has unexpectedly stalled";
CM_ SG_ 892 VCSEATD_a223_seatCurrStallLift "The motor has unexpectedly stalled";
CM_ SG_ 892 VCSEATD_a224_seatEncStallTrack "The motor isn't providing encoder feedback";
CM_ SG_ 892 VCSEATD_a225_seatEncStallBack "The motor isn't providing encoder feedback";
CM_ SG_ 892 VCSEATD_a226_seatEncStallTilt "The motor isn't providing encoder feedback";
CM_ SG_ 892 VCSEATD_a227_seatEncStallLift "The motor isn't providing encoder feedback";
CM_ SG_ 892 VCSEATD_a228_seatEncOverTrack "The motor has traveled beyond the expected range";
CM_ SG_ 892 VCSEATD_a229_seatEncOverBack "The motor has traveled beyond the expected range";
CM_ SG_ 892 VCSEATD_a230_seatEncOverTilt "The motor has traveled beyond the expected range";
CM_ SG_ 892 VCSEATD_a231_seatEncOverLift "The motor has traveled beyond the expected range";
CM_ SG_ 892 VCSEATD_a232_seatCurrUnderTrack "The motor isn't responding";
CM_ SG_ 892 VCSEATD_a233_seatCurrUnderBack "The motor isn't responding";
CM_ SG_ 892 VCSEATD_a234_seatCurrUnderTilt "The motor isn't responding";
CM_ SG_ 892 VCSEATD_a235_seatCurrUnderLift "The motor isn't responding";
CM_ SG_ 892 VCSEATD_a236_lumbarOverPresA "The bladder A has exceeded pressure limits";
CM_ SG_ 892 VCSEATD_a237_lumbarOverPresB "The bladder B has exceeded pressure limits";
CM_ SG_ 892 VCSEATD_a238_lumbarValveMIA "The valveblock isn't inflating or deflating when commanded";
CM_ SG_ 892 VCSEATD_a239_seatHeatIFront "The seat heater has had unusually high current draw";
CM_ SG_ 892 VCSEATD_a240_seatHeatShortFront "HSD for seat heater has shorted";
CM_ SG_ 892 VCSEATD_a241_seatHeatMIAFront "seat heater isn't drawing any current";
CM_ SG_ 892 VCSEATD_a242_seatHeatTmpFront "The front seat heater temperature sensor has an electrical fault. This sensor is used for fault management of the airbag system";
CM_ SG_ 892 VCSEATD_a251_seatUncalTrack "The track motor is uncalibrated";
CM_ SG_ 892 VCSEATD_a252_seatUncalBack "The backrest motor is uncalibrated";
CM_ SG_ 892 VCSEATD_a253_seatUncalTilt "The tilt motor is uncalibrated";
CM_ SG_ 892 VCSEATD_a254_seatUncalLift "The lift motor is uncalibrated";
CM_ SG_ 892 VCSEATD_a263_seatTrackStallDebug "The track motor has unexpectedly stalled";
CM_ SG_ 892 VCSEATD_a264_seatBackStallDebug "The backrest motor has unexpectedly stalled";
CM_ SG_ 892 VCSEATD_a265_seatTiltStallDebug "The tilt motor has unexpectedly stalled";
CM_ SG_ 892 VCSEATD_a266_seatLiftStallDebug "The lift motor has unexpectedly stalled";
CM_ SG_ 892 VCSEATD_a267_seatTrackHCEncStl "The track motor encoder has unexpectedly stalled";
CM_ SG_ 892 VCSEATD_a268_seatBackHCEncStlDbg "The backrest motor encoder has unexpectedly stalled";
CM_ SG_ 892 VCSEATD_a269_seatTiltHCEncStlDbg "The tilt motor encoder has unexpectedly stalled";
CM_ SG_ 892 VCSEATD_a270_seatLiftHCEncStlDbg "The lift motor encoder has unexpectedly stalled";
CM_ SG_ 892 VCSEATD_a290_occupancyFaultFront "The front seat occupancy sensor is faulted";
CM_ SG_ 892 VCSEATD_a291_buckleFaultedFront "The front seat buckle sensor is faulted";
CM_ SG_ 892 VCSEATD_a380_ocsCushionHigh "The Cushion occupancy sensor reads a high value";
CM_ SG_ 892 VCSEATD_a381_ocsCushionLow "The Cushion occupancy sensor reads a low value";
CM_ SG_ 892 VCSEATD_a382_ocsCushionShort "The Cushion occupancy sensor reads as shorted to ground";
CM_ SG_ 892 VCSEATD_a386_ocsSpareHigh "The Spare occupancy sensor reads a high value";
CM_ SG_ 892 VCSEATD_a387_ocsSpareLow "The Spare occupancy sensor reads a low value";
CM_ SG_ 892 VCSEATD_a388_ocsSpareShort "The Spare occupancy sensor reads as shorted to ground";
CM_ SG_ 892 VCSEATD_a389_ocsTHInvalid "The Temp Humidity occupancy sensor reads invalid value";
CM_ SG_ 892 VCSEATD_a390_ocsCushionNoCalib "The Cushion occupancy sensor calibration is missing";
CM_ SG_ 892 VCSEATD_a392_ocsSpareNoCalib "The Spare occupancy sensor calibration is missing";
CM_ SG_ 892 VCSEATD_a393_ocsTHNoCalib "The Temp Humidity occupancy sensor calibration is missing";
CM_ SG_ 892 VCSEATD_a394_ocsCushionInvlCalib "The Cushion occupancy sensor calibration is present, but invalid";
CM_ SG_ 892 VCSEATD_a396_ocsSpareInvalCalib "The Spare occupancy sensor calibration is present, but invalid";
CM_ SG_ 892 VCSEATD_a397_ocsTHInvalCalib "The Temp Humidity occupancy sensor calibration is present, but invalid";
CM_ SG_ 892 VCSEATD_a398_ocsTOSMIA "The TOS communication failed";
CM_ SG_ 892 VCSEATD_a399_ocsTHMIA "The Temp Humidity occupancy sensor communication failed";
CM_ SG_ 892 VCSEATD_a400_ocsCushionMismatch "The Cushion occupancy sensor reading does not match other occupancy sensors";
CM_ SG_ 892 VCSEATD_a401_ocsDiagContext "Alert that provides metadata context to other alerts. Does not mean anything on its own.";
CM_ SG_ 892 VCSEATD_a402_ocsSensorLow "OCS Sensor reading is lower than expected";
CM_ SG_ 892 VCSEATD_a403_ocsSensorHigh "OCS Sensor reading is higher than expected";
CM_ SG_ 892 VCSEATD_a404_ocsBackDisconnect "OCS Seatback is likely disconnected";
CM_ SG_ 892 VCSEATD_a405_ocsSensorDisconnect "OCS both seatback and cushion likely disconnected";
CM_ SG_ 892 VCSEATD_a406_ocsCalibMismatch "OCS empty seat calibration is mismatched with calibration programmed at board manufacturing";
CM_ SG_ 892 VCSEATD_a407_ocsManufactureInvld "OCS has been incorrectly calibrated by the manufacturer";
CM_ SG_ 892 VCSEATD_a408_ocsSensorDroop "OCS Sensor reading is lower than expected";
CM_ SG_ 892 VCSEATD_a409_ocsHeatPadNoConnect "OCS cushion or heat pad has been disconnected";
CM_ SG_ 892 VCSEATD_a410_ocsSlowDrift "OCS capacitance reading has drifted over 24 hourly(not necessarily consecutive) samples. This is a silent alert";
CM_ SG_ 892 VCSEATD_a411_ocsDataTimeout "TOS sensor data not received on startup";
CM_ SG_ 892 VCSEATD_a412_ocsRebaselineDBG "OCS baseline was reset to zero out seat. Debug only";
CM_ SG_ 892 VCSEATD_a413_ocsSBRFaulted "The seat occupancy switch is faulted";
CM_ SG_ 892 VCSEATD_a414_ocsMissedIngressDBG "On wakeup, OCS missed an occupant ingress. Occupant switch was pressed on startup. Debug only";
CM_ SG_ 892 VCSEATD_a415_ocsRebaseEgressDBG "On egress, OCS decided to rebaseline after missing ingress. Debug only";
CM_ SG_ 892 VCSEATD_a444_drv8703Fault "DRV8703 bridge driver faulted";
CM_ SG_ 892 VCSEATD_a445_drv8703SpiFaultDBG "DRV8703 bridge driver SPI data is unexpected";
CM_ SG_ 770 VCSEATD_infoBuildConfigId "SW-243974";
CM_ SG_ 1841 VCSEATD_classificationRaw "Occupant classification, ignoring classification lock";
CM_ SG_ 1843 VCSEATD_ocsFieldCalibrated "The currently stored OCS calibration did not come from 901 Page, instead it was calibrated afterwards, by UDS routine";
BA_DEF_ BO_ "AlertLogSubSystemId" INT 0 0;
BA_DEF_ BO_ "AlertType" INT 0 4;
BA_DEF_ BO_ "AppBotschaft" ENUM "nein","ja";
BA_DEF_ BO_ "DiagRequest" ENUM "No","Yes";
BA_DEF_ BO_ "DiagResponse" ENUM "No","Yes";
BA_DEF_ BO_ "ETHGatewayMessageSendType" ENUM "UseGenMsgSendType","onWrite","noAutoCode";
BA_DEF_ BO_ "ETHId" STRING ;
BA_DEF_ BO_ "GatewayHandlerEnum" ENUM "noHandler","uds","alertLog","messageLogOnReception","udsClient";
BA_DEF_ BO_ "GatewayMessageAtomic" ENUM "No","Yes";
BA_DEF_ BO_ "GatewayMessageSendType" ENUM "UseGenMsgSendType","onWrite","noAutoCode";
BA_DEF_ BO_ "GenMsgCycleTime" INT 0 0;
BA_DEF_ BO_ "GenMsgCycleTimeFast" INT 0 0;
BA_DEF_ BO_ "GenMsgDelayTime" INT 0 0;
BA_DEF_ BO_ "GenMsgForceMiaCheck" ENUM "No","Yes";
BA_DEF_ BO_ "GenMsgGatewayNotification" STRING ;
BA_DEF_ BO_ "GenMsgILSupport" ENUM "No","Yes";
BA_DEF_ BO_ "GenMsgSaltingFunction" ENUM "No","Yes";
BA_DEF_ BO_ "GenMsgSendType" ENUM "Cyclic","NotUsed","NotUsed","NotUsed","NotUsed","NotUsed","NotUsed","IfActive","NoMsgSendType","Sporadic";
BA_DEF_ BO_ "GenMsgStartValue" STRING ;
BA_DEF_ BO_ "GenMsgTimeOut" INT 0 0;
BA_DEF_ BO_ "MessageIdType" ENUM "normal","udsRequest","udsResponse","udsReserved","udsFunctionalRequest","networkManagement","bootloader","xcp","dtc","diagnostic","vendorExempt";
BA_DEF_ BO_ "NWMBotschaft" ENUM "nein","ja";
BA_DEF_ BO_ "NmMessage" ENUM "No","Yes";
BA_DEF_ BO_ "SubSystemId" INT 0 256;
BA_DEF_ BO_ "UsesChecksum" ENUM "No","Yes";
BA_DEF_ SG_ "FieldType" STRING ;
BA_DEF_ SG_ "FlexKomComment" STRING ;
BA_DEF_ SG_ "FlexKomIsMotorola" ENUM "nein","ja";
BA_DEF_ SG_ "FlexKomSID" INT 0 2147483647;
BA_DEF_ SG_ "FlexKomSigLaenge" INT 0 64;
BA_DEF_ SG_ "FlexKomSigName" STRING ;
BA_DEF_ SG_ "FlexKomSigStartPos" INT 0 63;
BA_DEF_ SG_ "FlexKomSigStartValue" STRING ;
BA_DEF_ SG_ "Gatewaysignal" INT 0 1;
BA_DEF_ SG_ "GenSigCycleTime" INT 0 0;
BA_DEF_ SG_ "GenSigCycleTimeActive" INT 0 0;
BA_DEF_ SG_ "GenSigPersistent" ENUM "No","Yes";
BA_DEF_ SG_ "GenSigSNA" STRING ;
BA_DEF_ SG_ "GenSigSendType" ENUM "Cyclic","OnWrite","OnWriteWithRepetition","OnChange","OnChangeWithRepetition","IfActive","IfActiveWithRepetition","NoSigSendType","NotUsed","NotUsed","NotUsed","NotUsed","NotUsed";
BA_DEF_ SG_ "GenSigStartValue" INT 0 0;
BA_DEF_ SG_ "GenSigTimeout_CGW" INT 0 65535;
BA_DEF_ SG_ "GenSigTimeout_DRVU" INT 0 65535;
BA_DEF_ SG_ "GenSigTimeout_ECM" INT 0 65535;
BA_DEF_ SG_ "GenSigTimeout_EIS" INT 0 65535;
BA_DEF_ SG_ "GenSigTimeout_EPS" INT 0 65535;
BA_DEF_ SG_ "GenSigTimeout_ESP_ABR" INT 0 65535;
BA_DEF_ SG_ "GenSigTimeout_IC" INT 0 65535;
BA_DEF_ SG_ "GenSigTimeout_MPC" INT 0 65535;
BA_DEF_ SG_ "GenSigTimeout_NV" INT 0 65535;
BA_DEF_ SG_ "GenSigTimeout_ORC" INT 0 65535;
BA_DEF_ SG_ "GenSigTimeout_PTS" INT 0 65535;
BA_DEF_ SG_ "GenSigTimeout_RBTM_FL" INT 0 65535;
BA_DEF_ SG_ "GenSigTimeout_RBTM_FR" INT 0 65535;
BA_DEF_ SG_ "GenSigTimeout_RDU" INT 0 65535;
BA_DEF_ SG_ "GenSigTimeout_SCCM" INT 0 65535;
BA_DEF_ SG_ "GenSigTimeout_SPC" INT 0 65535;
BA_DEF_ SG_ "GenSigTimeout_TPM" INT 0 65535;
BA_DEF_ SG_ "LogSignal" STRING ;
BA_DEF_ SG_ "PektronUpdateBitType" ENUM "Not used","Has update bit","Is update bit";
BA_DEF_REL_ BU_SG_REL_ "GenSigTimeoutTime" INT 0 0;

BA_DEF_DEF_ "AlertLogSubSystemId" 0;
BA_DEF_DEF_ "AlertType" 4;
BA_DEF_DEF_ "AppBotschaft" "nein";
BA_DEF_DEF_ "DiagRequest" "No";
BA_DEF_DEF_ "DiagResponse" "No";
BA_DEF_DEF_ "ETHGatewayMessageSendType" "UseGenMsgSendType";
BA_DEF_DEF_ "ETHId" "";
BA_DEF_DEF_ "FieldType" "";
BA_DEF_DEF_ "FlexKomComment" "";
BA_DEF_DEF_ "FlexKomIsMotorola" "";
BA_DEF_DEF_ "FlexKomSID" 0;
BA_DEF_DEF_ "FlexKomSigLaenge" 0;
BA_DEF_DEF_ "FlexKomSigName" "";
BA_DEF_DEF_ "FlexKomSigStartPos" 0;
BA_DEF_DEF_ "FlexKomSigStartValue" "";
BA_DEF_DEF_ "GatewayHandlerEnum" "noHandler";
BA_DEF_DEF_ "GatewayMessageAtomic" "No";
BA_DEF_DEF_ "GatewayMessageSendType" "UseGenMsgSendType";
BA_DEF_DEF_ "Gatewaysignal" 0;
BA_DEF_DEF_ "GenMsgCycleTime" 0;
BA_DEF_DEF_ "GenMsgCycleTimeFast" 0;
BA_DEF_DEF_ "GenMsgDelayTime" 0;
BA_DEF_DEF_ "GenMsgForceMiaCheck" "No";
BA_DEF_DEF_ "GenMsgGatewayNotification" "";
BA_DEF_DEF_ "GenMsgILSupport" "Yes";
BA_DEF_DEF_ "GenMsgSaltingFunction" "No";
BA_DEF_DEF_ "GenMsgSendType" "Cyclic";
BA_DEF_DEF_ "GenMsgStartValue" "";
BA_DEF_DEF_ "GenMsgTimeOut" 0;
BA_DEF_DEF_ "GenSigCycleTime" 0;
BA_DEF_DEF_ "GenSigCycleTimeActive" 0;
BA_DEF_DEF_ "GenSigPersistent" "No";
BA_DEF_DEF_ "GenSigSNA" "";
BA_DEF_DEF_ "GenSigSendType" "Cyclic";
BA_DEF_DEF_ "GenSigStartValue" 0;
BA_DEF_DEF_ "GenSigTimeout_CGW" 0;
BA_DEF_DEF_ "GenSigTimeout_DRVU" 0;
BA_DEF_DEF_ "GenSigTimeout_ECM" 0;
BA_DEF_DEF_ "GenSigTimeout_EIS" 0;
BA_DEF_DEF_ "GenSigTimeout_EPS" 0;
BA_DEF_DEF_ "GenSigTimeout_ESP_ABR" 0;
BA_DEF_DEF_ "GenSigTimeout_IC" 0;
BA_DEF_DEF_ "GenSigTimeout_MPC" 0;
BA_DEF_DEF_ "GenSigTimeout_NV" 0;
BA_DEF_DEF_ "GenSigTimeout_ORC" 0;
BA_DEF_DEF_ "GenSigTimeout_PTS" 0;
BA_DEF_DEF_ "GenSigTimeout_RBTM_FL" 0;
BA_DEF_DEF_ "GenSigTimeout_RBTM_FR" 0;
BA_DEF_DEF_ "GenSigTimeout_RDU" 0;
BA_DEF_DEF_ "GenSigTimeout_SCCM" 0;
BA_DEF_DEF_ "GenSigTimeout_SPC" 0;
BA_DEF_DEF_ "GenSigTimeout_TPM" 0;
BA_DEF_DEF_ "LogSignal" "";
BA_DEF_DEF_ "MessageIdType" "normal";
BA_DEF_DEF_ "NWMBotschaft" "nein";
BA_DEF_DEF_ "NmMessage" "No";
BA_DEF_DEF_ "PektronUpdateBitType" "Not used";
BA_DEF_DEF_ "SubSystemId" 0;
BA_DEF_DEF_ "UsesChecksum" "No";
BA_DEF_DEF_REL_ "GenSigTimeoutTime" 0;
BA_ "GatewayMessageSendType" BO_ 555 1;
BA_ "GenMsgCycleTime" BO_ 555 10;
BA_ "GenMsgCycleTime" BO_ 1610 100;
BA_ "GatewayMessageSendType" BO_ 1307 1;
BA_ "GenMsgCycleTime" BO_ 1307 1000;
BA_ "GenMsgSendType" BO_ 1546 7;
BA_ "GatewayMessageSendType" BO_ 539 1;
BA_ "GenMsgCycleTime" BO_ 539 100;
BA_ "DiagResponse" BO_ 1627 1;
BA_ "GatewayHandlerEnum" BO_ 1627 4;
BA_ "GenMsgSendType" BO_ 1627 8;
BA_ "GenMsgTimeOut" BO_ 1627 500;
BA_ "MessageIdType" BO_ 1627 2;
BA_ "GatewayMessageSendType" BO_ 409 1;
BA_ "GenMsgCycleTime" BO_ 409 50;
BA_ "GatewayMessageSendType" BO_ 410 1;
BA_ "GenMsgCycleTime" BO_ 410 50;
BA_ "GatewayMessageSendType" BO_ 525 1;
BA_ "GenMsgCycleTime" BO_ 525 100;
BA_ "AlertType" BO_ 843 3;
BA_ "GatewayMessageSendType" BO_ 843 1;
BA_ "GenMsgCycleTime" BO_ 843 1000;
BA_ "SubSystemId" BO_ 843 207;
BA_ "AlertType" BO_ 859 3;
BA_ "GatewayMessageSendType" BO_ 859 1;
BA_ "GenMsgCycleTime" BO_ 859 1000;
BA_ "SubSystemId" BO_ 859 207;
BA_ "AlertType" BO_ 875 3;
BA_ "GatewayMessageSendType" BO_ 875 1;
BA_ "GenMsgCycleTime" BO_ 875 1000;
BA_ "SubSystemId" BO_ 875 207;
BA_ "AlertType" BO_ 891 3;
BA_ "GatewayMessageSendType" BO_ 891 1;
BA_ "GenMsgCycleTime" BO_ 891 1000;
BA_ "SubSystemId" BO_ 891 207;
BA_ "AlertType" BO_ 907 3;
BA_ "GatewayMessageSendType" BO_ 907 1;
BA_ "GenMsgCycleTime" BO_ 907 1000;
BA_ "SubSystemId" BO_ 907 207;
BA_ "GenMsgSendType" BO_ 895 8;
BA_ "GenMsgCycleTime" BO_ 879 1000;
BA_ "GenMsgCycleTime" BO_ 863 1000;
BA_ "GenMsgCycleTime" BO_ 831 1000;
BA_ "GenMsgCycleTime" BO_ 799 1000;
BA_ "GenMsgForceMiaCheck" BO_ 799 1;
BA_ "GenMsgSendType" BO_ 1519 8;
BA_ "GenMsgCycleTime" BO_ 783 1000;
BA_ "GatewayHandlerEnum" BO_ 1631 4;
BA_ "GenMsgSendType" BO_ 1631 8;
BA_ "MessageIdType" BO_ 1631 2;
BA_ "DiagRequest" BO_ 1609 1;
BA_ "GenMsgSendType" BO_ 1609 8;
BA_ "MessageIdType" BO_ 1609 1;
BA_ "DiagRequest" BO_ 1584 1;
BA_ "GenMsgCycleTime" BO_ 1584 100;
BA_ "GenMsgSendType" BO_ 1584 8;
BA_ "MessageIdType" BO_ 1584 1;
BA_ "DiagRequest" BO_ 1840 1;
BA_ "GenMsgCycleTime" BO_ 1840 100;
BA_ "GenMsgSendType" BO_ 1840 8;
BA_ "MessageIdType" BO_ 1840 1;
BA_ "DiagRequest" BO_ 1604 1;
BA_ "GenMsgSendType" BO_ 1604 8;
BA_ "MessageIdType" BO_ 1604 1;
BA_ "DiagRequest" BO_ 1607 1;
BA_ "GenMsgSendType" BO_ 1607 8;
BA_ "MessageIdType" BO_ 1607 1;
BA_ "DiagRequest" BO_ 1605 1;
BA_ "GenMsgCycleTimeFast" BO_ 1605 100;
BA_ "GenMsgDelayTime" BO_ 1605 20;
BA_ "GenMsgSendType" BO_ 1605 8;
BA_ "MessageIdType" BO_ 1605 1;
BA_ "DiagRequest" BO_ 2015 1;
BA_ "GenMsgCycleTime" BO_ 2015 100;
BA_ "GenMsgCycleTimeFast" BO_ 2015 100;
BA_ "GenMsgDelayTime" BO_ 2015 20;
BA_ "GenMsgSendType" BO_ 2015 8;
BA_ "MessageIdType" BO_ 2015 4;
BA_ "GenMsgSendType" BO_ 1613 8;
BA_ "MessageIdType" BO_ 1613 1;
BA_ "DiagRequest" BO_ 1612 1;
BA_ "GenMsgSendType" BO_ 1612 8;
BA_ "MessageIdType" BO_ 1612 1;
BA_ "DiagRequest" BO_ 1603 1;
BA_ "GenMsgSendType" BO_ 1603 8;
BA_ "MessageIdType" BO_ 1603 1;
BA_ "DiagRequest" BO_ 1614 1;
BA_ "GenMsgSendType" BO_ 1614 8;
BA_ "MessageIdType" BO_ 1614 1;
BA_ "DiagRequest" BO_ 1649 1;
BA_ "GenMsgSendType" BO_ 1649 8;
BA_ "MessageIdType" BO_ 1649 1;
BA_ "DiagRequest" BO_ 1652 1;
BA_ "GenMsgSendType" BO_ 1652 8;
BA_ "MessageIdType" BO_ 1652 1;
BA_ "DiagRequest" BO_ 1653 1;
BA_ "GenMsgSendType" BO_ 1653 8;
BA_ "MessageIdType" BO_ 1653 1;
BA_ "DiagRequest" BO_ 1650 1;
BA_ "GenMsgSendType" BO_ 1650 8;
BA_ "MessageIdType" BO_ 1650 1;
BA_ "DiagRequest" BO_ 1651 1;
BA_ "GenMsgSendType" BO_ 1651 8;
BA_ "MessageIdType" BO_ 1651 1;
BA_ "DiagRequest" BO_ 2033 1;
BA_ "GenMsgSendType" BO_ 2033 8;
BA_ "MessageIdType" BO_ 2033 1;
BA_ "DiagRequest" BO_ 1601 1;
BA_ "GenMsgSendType" BO_ 1601 8;
BA_ "MessageIdType" BO_ 1601 1;
BA_ "AppBotschaft" BO_ 1936 1;
BA_ "DiagRequest" BO_ 1936 1;
BA_ "GenMsgSendType" BO_ 1936 8;
BA_ "GenMsgStartValue" BO_ 1936 "0000000000000000h";
BA_ "MessageIdType" BO_ 1936 1;
BA_ "GenMsgSendType" BO_ 1611 1;
BA_ "MessageIdType" BO_ 1611 1;
BA_ "DiagRequest" BO_ 1615 1;
BA_ "GenMsgCycleTimeFast" BO_ 1615 100;
BA_ "GenMsgDelayTime" BO_ 1615 20;
BA_ "GenMsgSendType" BO_ 1615 8;
BA_ "MessageIdType" BO_ 1615 1;
BA_ "GenMsgSendType" BO_ 1760 1;
BA_ "MessageIdType" BO_ 1760 1;
BA_ "GenMsgSendType" BO_ 1762 1;
BA_ "MessageIdType" BO_ 1762 1;
BA_ "GatewayMessageSendType" BO_ 1006 1;
BA_ "GenMsgCycleTime" BO_ 1006 1000;
BA_ "GatewayMessageSendType" BO_ 728 1;
BA_ "GenMsgCycleTime" BO_ 728 100;
BA_ "GatewayMessageSendType" BO_ 744 1;
BA_ "GenMsgCycleTime" BO_ 744 100;
BA_ "GatewayMessageSendType" BO_ 1080 1;
BA_ "GenMsgCycleTime" BO_ 1080 1000;
BA_ "GenMsgSendType" BO_ 1080 7;
BA_ "GatewayMessageSendType" BO_ 1000 1;
BA_ "GenMsgCycleTime" BO_ 1000 1000;
BA_ "GatewayMessageSendType" BO_ 968 1;
BA_ "GenMsgCycleTime" BO_ 968 500;
BA_ "GatewayMessageSendType" BO_ 568 1;
BA_ "GenMsgCycleTime" BO_ 568 100;
BA_ "GenMsgCycleTime" BO_ 641 500;
BA_ "GatewayMessageSendType" BO_ 760 1;
BA_ "GenMsgCycleTime" BO_ 760 1000;
BA_ "GatewayMessageSendType" BO_ 990 1;
BA_ "GenMsgCycleTime" BO_ 990 1000;
BA_ "GatewayMessageSendType" BO_ 984 1;
BA_ "GenMsgCycleTime" BO_ 984 1000;
BA_ "GatewayMessageSendType" BO_ 986 1;
BA_ "GenMsgCycleTime" BO_ 986 1000;
BA_ "GatewayMessageSendType" BO_ 696 1;
BA_ "GenMsgCycleTime" BO_ 696 100;
BA_ "GatewayMessageSendType" BO_ 712 1;
BA_ "GenMsgCycleTime" BO_ 712 100;
BA_ "GenMsgCycleTime" BO_ 582 1000;
BA_ "GatewayMessageSendType" BO_ 824 1;
BA_ "GenMsgCycleTime" BO_ 824 1000;
BA_ "GatewayMessageSendType" BO_ 1070 1;
BA_ "GenMsgCycleTime" BO_ 1070 1000;
BA_ "GatewayMessageSendType" BO_ 987 1;
BA_ "GenMsgCycleTime" BO_ 987 1000;
BA_ "GatewayMessageSendType" BO_ 660 1;
BA_ "GenMsgCycleTime" BO_ 660 500;
BA_ "GatewayMessageSendType" BO_ 1064 1;
BA_ "GenMsgCycleTime" BO_ 1064 1000;
BA_ "GatewayMessageSendType" BO_ 1827 1;
BA_ "GenMsgSendType" BO_ 1827 8;
BA_ "GatewayMessageSendType" BO_ 1829 1;
BA_ "GenMsgSendType" BO_ 1829 8;
BA_ "GenMsgCycleTime" BO_ 627 500;
BA_ "GenMsgCycleTime" BO_ 898 1000;
BA_ "GenMsgSendType" BO_ 1854 7;
BA_ "GenMsgCycleTime" BO_ 578 100;
BA_ "AlertLogSubSystemId" BO_ 1373 286;
BA_ "GatewayHandlerEnum" BO_ 1373 2;
BA_ "GatewayMessageSendType" BO_ 892 1;
BA_ "GenMsgCycleTime" BO_ 892 100;
BA_ "GenMsgCycleTime" BO_ 866 1000;
BA_ "GenMsgCycleTime" BO_ 770 1000;
BA_ "GenMsgCycleTime" BO_ 1841 40;
BA_ "GenMsgCycleTime" BO_ 1843 10000;
BA_ "GenSigSNA" SG_ 555 TAS_rawHeightFL "255";
BA_ "GenSigSNA" SG_ 555 TAS_rawHeightFR "255";
BA_ "GenSigSNA" SG_ 555 TAS_rawHeightRL "255";
BA_ "GenSigSNA" SG_ 555 TAS_rawHeightRR "255";
BA_ "FieldType" SG_ 1610 TAS_debugStates "debugStatesType";
BA_ "FieldType" SG_ 1307 TAS_infoIndex "bcInfoIndex";
BA_ "FieldType" SG_ 1307 TAS_infoBuildType "buildType";
BA_ "FieldType" SG_ 1307 TAS_infoAssemblyId "infoAssemblyID";
BA_ "GenSigSNA" SG_ 1307 TAS_infoAssemblyId "255";
BA_ "GenSigStartValue" SG_ 1307 TAS_infoAppCrc 4294967295;
BA_ "GenSigStartValue" SG_ 1307 TAS_infoPlatformType 255;
BA_ "FieldType" SG_ 1307 TAS_infoMajorVersion "infoVersion";
BA_ "GenSigSNA" SG_ 1307 TAS_infoMajorVersion "255";
BA_ "FieldType" SG_ 1307 TAS_infoBranchOrigin "infoVersion";
BA_ "GenSigSNA" SG_ 1307 TAS_infoBranchOrigin "255";
BA_ "FieldType" SG_ 1307 TAS_infoMaturity "infoVersion";
BA_ "GenSigSNA" SG_ 1307 TAS_infoMaturity "255";
BA_ "FieldType" SG_ 1307 TAS_infoHardwareRevision "infoVersion";
BA_ "GenSigSNA" SG_ 1307 TAS_infoHardwareRevision "255";
BA_ "LogSignal" SG_ 1546 TAS_logComponentPressureFL "onChange";
BA_ "LogSignal" SG_ 1546 TAS_logComponentPressureFR "onChange";
BA_ "LogSignal" SG_ 1546 TAS_logComponentPressureRL "onChange";
BA_ "LogSignal" SG_ 1546 TAS_logComponentPressureRR "onChange";
BA_ "FieldType" SG_ 539 TAS_levelingState "TAS_levelingState";
BA_ "LogSignal" SG_ 539 TAS_levelingState "onChange";
BA_ "FieldType" SG_ 539 TAS_levelingItem "TAS_levelingItem";
BA_ "LogSignal" SG_ 539 TAS_levelingItem "onChange";
BA_ "GenSigSNA" SG_ 539 TAS_pressureGallery "255";
BA_ "LogSignal" SG_ 539 TAS_pressureGallery "periodic ONE_MINUTE Any";
BA_ "GenSigSNA" SG_ 539 TAS_pressureReservoir "255";
BA_ "LogSignal" SG_ 539 TAS_pressureReservoir "onChange";
BA_ "FieldType" SG_ 539 TAS_runMode "TAS_runMode";
BA_ "LogSignal" SG_ 539 TAS_runMode "onChange";
BA_ "FieldType" SG_ 539 TAS_filterMode "TAS_filterMode";
BA_ "LogSignal" SG_ 539 TAS_filterMode "onChange";
BA_ "FieldType" SG_ 539 TAS_limpHomeMode "TAS_limpHomeMode";
BA_ "LogSignal" SG_ 539 TAS_limpHomeMode "onChange";
BA_ "FieldType" SG_ 539 TAS_targetLevel "TAS_level";
BA_ "LogSignal" SG_ 539 TAS_targetLevel "onChange";
BA_ "FieldType" SG_ 539 TAS_currentLevel "TAS_level";
BA_ "LogSignal" SG_ 539 TAS_currentLevel "onChange";
BA_ "LogSignal" SG_ 539 TAS_jackMode "onChange";
BA_ "LogSignal" SG_ 539 TAS_reduceVehicleSpeedRequest "onChange";
BA_ "GenSigCycleTimeActive" SG_ 1627 TAS_udsResponseData 100;
BA_ "GenSigSendType" SG_ 1627 TAS_udsResponseData 1;
BA_ "GenSigSNA" SG_ 409 TAS_adaptiveActivityFL_C "31";
BA_ "GenSigSNA" SG_ 409 TAS_adaptiveActivityFL_R "31";
BA_ "GenSigSNA" SG_ 409 TAS_adaptiveActivityFR_C "31";
BA_ "GenSigSNA" SG_ 409 TAS_adaptiveActivityFR_R "31";
BA_ "GenSigSNA" SG_ 409 TAS_adaptiveActivityRL_C "31";
BA_ "GenSigSNA" SG_ 409 TAS_adaptiveActivityRL_R "31";
BA_ "GenSigSNA" SG_ 409 TAS_adaptiveActivityRR_C "31";
BA_ "GenSigSNA" SG_ 409 TAS_adaptiveActivityRR_R "31";
BA_ "GenSigSNA" SG_ 409 TAS_uiHeightFL "63";
BA_ "GenSigSNA" SG_ 409 TAS_uiHeightFR "63";
BA_ "GenSigSNA" SG_ 409 TAS_uiHeightRL "63";
BA_ "GenSigSNA" SG_ 409 TAS_uiHeightRR "63";
BA_ "GenSigSNA" SG_ 410 TAS_bodyAccelFL "255";
BA_ "GenSigSNA" SG_ 410 TAS_bodyAccelFR "255";
BA_ "GenSigSNA" SG_ 410 TAS_bodyAccelRL "255";
BA_ "GenSigSNA" SG_ 410 TAS_bodyAccelRR "255";
BA_ "FieldType" SG_ 525 TAS_adaptiveRideModeOverride "TAS_adaptiveRideMode";
BA_ "GenSigSNA" SG_ 525 TAS_adaptiveRideModeOverride "3";
BA_ "LogSignal" SG_ 525 TAS_adaptiveRideModeOverride "onChange";
BA_ "GenSigSendType" SG_ 1851 TAS_xcpResponse 1;
BA_ "LogSignal" SG_ 879 TPMS_systemMalfunction "onChange";
BA_ "LogSignal" SG_ 879 TPMS_learningStatus "onChange";
BA_ "LogSignal" SG_ 879 TPMS_localisationStatus "onChange";
BA_ "LogSignal" SG_ 879 TPMS_sensorNoResponseFL "onChange";
BA_ "LogSignal" SG_ 879 TPMS_sensorNoResponseFR "onChange";
BA_ "LogSignal" SG_ 879 TPMS_sensorNoResponseRL "onChange";
BA_ "LogSignal" SG_ 879 TPMS_sensorNoResponseRR "onChange";
BA_ "LogSignal" SG_ 863 TPMS_autoLearnFinishedFlag "onChange";
BA_ "LogSignal" SG_ 863 TPMS_noResponseTimeoutFL "periodic ONE_MINUTE driveModeModelS";
BA_ "LogSignal" SG_ 863 TPMS_noResponseTimeoutFR "periodic ONE_MINUTE driveModeModelS";
BA_ "LogSignal" SG_ 863 TPMS_noResponseTimeoutRL "periodic ONE_MINUTE driveModeModelS";
BA_ "LogSignal" SG_ 863 TPMS_noResponseTimeoutRR "periodic ONE_MINUTE driveModeModelS";
BA_ "LogSignal" SG_ 799 TPMS_pressureFL "periodic ONE_SECOND fastLogLevel,periodic TEN_MINUTES driveModeModelS";
BA_ "LogSignal" SG_ 799 TPMS_pressureFR "periodic ONE_SECOND fastLogLevel,periodic TEN_MINUTES driveModeModelS";
BA_ "LogSignal" SG_ 799 TPMS_pressureRL "periodic ONE_SECOND fastLogLevel,periodic TEN_MINUTES driveModeModelS";
BA_ "LogSignal" SG_ 799 TPMS_pressureRR "periodic ONE_SECOND fastLogLevel,periodic TEN_MINUTES driveModeModelS";
BA_ "FieldType" SG_ 1519 TPMS_infoIdx "infoIndex";
BA_ "GenSigCycleTime" SG_ 1519 TPMS_infoIdx 2000;
BA_ "GenSigStartValue" SG_ 1519 TPMS_infoApplicationCRC 4294967295;
BA_ "LogSignal" SG_ 882 TPMS_sensorIDFL "periodic TEN_MINUTES driveModeModelS";
BA_ "LogSignal" SG_ 882 TPMS_sensorIDRR "periodic TEN_MINUTES driveModeModelS";
BA_ "LogSignal" SG_ 882 TPMS_sensorIDFR "periodic TEN_MINUTES driveModeModelS";
BA_ "LogSignal" SG_ 882 TPMS_sensorIDRL "periodic TEN_MINUTES driveModeModelS";
BA_ "LogSignal" SG_ 783 TPMS_systemFault "onChange";
BA_ "LogSignal" SG_ 783 TPMS_autoLearnResult "onChange";
BA_ "GenSigCycleTime" SG_ 1631 TPMS_udsResponseData 100;
BA_ "GenSigCycleTimeActive" SG_ 1631 TPMS_udsResponseData 100;
BA_ "GenSigSendType" SG_ 1609 UDS_dasRequestData 7;
BA_ "GenSigSendType" SG_ 1584 UDS_epas3pRequestData 1;
BA_ "GenSigCycleTime" SG_ 1840 UDS_epasRequestData 100;
BA_ "GenSigCycleTimeActive" SG_ 1840 UDS_epasRequestData 100;
BA_ "GenSigSendType" SG_ 1840 UDS_epasRequestData 1;
BA_ "GenSigSendType" SG_ 1604 UDS_epbRequestData_H 1;
BA_ "GenSigSendType" SG_ 1604 UDS_epbRequestData_L 1;
BA_ "GenSigSendType" SG_ 1607 UDS_epbmRequestData_H 1;
BA_ "GenSigSendType" SG_ 1607 UDS_epbmRequestData_L 1;
BA_ "GenSigCycleTime" SG_ 1605 UDS_espRequestData 100;
BA_ "GenSigCycleTimeActive" SG_ 1605 UDS_espRequestData 100;
BA_ "GenSigSendType" SG_ 1605 UDS_espRequestData 1;
BA_ "GenSigSendType" SG_ 2015 UDS_functionalRequestData_0 1;
BA_ "GenSigSendType" SG_ 2015 UDS_functionalRequestData_1 1;
BA_ "GenSigSendType" SG_ 2015 UDS_functionalRequestData_2 1;
BA_ "GenSigSendType" SG_ 2015 UDS_functionalRequestData_3 1;
BA_ "GenSigSendType" SG_ 2015 UDS_functionalRequestData_4 1;
BA_ "GenSigSendType" SG_ 2015 UDS_functionalRequestData_5 1;
BA_ "GenSigSendType" SG_ 2015 UDS_functionalRequestData_6 1;
BA_ "GenSigSendType" SG_ 2015 UDS_functionalRequestData_7 1;
BA_ "GenSigSendType" SG_ 1613 UDS_ibstRequestData 7;
BA_ "GenSigSendType" SG_ 1612 UDS_icRequestData 1;
BA_ "GenSigSendType" SG_ 1603 UDS_ocsRequestData 1;
BA_ "GenSigSendType" SG_ 1614 UDS_parkRequestData 1;
BA_ "GenSigSendType" SG_ 1649 UDS_radcRequestData 1;
BA_ "GenSigSendType" SG_ 1652 UDS_radflRequestData 1;
BA_ "GenSigSendType" SG_ 1653 UDS_radfrRequestData 1;
BA_ "GenSigSendType" SG_ 1650 UDS_radrlRequestData 1;
BA_ "GenSigSendType" SG_ 1651 UDS_radrrRequestData 1;
BA_ "GenSigSendType" SG_ 2033 UDS_rcmDisposalRequestData 1;
BA_ "GenSigSendType" SG_ 1601 UDS_rcmRequestData 1;
BA_ "FlexKomComment" SG_ 1936 UDS_sccmRequestData "External application to ECU";
BA_ "FlexKomIsMotorola" SG_ 1936 UDS_sccmRequestData 1;
BA_ "FlexKomSID" SG_ 1936 UDS_sccmRequestData 117450569;
BA_ "FlexKomSigLaenge" SG_ 1936 UDS_sccmRequestData 64;
BA_ "FlexKomSigName" SG_ 1936 UDS_sccmRequestData "APPL_SG_SCCM2";
BA_ "FlexKomSigStartPos" SG_ 1936 UDS_sccmRequestData 7;
BA_ "FlexKomSigStartValue" SG_ 1936 UDS_sccmRequestData "0000000000000000h";
BA_ "GenSigSendType" SG_ 1936 UDS_sccmRequestData 7;
BA_ "GenSigSendType" SG_ 1611 UDS_tasRequestData_H 1;
BA_ "GenSigSendType" SG_ 1611 UDS_tasRequestData_L 1;
BA_ "GenSigCycleTime" SG_ 1615 UDS_tpmsRequestData 100;
BA_ "GenSigCycleTimeActive" SG_ 1615 UDS_tpmsRequestData 100;
BA_ "GenSigSendType" SG_ 1615 UDS_tpmsRequestData 1;
BA_ "GenSigSendType" SG_ 1760 UDS_vcseatdRequestData_H 1;
BA_ "GenSigSendType" SG_ 1760 UDS_vcseatdRequestData_L 1;
BA_ "GenSigSendType" SG_ 1762 UDS_vcseatpRequestData_H 1;
BA_ "GenSigSendType" SG_ 1762 UDS_vcseatpRequestData_L 1;
BA_ "FieldType" SG_ 1006 UI_autopilotControlIndex "autopilotControlIndex";
BA_ "GenSigSendType" SG_ 1006 UI_autopilotControlIndex 1;
BA_ "LogSignal" SG_ 1006 UI_hovEnabled "onChange";
BA_ "FieldType" SG_ 1006 UI_donDisableAutoWiperDuration "UI_donDisableAutoWiperDuration";
BA_ "FieldType" SG_ 1006 UI_donDisableOnAutoWiperSpeed "DAS_wiperSpeed";
BA_ "FieldType" SG_ 1006 UI_blindspotMinSpeed "UI_blindspotMinSpeed";
BA_ "FieldType" SG_ 1006 UI_blindspotDistance "UI_blindspotDistance";
BA_ "FieldType" SG_ 1006 UI_blindspotTTC "UI_blindspotTTC";
BA_ "FieldType" SG_ 1006 UI_donStopEndOfRampBuffer "UI_donStopEndOfRampBuffer";
BA_ "FieldType" SG_ 1006 UI_donDisableCutin "UI_donDisableCutin";
BA_ "FieldType" SG_ 1006 UI_donMinGoreWidthForAbortMap "UI_donMinGoreWidthForAbort";
BA_ "GenSigSendType" SG_ 1006 UI_donMinGoreWidthForAbortMap 7;
BA_ "FieldType" SG_ 1006 UI_donAlcProgGoreAbortThres "UI_donAlcProgGoreAbortThres";
BA_ "FieldType" SG_ 1006 UI_donMinGoreWidthForAbortNotMap "UI_donMinGoreWidthForAbort";
BA_ "GenSigSendType" SG_ 1006 UI_donMinGoreWidthForAbortNotMap 7;
BA_ "FieldType" SG_ 1006 UI_homelinkNearby "UI_homelinkNearby";
BA_ "LogSignal" SG_ 1006 UI_driverMonitorConfirmation "onChange";
BA_ "LogSignal" SG_ 1006 UI_applyEceR79 "onChange";
BA_ "LogSignal" SG_ 1006 UI_noStalkConfirmAlertHaptic "onChange";
BA_ "LogSignal" SG_ 1006 UI_noStalkConfirmAlertChime "onChange";
BA_ "LogSignal" SG_ 1006 UI_cameraPoweringOff "onChange";
BA_ "FieldType" SG_ 1006 UI_apmv3Branch "UI_apmv3Branch";
BA_ "LogSignal" SG_ 1006 UI_apmv3Branch "onChange";
BA_ "GenSigSNA" SG_ 1000 UI_summonExitType "3";
BA_ "GenSigSNA" SG_ 1000 UI_summonEntryType "3";
BA_ "GenSigSNA" SG_ 1000 UI_selfParkRequest "15";
BA_ "GenSigSNA" SG_ 1000 UI_summonReverseDist "63";
BA_ "FieldType" SG_ 1000 UI_drivingSide "UI_drivingSide";
BA_ "GenSigSNA" SG_ 968 UI_mapSpeedLimitDependency "7";
BA_ "GenSigSendType" SG_ 968 UI_mapSpeedLimitDependency 1;
BA_ "GenSigStartValue" SG_ 968 UI_mapSpeedLimitDependency 7;
BA_ "GenSigSNA" SG_ 968 UI_roadClass "0";
BA_ "GenSigSendType" SG_ 968 UI_roadClass 1;
BA_ "GenSigSendType" SG_ 968 UI_mapSpeedUnits 1;
BA_ "GenSigSNA" SG_ 968 UI_mapSpeedLimit "31";
BA_ "GenSigSendType" SG_ 968 UI_mapSpeedLimit 1;
BA_ "GenSigStartValue" SG_ 968 UI_mapSpeedLimit 31;
BA_ "GenSigSNA" SG_ 968 UI_mapSpeedLimitType "7";
BA_ "GenSigSendType" SG_ 968 UI_mapSpeedLimitType 1;
BA_ "GenSigSNA" SG_ 968 UI_countryCode "1023";
BA_ "GenSigSendType" SG_ 968 UI_countryCode 1;
BA_ "GenSigStartValue" SG_ 968 UI_countryCode 1023;
BA_ "GenSigSNA" SG_ 968 UI_nextBranchDist "31";
BA_ "GenSigSNA" SG_ 568 UI_splineLocConfidence "0";
BA_ "GenSigSNA" SG_ 568 UI_stopSignStopLineDist "1023";
BA_ "GenSigSNA" SG_ 568 UI_stopSignStopLineConf "0";
BA_ "GenSigSNA" SG_ 568 UI_trafficLightStopLineDist "1023";
BA_ "GenSigSNA" SG_ 568 UI_trafficLightStopLineConf "0";
BA_ "GenSigSNA" SG_ 568 UI_baseMapSpeedLimitMPS "255";
BA_ "GenSigSNA" SG_ 568 UI_bottomQrtlFleetSpeedMPS "255";
BA_ "GenSigSNA" SG_ 568 UI_topQrtlFleetSpeedMPS "255";
BA_ "GenSigSNA" SG_ 568 UI_meanFleetSplineSpeedMPS "255";
BA_ "GenSigSNA" SG_ 568 UI_medianFleetSpeedMPS "255";
BA_ "GenSigSNA" SG_ 568 UI_meanFleetSplineAccelMPS2 "255";
BA_ "GenSigSNA" SG_ 568 UI_rampType "0";
BA_ "GenSigSNA" SG_ 568 UI_valhallaRamp "0";
BA_ "GenSigSNA" SG_ 568 UI_currSplineIdFull "0";
BA_ "GenSigSNA" SG_ 641 UI_driverProfileRecallIndex "0";
BA_ "LogSignal" SG_ 641 UI_frontSeatRecallActive "onChange";
BA_ "LogSignal" SG_ 641 UI_frontSeatTrackPos "onChange";
BA_ "LogSignal" SG_ 641 UI_frontSeatBackPos "onChange";
BA_ "LogSignal" SG_ 641 UI_frontSeatLiftPos "onChange";
BA_ "LogSignal" SG_ 641 UI_frontSeatTiltPos "onChange";
BA_ "GenSigStartValue" SG_ 760 UI_gpsHDOP 255;
BA_ "GenSigSendType" SG_ 760 UI_userSpeedOffset 1;
BA_ "GenSigSendType" SG_ 760 UI_mapSpeedLimitUnits 1;
BA_ "GenSigSendType" SG_ 760 UI_userSpeedOffsetUnits 1;
BA_ "GenSigSendType" SG_ 760 UI_mppSpeedLimit 1;
BA_ "GenSigSNA" SG_ 760 UI_conditionalSpeedLimit "31";
BA_ "GenSigSNA" SG_ 984 UI_gpsAccuracy "127";
BA_ "GenSigStartValue" SG_ 984 UI_gpsAccuracy 127;
BA_ "GenSigSNA" SG_ 986 UI_phoneGpsAccuracy "127";
BA_ "GenSigStartValue" SG_ 986 UI_phoneGpsAccuracy 127;
BA_ "GenSigSNA" SG_ 582 UI_solarAzimuthAngle "-1";
BA_ "GenSigSendType" SG_ 582 UI_solarAzimuthAngle 1;
BA_ "GenSigStartValue" SG_ 582 UI_solarAzimuthAngle -1;
BA_ "GenSigSNA" SG_ 582 UI_solarAzimuthAngleCarRef "255";
BA_ "GenSigSendType" SG_ 582 UI_solarAzimuthAngleCarRef 1;
BA_ "GenSigStartValue" SG_ 582 UI_solarAzimuthAngleCarRef 255;
BA_ "GenSigSNA" SG_ 582 UI_isSunUp "0";
BA_ "GenSigSNA" SG_ 582 UI_solarElevationAngle "127";
BA_ "GenSigSendType" SG_ 582 UI_solarElevationAngle 1;
BA_ "GenSigStartValue" SG_ 582 UI_solarElevationAngle 127;
BA_ "GenSigSendType" SG_ 824 UI_touchActive 1;
BA_ "GenSigSendType" SG_ 824 UI_audioActive 1;
BA_ "GenSigSendType" SG_ 824 UI_bluetoothActive 1;
BA_ "GenSigSendType" SG_ 824 UI_cellActive 1;
BA_ "GenSigSendType" SG_ 824 UI_displayReady 1;
BA_ "GenSigSendType" SG_ 824 UI_gpsActive 1;
BA_ "GenSigSendType" SG_ 824 UI_wifiConnected 1;
BA_ "GenSigSendType" SG_ 824 UI_systemActive 1;
BA_ "GenSigSendType" SG_ 824 UI_xmActive 1;
BA_ "GenSigSendType" SG_ 824 UI_displayOn 1;
BA_ "GenSigSNA" SG_ 824 UI_readyForDrive "0";
BA_ "GenSigSendType" SG_ 824 UI_readyForDrive 1;
BA_ "GenSigSendType" SG_ 824 UI_cellConnected 1;
BA_ "GenSigSendType" SG_ 824 UI_vpnActive 1;
BA_ "GenSigSendType" SG_ 824 UI_wifiActive 1;
BA_ "GenSigSendType" SG_ 824 UI_cameraActive 1;
BA_ "GenSigSendType" SG_ 824 UI_usbActive 1;
BA_ "GenSigSendType" SG_ 824 UI_screenshotActive 1;
BA_ "GenSigPersistent" SG_ 824 UI_monitorModemPower 1;
BA_ "GenSigSendType" SG_ 824 UI_monitorModemPower 1;
BA_ "GenSigSNA" SG_ 824 UI_factoryReset "0";
BA_ "GenSigSNA" SG_ 824 UI_cellNetworkTechnology "15";
BA_ "GenSigSendType" SG_ 824 UI_cellNetworkTechnology 1;
BA_ "GenSigSNA" SG_ 824 UI_tegraCoreTemperature "255";
BA_ "GenSigSendType" SG_ 824 UI_tegraCoreTemperature 1;
BA_ "GenSigSNA" SG_ 824 UI_tegraAmbientTemperature "255";
BA_ "GenSigSendType" SG_ 824 UI_tegraAmbientTemperature 1;
BA_ "GenSigSendType" SG_ 824 UI_googleWifiUsages 7;
BA_ "GenSigSendType" SG_ 824 UI_autopilotTrial 1;
BA_ "GenSigSNA" SG_ 824 UI_cellSignalBars "7";
BA_ "GenSigSendType" SG_ 824 UI_cellSignalBars 1;
BA_ "GenSigSNA" SG_ 824 UI_hardwareType "0";
BA_ "GenSigSendType" SG_ 824 UI_hardwareType 1;
BA_ "GenSigSendType" SG_ 824 UI_cellReceiverPower 1;
BA_ "GenSigSendType" SG_ 1070 UI_bluetoothRSSI 1;
BA_ "FieldType" SG_ 1070 UI_linkState "UI_linkState";
BA_ "GenSigSendType" SG_ 1070 UI_mobileAppStepCount 1;
BA_ "GenSigSendType" SG_ 1070 UI_userRequestSnapshot 1;
BA_ "FieldType" SG_ 1070 UI_autopilotPowerStateRequest "UI_autopilotPowerStateRequest";
BA_ "GenSigSendType" SG_ 1070 UI_autopilotPowerStateRequest 1;
BA_ "LogSignal" SG_ 1070 UI_autopilotPowerStateRequest "onChange";
BA_ "GenSigSendType" SG_ 1070 UI_touchDetected 1;
BA_ "GenSigSendType" SG_ 1070 UI_locatedAtHome 1;
BA_ "GenSigSendType" SG_ 1070 UI_locatedAtWork 1;
BA_ "GenSigSendType" SG_ 1070 UI_locatedAtFavorite 1;
BA_ "FieldType" SG_ 660 UI_suspensionLevelRequest "UI_suspensionLevelRequest";
BA_ "FieldType" SG_ 660 UI_adaptiveRideRequest "UI_adaptiveRideRequest";
BA_ "FieldType" SG_ 660 UI_suspensionLoweringRequest "UI_suspensionLoweringRequest";
BA_ "GenSigSNA" SG_ 660 UI_suspensionLoweringRequest "3";
BA_ "FieldType" SG_ 660 UI_geofenceLevelingRequest "UI_geofenceLevelingRequest";
BA_ "GenSigSNA" SG_ 660 UI_geofenceLevelingRequest "5";
BA_ "FieldType" SG_ 660 UI_jackModeToggleRequest "UI_jackModeToggleRequest";
BA_ "FieldType" SG_ 627 UI_driverSeatHeatReq "SEAT_heaterRequestLevel";
BA_ "LogSignal" SG_ 627 UI_driverSeatHeatReq "onChange";
BA_ "FieldType" SG_ 627 UI_passengerSeatHeatReq "SEAT_heaterRequestLevel";
BA_ "LogSignal" SG_ 627 UI_passengerSeatHeatReq "onChange";
BA_ "GenSigSNA" SG_ 898 VCSEATD_CPULoadTotal "255";
BA_ "GenSigSNA" SG_ 898 VCSEATD_CPULoad1msTask "255";
BA_ "GenSigSNA" SG_ 898 VCSEATD_CPULoad10msTask "255";
BA_ "GenSigSNA" SG_ 898 VCSEATD_CPULoad100msTask "255";
BA_ "GenSigSNA" SG_ 898 VCSEATD_CPULoad1000msTask "255";
BA_ "FieldType" SG_ 578 VCSEATD_lumbarLVState "LVPowerState";
BA_ "LogSignal" SG_ 578 VCSEATD_lumbarLVState "onChange";
BA_ "FieldType" SG_ 1373 VCSEATD_alertID "VCSEATD_alerts";
BA_ "FieldType" SG_ 1373 VCSEATD_alertType "alertState";
BA_ "FieldType" SG_ 1373 VCSEATD_a220_seatMotorState "SEAT_seatState";
BA_ "FieldType" SG_ 1373 VCSEATD_a220_seatSwitchBack "switchStatus";
BA_ "GenSigSNA" SG_ 1373 VCSEATD_a220_seatSwitchBack "3";
BA_ "FieldType" SG_ 1373 VCSEATD_a220_seatSwitchForward "switchStatus";
BA_ "GenSigSNA" SG_ 1373 VCSEATD_a220_seatSwitchForward "3";
BA_ "FieldType" SG_ 1373 VCSEATD_a221_seatMotorState "SEAT_seatState";
BA_ "FieldType" SG_ 1373 VCSEATD_a221_seatSwitchBack "switchStatus";
BA_ "GenSigSNA" SG_ 1373 VCSEATD_a221_seatSwitchBack "3";
BA_ "FieldType" SG_ 1373 VCSEATD_a221_seatSwitchForward "switchStatus";
BA_ "GenSigSNA" SG_ 1373 VCSEATD_a221_seatSwitchForward "3";
BA_ "FieldType" SG_ 1373 VCSEATD_a222_seatMotorState "SEAT_seatState";
BA_ "FieldType" SG_ 1373 VCSEATD_a222_seatSwitchBack "switchStatus";
BA_ "GenSigSNA" SG_ 1373 VCSEATD_a222_seatSwitchBack "3";
BA_ "FieldType" SG_ 1373 VCSEATD_a222_seatSwitchForward "switchStatus";
BA_ "GenSigSNA" SG_ 1373 VCSEATD_a222_seatSwitchForward "3";
BA_ "FieldType" SG_ 1373 VCSEATD_a223_seatMotorState "SEAT_seatState";
BA_ "FieldType" SG_ 1373 VCSEATD_a223_seatSwitchBack "switchStatus";
BA_ "GenSigSNA" SG_ 1373 VCSEATD_a223_seatSwitchBack "3";
BA_ "FieldType" SG_ 1373 VCSEATD_a223_seatSwitchForward "switchStatus";
BA_ "GenSigSNA" SG_ 1373 VCSEATD_a223_seatSwitchForward "3";
BA_ "FieldType" SG_ 1373 VCSEATD_a224_seatMotorState "SEAT_seatState";
BA_ "FieldType" SG_ 1373 VCSEATD_a224_seatSwitchBack "switchStatus";
BA_ "GenSigSNA" SG_ 1373 VCSEATD_a224_seatSwitchBack "3";
BA_ "FieldType" SG_ 1373 VCSEATD_a224_seatSwitchForward "switchStatus";
BA_ "GenSigSNA" SG_ 1373 VCSEATD_a224_seatSwitchForward "3";
BA_ "FieldType" SG_ 1373 VCSEATD_a225_seatMotorState "SEAT_seatState";
BA_ "FieldType" SG_ 1373 VCSEATD_a225_seatSwitchBack "switchStatus";
BA_ "GenSigSNA" SG_ 1373 VCSEATD_a225_seatSwitchBack "3";
BA_ "FieldType" SG_ 1373 VCSEATD_a225_seatSwitchForward "switchStatus";
BA_ "GenSigSNA" SG_ 1373 VCSEATD_a225_seatSwitchForward "3";
BA_ "FieldType" SG_ 1373 VCSEATD_a226_seatMotorState "SEAT_seatState";
BA_ "FieldType" SG_ 1373 VCSEATD_a226_seatSwitchBack "switchStatus";
BA_ "GenSigSNA" SG_ 1373 VCSEATD_a226_seatSwitchBack "3";
BA_ "FieldType" SG_ 1373 VCSEATD_a226_seatSwitchForward "switchStatus";
BA_ "GenSigSNA" SG_ 1373 VCSEATD_a226_seatSwitchForward "3";
BA_ "FieldType" SG_ 1373 VCSEATD_a227_seatMotorState "SEAT_seatState";
BA_ "FieldType" SG_ 1373 VCSEATD_a227_seatSwitchBack "switchStatus";
BA_ "GenSigSNA" SG_ 1373 VCSEATD_a227_seatSwitchBack "3";
BA_ "FieldType" SG_ 1373 VCSEATD_a227_seatSwitchForward "switchStatus";
BA_ "GenSigSNA" SG_ 1373 VCSEATD_a227_seatSwitchForward "3";
BA_ "FieldType" SG_ 1373 VCSEATD_a228_seatMotorState "SEAT_seatState";
BA_ "FieldType" SG_ 1373 VCSEATD_a228_seatSwitchBack "switchStatus";
BA_ "GenSigSNA" SG_ 1373 VCSEATD_a228_seatSwitchBack "3";
BA_ "FieldType" SG_ 1373 VCSEATD_a228_seatSwitchForward "switchStatus";
BA_ "GenSigSNA" SG_ 1373 VCSEATD_a228_seatSwitchForward "3";
BA_ "FieldType" SG_ 1373 VCSEATD_a229_seatMotorState "SEAT_seatState";
BA_ "FieldType" SG_ 1373 VCSEATD_a229_seatSwitchBack "switchStatus";
BA_ "GenSigSNA" SG_ 1373 VCSEATD_a229_seatSwitchBack "3";
BA_ "FieldType" SG_ 1373 VCSEATD_a229_seatSwitchForward "switchStatus";
BA_ "GenSigSNA" SG_ 1373 VCSEATD_a229_seatSwitchForward "3";
BA_ "FieldType" SG_ 1373 VCSEATD_a230_seatMotorState "SEAT_seatState";
BA_ "FieldType" SG_ 1373 VCSEATD_a230_seatSwitchBack "switchStatus";
BA_ "GenSigSNA" SG_ 1373 VCSEATD_a230_seatSwitchBack "3";
BA_ "FieldType" SG_ 1373 VCSEATD_a230_seatSwitchForward "switchStatus";
BA_ "GenSigSNA" SG_ 1373 VCSEATD_a230_seatSwitchForward "3";
BA_ "FieldType" SG_ 1373 VCSEATD_a231_seatMotorState "SEAT_seatState";
BA_ "FieldType" SG_ 1373 VCSEATD_a231_seatSwitchBack "switchStatus";
BA_ "GenSigSNA" SG_ 1373 VCSEATD_a231_seatSwitchBack "3";
BA_ "FieldType" SG_ 1373 VCSEATD_a231_seatSwitchForward "switchStatus";
BA_ "GenSigSNA" SG_ 1373 VCSEATD_a231_seatSwitchForward "3";
BA_ "FieldType" SG_ 1373 VCSEATD_a232_seatMotorState "SEAT_seatState";
BA_ "FieldType" SG_ 1373 VCSEATD_a232_seatSwitchBack "switchStatus";
BA_ "GenSigSNA" SG_ 1373 VCSEATD_a232_seatSwitchBack "3";
BA_ "FieldType" SG_ 1373 VCSEATD_a232_seatSwitchForward "switchStatus";
BA_ "GenSigSNA" SG_ 1373 VCSEATD_a232_seatSwitchForward "3";
BA_ "FieldType" SG_ 1373 VCSEATD_a233_seatMotorState "SEAT_seatState";
BA_ "FieldType" SG_ 1373 VCSEATD_a233_seatSwitchBack "switchStatus";
BA_ "GenSigSNA" SG_ 1373 VCSEATD_a233_seatSwitchBack "3";
BA_ "FieldType" SG_ 1373 VCSEATD_a233_seatSwitchForward "switchStatus";
BA_ "GenSigSNA" SG_ 1373 VCSEATD_a233_seatSwitchForward "3";
BA_ "FieldType" SG_ 1373 VCSEATD_a234_seatMotorState "SEAT_seatState";
BA_ "FieldType" SG_ 1373 VCSEATD_a234_seatSwitchBack "switchStatus";
BA_ "GenSigSNA" SG_ 1373 VCSEATD_a234_seatSwitchBack "3";
BA_ "FieldType" SG_ 1373 VCSEATD_a234_seatSwitchForward "switchStatus";
BA_ "GenSigSNA" SG_ 1373 VCSEATD_a234_seatSwitchForward "3";
BA_ "FieldType" SG_ 1373 VCSEATD_a235_seatMotorState "SEAT_seatState";
BA_ "FieldType" SG_ 1373 VCSEATD_a235_seatSwitchBack "switchStatus";
BA_ "GenSigSNA" SG_ 1373 VCSEATD_a235_seatSwitchBack "3";
BA_ "FieldType" SG_ 1373 VCSEATD_a235_seatSwitchForward "switchStatus";
BA_ "GenSigSNA" SG_ 1373 VCSEATD_a235_seatSwitchForward "3";
BA_ "FieldType" SG_ 1373 VCSEATD_a236_lumbarAState "SEAT_seatState";
BA_ "FieldType" SG_ 1373 VCSEATD_a236_lumbarBState "SEAT_seatState";
BA_ "FieldType" SG_ 1373 VCSEATD_a237_lumbarAState "SEAT_seatState";
BA_ "FieldType" SG_ 1373 VCSEATD_a237_lumbarBState "SEAT_seatState";
BA_ "FieldType" SG_ 1373 VCSEATD_a238_lumbarAState "SEAT_seatState";
BA_ "FieldType" SG_ 1373 VCSEATD_a238_lumbarBState "SEAT_seatState";
BA_ "FieldType" SG_ 1373 VCSEATD_a251_seatMotorState "SEAT_seatState";
BA_ "FieldType" SG_ 1373 VCSEATD_a251_seatSwitchBack "switchStatus";
BA_ "GenSigSNA" SG_ 1373 VCSEATD_a251_seatSwitchBack "3";
BA_ "FieldType" SG_ 1373 VCSEATD_a251_seatSwitchForward "switchStatus";
BA_ "GenSigSNA" SG_ 1373 VCSEATD_a251_seatSwitchForward "3";
BA_ "FieldType" SG_ 1373 VCSEATD_a252_seatMotorState "SEAT_seatState";
BA_ "FieldType" SG_ 1373 VCSEATD_a252_seatSwitchBack "switchStatus";
BA_ "GenSigSNA" SG_ 1373 VCSEATD_a252_seatSwitchBack "3";
BA_ "FieldType" SG_ 1373 VCSEATD_a252_seatSwitchForward "switchStatus";
BA_ "GenSigSNA" SG_ 1373 VCSEATD_a252_seatSwitchForward "3";
BA_ "FieldType" SG_ 1373 VCSEATD_a253_seatMotorState "SEAT_seatState";
BA_ "FieldType" SG_ 1373 VCSEATD_a253_seatSwitchBack "switchStatus";
BA_ "GenSigSNA" SG_ 1373 VCSEATD_a253_seatSwitchBack "3";
BA_ "FieldType" SG_ 1373 VCSEATD_a253_seatSwitchForward "switchStatus";
BA_ "GenSigSNA" SG_ 1373 VCSEATD_a253_seatSwitchForward "3";
BA_ "FieldType" SG_ 1373 VCSEATD_a254_seatMotorState "SEAT_seatState";
BA_ "FieldType" SG_ 1373 VCSEATD_a254_seatSwitchBack "switchStatus";
BA_ "GenSigSNA" SG_ 1373 VCSEATD_a254_seatSwitchBack "3";
BA_ "FieldType" SG_ 1373 VCSEATD_a254_seatSwitchForward "switchStatus";
BA_ "GenSigSNA" SG_ 1373 VCSEATD_a254_seatSwitchForward "3";
BA_ "FieldType" SG_ 1373 VCSEATD_a263_seatMotorState "SEAT_seatState";
BA_ "FieldType" SG_ 1373 VCSEATD_a264_seatMotorState "SEAT_seatState";
BA_ "FieldType" SG_ 1373 VCSEATD_a265_seatMotorState "SEAT_seatState";
BA_ "FieldType" SG_ 1373 VCSEATD_a266_seatMotorState "SEAT_seatState";
BA_ "FieldType" SG_ 1373 VCSEATD_a267_seatMotorState "SEAT_seatState";
BA_ "FieldType" SG_ 1373 VCSEATD_a268_seatMotorState "SEAT_seatState";
BA_ "FieldType" SG_ 1373 VCSEATD_a269_seatMotorState "SEAT_seatState";
BA_ "FieldType" SG_ 1373 VCSEATD_a270_seatMotorState "SEAT_seatState";
BA_ "GenSigStartValue" SG_ 1373 VCSEATD_a380_ocsTempRaw 90;
BA_ "GenSigStartValue" SG_ 1373 VCSEATD_a381_ocsTempRaw 90;
BA_ "GenSigStartValue" SG_ 1373 VCSEATD_a382_ocsTempRaw 90;
BA_ "GenSigStartValue" SG_ 1373 VCSEATD_a386_ocsTempRaw 90;
BA_ "GenSigStartValue" SG_ 1373 VCSEATD_a387_ocsTempRaw 90;
BA_ "GenSigStartValue" SG_ 1373 VCSEATD_a388_ocsTempRaw 90;
BA_ "GenSigStartValue" SG_ 1373 VCSEATD_a389_ocsTempRaw 16852;
BA_ "GenSigStartValue" SG_ 1373 VCSEATD_a397_ocsTempCalib 16852;
BA_ "GenSigStartValue" SG_ 1373 VCSEATD_a401_ocsCushionRaw -23000;
BA_ "GenSigStartValue" SG_ 1373 VCSEATD_a401_ocsSpareRaw -23000;
BA_ "GenSigStartValue" SG_ 1373 VCSEATD_a401_ocsTempRaw 80;
BA_ "FieldType" SG_ 1373 VCSEATD_a401_occupancySwitch "switchStatus";
BA_ "GenSigSNA" SG_ 1373 VCSEATD_a401_occupancySwitch "3";
BA_ "GenSigSNA" SG_ 1373 VCSEATD_a415_occupancyTimeMins "65535";
BA_ "FieldType" SG_ 892 VCSEATD_matrixIndex "VCSEATD_AlertMatrixIndex";
BA_ "FieldType" SG_ 866 VCSEATD_crashDetectedType "crashDetectedType";
BA_ "LogSignal" SG_ 866 VCSEATD_crashDetectedType "onChange";
BA_ "FieldType" SG_ 866 VCSEATD_crashState "crashState";
BA_ "LogSignal" SG_ 866 VCSEATD_crashState "onChange";
BA_ "LogSignal" SG_ 866 VCSEATD_crashNumSwitchesDisabled "onChange";
BA_ "LogSignal" SG_ 866 VCSEATD_crashUnlockOverrideSet "onChange";
BA_ "FieldType" SG_ 770 VCSEATD_infoIndex "bcInfoIndex";
BA_ "FieldType" SG_ 770 VCSEATD_infoBuildType "buildType";
BA_ "LogSignal" SG_ 770 VCSEATD_infoBuildConfigId "periodic ONE_DAY Any";
BA_ "FieldType" SG_ 770 VCSEATD_infoAssemblyId "infoAssemblyID";
BA_ "GenSigSNA" SG_ 770 VCSEATD_infoAssemblyId "255";
BA_ "GenSigStartValue" SG_ 770 VCSEATD_infoAppCrc 4294967295;
BA_ "GenSigStartValue" SG_ 770 VCSEATD_infoPlatformType 255;
BA_ "FieldType" SG_ 1841 VCSEATD_ocsSensorStatusIndex "SEAT_ocsSensorStatusIndex";
BA_ "LogSignal" SG_ 1841 VCSEATD_tosRawCushion "periodic ONE_MINUTE Any";
BA_ "LogSignal" SG_ 1841 VCSEATD_tosRawSpare "periodic ONE_MINUTE Any";
BA_ "GenSigStartValue" SG_ 1841 VCSEATD_ocsTemperature 16852;
BA_ "LogSignal" SG_ 1841 VCSEATD_ocsTemperature "periodic ONE_MINUTE Any";
BA_ "LogSignal" SG_ 1841 VCSEATD_ocsHumidity "periodic ONE_MINUTE Any";
BA_ "LogSignal" SG_ 1841 VCSEATD_tosFilteredCushion "periodic ONE_MINUTE Any";
BA_ "LogSignal" SG_ 1841 VCSEATD_tosFilteredSpare "periodic ONE_MINUTE Any";
BA_ "LogSignal" SG_ 1841 VCSEATD_tosDeltaDisconnected "periodic ONE_MINUTE Any";
BA_ "LogSignal" SG_ 1841 VCSEATD_tosDeltaOffset "onChange";
BA_ "LogSignal" SG_ 1841 VCSEATD_tosDeltaEmpty "periodic ONE_MINUTE Any";
BA_ "LogSignal" SG_ 1841 VCSEATD_tosRelative "periodic ONE_MINUTE Any";
BA_ "LogSignal" SG_ 1841 VCSEATD_classificationLocked "onChange";
BA_ "FieldType" SG_ 1841 VCSEATD_classificationRaw "SEAT_occupantClassification";
BA_ "GenSigSNA" SG_ 1841 VCSEATD_classificationRaw "7";
BA_ "LogSignal" SG_ 1841 VCSEATD_classificationRaw "onChange";
BA_ "FieldType" SG_ 1843 VCSEATD_ocsSensorStatus2Index "SEAT_ocsSensorStatus2Index";
BA_ "LogSignal" SG_ 1843 VCSEATD_ocsCalibCushionEmpty "periodic ONE_DAY Any";
BA_ "LogSignal" SG_ 1843 VCSEATD_ocsCalibSpareEmpty "periodic ONE_DAY Any";
BA_ "GenSigStartValue" SG_ 1843 VCSEATD_ocsCalibTempEmpty 16852;
BA_ "LogSignal" SG_ 1843 VCSEATD_ocsCalibTempEmpty "periodic ONE_DAY Any";
BA_ "LogSignal" SG_ 1843 VCSEATD_ocsFieldCalibrated "periodic ONE_DAY Any";
BA_ "LogSignal" SG_ 1843 VCSEATD_ocsCalibHumidityEmpty "periodic ONE_DAY Any";
BA_ "LogSignal" SG_ 1843 VCSEATD_ocsCalibCushionDisc "periodic ONE_DAY Any";
BA_ "LogSignal" SG_ 1843 VCSEATD_ocsCalibSpareDisc "periodic ONE_DAY Any";
BA_ "GenSigStartValue" SG_ 1843 VCSEATD_ocsCalibTempDisc 16852;
BA_ "LogSignal" SG_ 1843 VCSEATD_ocsCalibTempDisc "periodic ONE_DAY Any";
BA_ "LogSignal" SG_ 1843 VCSEATD_ocsCalibHumidityDisc "periodic ONE_DAY Any";
VAL_ 555 TAS_rawHeightFL 255 "SNA" ;
VAL_ 555 TAS_rawHeightFR 255 "SNA" ;
VAL_ 555 TAS_rawHeightRL 255 "SNA" ;
VAL_ 555 TAS_rawHeightRR 255 "SNA" ;
VAL_ 1610 TAS_debugStates 1 "TAS_DEBUG_STATES_LAUNCH_MODE" 0 "TAS_DEBUG_STATES_NONE" ;
VAL_ 1610 TAS_launchModeState 4 "TAS_LAUNCH_MODE_STATE_RAISE_SUSPENSION" 3 "TAS_LAUNCH_MODE_STATE_READY" 2 "TAS_LAUNCH_MODE_STATE_LOWER_SUSPENSION" 1 "TAS_LAUNCH_MODE_STATE_IDLE" 0 "TAS_LAUNCH_MODE_STATE_BLOCKED" ;
VAL_ 1307 TAS_infoIndex 255 "BC_INFO_END" 33 "BC_INFO_SUBCOMPONENT6" 32 "BC_INFO_SUBCOMPONENT5" 31 "BC_INFO_SUBCOMPONENT4" 24 "BC_INFO_SUBCOMPONENT3" 23 "BC_INFO_SUBCOMPONENT2" 20 "BC_INFO_UDS_PROTOCOL_BOOTCRC" 19 "BC_INFO_VERSION_DEPRECATED" 18 "BC_INFO_BOOTLOADER_GITHASH" 17 "BC_INFO_APP_GITHASH" 16 "BC_INFO_SUBCOMPONENT1" 15 "BC_INFO_BOOTLOADER_CRC" 14 "BC_INFO_BOOTLOADER_SVN" 13 "BC_INFO_APP_CRC" 11 "BC_INFO_PCBAID_ASSYID_USAGEID" 10 "BC_INFO_BUILD_HWID_COMPONENTID" 9 "BC_INFO_DEPRECATED_9" 8 "BC_INFO_DEPRECATED_8" 7 "BC_INFO_DEPRECATED_7" 6 "BC_INFO_DEPRECATED_6" 5 "BC_INFO_DEPRECATED_5" 4 "BC_INFO_DEPRECATED_4" 3 "BC_INFO_DEPRECATED_3" 2 "BC_INFO_DEPRECATED_2" 1 "BC_INFO_DEPRECATED_1" 0 "BC_INFO_DEPRECATED_0" ;
VAL_ 1307 TAS_infoBuildType 4 "INFO_MFG_BUILD" 3 "INFO_TRACEABLE_CI_BUILD" 2 "INFO_LOCAL_BUILD" 1 "INFO_PLATFORM_BUILD" 0 "INFO_UNKNOWN_BUILD" ;
VAL_ 1307 TAS_infoAssemblyId 255 "ASSEMBLY_SNA" 1 "ASSEMBLY1" ;
VAL_ 1307 TAS_infoMajorVersion 255 "VERSION_SNA" 254 "VERSION_LOCAL_BUILD" ;
VAL_ 1307 TAS_infoBranchOrigin 255 "VERSION_SNA" 254 "VERSION_LOCAL_BUILD" ;
VAL_ 1307 TAS_infoMaturity 255 "VERSION_SNA" 254 "VERSION_LOCAL_BUILD" ;
VAL_ 1307 TAS_infoHardwareRevision 255 "VERSION_SNA" 254 "VERSION_LOCAL_BUILD" ;
VAL_ 539 TAS_levelingState 12 "LEVELING_STATE_EMPTY_RESERVOIR" 11 "LEVELING_STATE_LOWER_SPRING" 10 "LEVELING_STATE_FILL_SPRING_RESERVOIR_FROM_COMPRESSOR" 9 "LEVELING_STATE_FILL_SPRING_FROM_RESERVOIR" 8 "LEVELING_STATE_FILL_SPRING_FROM_BOOST" 7 "LEVELING_STATE_FILL_SPRING_FROM_COMPRESSOR" 6 "LEVELING_STATE_FILL_RESERVOIR_FROM_COMPRESSOR" 5 "LEVELING_STATE_COMPRESSOR_PREFILL_GALLERY" 4 "LEVELING_STATE_COMPRESSOR_RAMPUP" 3 "LEVELING_STATE_EXHAUST_GALLERY" 2 "LEVELING_STATE_MANUAL_SPRING_CONTROL" 1 "LEVELING_STATE_READ_P_RESERVOIR" 0 "LEVELING_STATE_IDLE" ;
VAL_ 539 TAS_levelingItem 7 "TAS_LEVELING_ITEM_ALL" 6 "TAS_LEVELING_ITEM_REAR_AXLE" 5 "TAS_LEVELING_ITEM_FRONT_AXLE" 4 "TAS_LEVELING_ITEM_RR" 3 "TAS_LEVELING_ITEM_RL" 2 "TAS_LEVELING_ITEM_FR" 1 "TAS_LEVELING_ITEM_FL" 0 "TAS_LEVELING_ITEM_NONE" ;
VAL_ 539 TAS_pressureGallery 255 "SNA" ;
VAL_ 539 TAS_pressureReservoir 255 "SNA" ;
VAL_ 539 TAS_runMode 6 "RUN_MODE_LOW_POWER" 5 "RUN_MODE_NORMAL" 4 "RUN_MODE_DAN" 3 "RUN_MODE_ASSEMBLY" 2 "RUN_MODE_SERVICE" 1 "RUN_MODE_SYSTEM_CHECK" 0 "RUN_MODE_INIT" ;
VAL_ 539 TAS_filterMode 7 "MODE_STOPPING" 6 "MODE_DRIVE" 5 "MODE_LOADING" 4 "MODE_READY" 3 "MODE_TEST" 2 "MODE_CALIBRATE" 1 "MODE_INIT" 0 "MODE_NONE" ;
VAL_ 539 TAS_limpHomeMode 4 "LIMP_HOME_MODE_40" 3 "LIMP_HOME_MODE_30" 2 "LIMP_HOME_MODE_20" 1 "LIMP_HOME_MODE_10" 0 "LIMP_HOME_MODE_0" ;
VAL_ 539 TAS_targetLevel 4 "TAS_VERY_LOW" 3 "TAS_LOW" 2 "TAS_STANDARD" 1 "TAS_HIGH" 0 "TAS_VERY_HIGH" ;
VAL_ 539 TAS_currentLevel 4 "TAS_VERY_LOW" 3 "TAS_LOW" 2 "TAS_STANDARD" 1 "TAS_HIGH" 0 "TAS_VERY_HIGH" ;
VAL_ 409 TAS_adaptiveActivityFL_C 31 "SNA" ;
VAL_ 409 TAS_adaptiveActivityFL_R 31 "SNA" ;
VAL_ 409 TAS_adaptiveActivityFR_C 31 "SNA" ;
VAL_ 409 TAS_adaptiveActivityFR_R 31 "SNA" ;
VAL_ 409 TAS_adaptiveActivityRL_C 31 "SNA" ;
VAL_ 409 TAS_adaptiveActivityRL_R 31 "SNA" ;
VAL_ 409 TAS_adaptiveActivityRR_C 31 "SNA" ;
VAL_ 409 TAS_adaptiveActivityRR_R 31 "SNA" ;
VAL_ 409 TAS_uiHeightFL 63 "SNA" ;
VAL_ 409 TAS_uiHeightFR 63 "SNA" ;
VAL_ 409 TAS_uiHeightRL 63 "SNA" ;
VAL_ 409 TAS_uiHeightRR 63 "SNA" ;
VAL_ 410 TAS_bodyAccelFL 255 "SNA" ;
VAL_ 410 TAS_bodyAccelFR 255 "SNA" ;
VAL_ 410 TAS_bodyAccelRL 255 "SNA" ;
VAL_ 410 TAS_bodyAccelRR 255 "SNA" ;
VAL_ 525 TAS_adaptiveRideModeOverride 3 "TAS_ADAPTIVE_RIDE_MODE_SNA" 2 "TAS_ADAPTIVE_RIDE_MODE_SPORT" 1 "TAS_ADAPTIVE_RIDE_MODE_AUTO" 0 "TAS_ADAPTIVE_RIDE_MODE_COMFORT" ;
VAL_ 879 TPMS_learningStatus 3 "PASSED" 2 "STOPPED" 1 "ONGOING" 0 "FAILED" ;
VAL_ 879 TPMS_localisationStatus 3 "PASSED" 2 "STOPPED" 1 "ONGOING" 0 "FAILED" ;
VAL_ 1519 TPMS_infoIdx 255 "INFO_END" 20 "INFO_UDS_PROTOCOL_BOOTCRC" 19 "INFO_VERSION_DEPRECATED" 18 "INFO_BOOTLOADER_GITHASH" 17 "INFO_APP_GITHASH" 16 "INFO_SUBCOMPONENT" 15 "INFO_BOOTLOADER_CRC" 14 "INFO_BOOTLOADER_SVN" 13 "INFO_APP_CRC" 11 "INFO_PCBAID_ASSYID_USAGEID" 10 "INFO_BUILD_HWID_COMPONENTID" 9 "INFO_DEPRECATED_9" 8 "INFO_DEPRECATED_8" 7 "INFO_DEPRECATED_7" 6 "INFO_DEPRECATED_6" 5 "INFO_DEPRECATED_5" 4 "INFO_DEPRECATED_4" 3 "INFO_DEPRECATED_3" 2 "INFO_DEPRECATED_2" 1 "INFO_DEPRECATED_1" 0 "INFO_DEPRECATED_0" ;
VAL_ 882 TPMS_sensorIDIndex 3 "TPMS_sensorIDRL" 2 "TPMS_sensorIDFR" 1 "TPMS_sensorIDRR" 0 "TPMS_sensorIDFL" ;
VAL_ 1006 UI_autopilotControlIndex 7 "AUTOPILOT_CONTROL_7" 6 "AUTOPILOT_CONTROL_6" 5 "AUTOPILOT_CONTROL_5" 4 "AUTOPILOT_CONTROL_4" 3 "AUTOPILOT_CONTROL_3" 2 "AUTOPILOT_CONTROL_2" 1 "AUTOPILOT_CONTROL_1" 0 "AUTOPILOT_CONTROL_0" ;
VAL_ 1006 UI_hovEnabled 1 "HOV_ON" 0 "HOV_OFF" ;
VAL_ 1006 UI_donDisableAutoWiperDuration 6 "DON_DISABLE_AUTO_WIPER_DURATION_OFF" 5 "DON_DISABLE_AUTO_WIPER_DURATION_120_S" 4 "DON_DISABLE_AUTO_WIPER_DURATION_60_S" 3 "DON_DISABLE_AUTO_WIPER_DURATION_30_S" 2 "DON_DISABLE_AUTO_WIPER_DURATION_15_S" 1 "DON_DISABLE_AUTO_WIPER_DURATION_5_S" 0 "DON_DISABLE_AUTO_WIPER_DURATION_DEFAULT" ;
VAL_ 1006 UI_donDisableOnAutoWiperSpeed 15 "DAS_WIPER_SPEED_INVALID" 14 "DAS_WIPER_SPEED_14" 13 "DAS_WIPER_SPEED_13" 12 "DAS_WIPER_SPEED_12" 11 "DAS_WIPER_SPEED_11" 10 "DAS_WIPER_SPEED_10" 9 "DAS_WIPER_SPEED_9" 8 "DAS_WIPER_SPEED_8" 7 "DAS_WIPER_SPEED_7" 6 "DAS_WIPER_SPEED_6" 5 "DAS_WIPER_SPEED_5" 4 "DAS_WIPER_SPEED_4" 3 "DAS_WIPER_SPEED_3" 2 "DAS_WIPER_SPEED_2" 1 "DAS_WIPER_SPEED_1" 0 "DAS_WIPER_SPEED_OFF" ;
VAL_ 1006 UI_blindspotMinSpeed 10 "BLINDSPOT_MIN_SPEED_OFF" 9 "BLINDSPOT_MIN_SPEED_45_KPH" 8 "BLINDSPOT_MIN_SPEED_40_KPH" 7 "BLINDSPOT_MIN_SPEED_35_KPH" 6 "BLINDSPOT_MIN_SPEED_30_KPH" 5 "BLINDSPOT_MIN_SPEED_25_KPH" 4 "BLINDSPOT_MIN_SPEED_20_KPH" 3 "BLINDSPOT_MIN_SPEED_15_KPH" 2 "BLINDSPOT_MIN_SPEED_10_KPH" 1 "BLINDSPOT_MIN_SPEED_5_KPH" 0 "BLINDSPOT_MIN_SPEED_DEFAULT" ;
VAL_ 1006 UI_blindspotDistance 5 "BLINDSPOT_DISTANCE_OFF" 4 "BLINDSPOT_DISTANCE_4_M" 3 "BLINDSPOT_DISTANCE_2_M" 2 "BLINDSPOT_DISTANCE_1_M" 1 "BLINDSPOT_DISTANCE_0P5_M" 0 "BLINDSPOT_DISTANCE_DEFAULT" ;
VAL_ 1006 UI_blindspotTTC 7 "BLINDSPOT_TTC_OFF" 6 "BLINDSPOT_TTC_5_S" 5 "BLINDSPOT_TTC_4_S" 4 "BLINDSPOT_TTC_3_S" 3 "BLINDSPOT_TTC_2_S" 2 "BLINDSPOT_TTC_1_S" 1 "BLINDSPOT_TTC_0P5_S" 0 "BLINDSPOT_TTC_DEFAULT" ;
VAL_ 1006 UI_donStopEndOfRampBuffer 4 "DON_STOP_END_OF_RAMP_BUFFER_OFF" 3 "DON_STOP_END_OF_RAMP_BUFFER_45_M" 2 "DON_STOP_END_OF_RAMP_BUFFER_30_M" 1 "DON_STOP_END_OF_RAMP_BUFFER_15_M" 0 "DON_STOP_END_OF_RAMP_BUFFER_DEFAULT" ;
VAL_ 1006 UI_donDisableCutin 1 "DON_DISABLE_CUTIN_ON" 0 "DON_DISABLE_CUTIN_OFF" ;
VAL_ 1006 UI_donMinGoreWidthForAbortMap 11 "DON_MIN_GORE_WIDTH_FOR_ABORT_5_M" 10 "DON_MIN_GORE_WIDTH_FOR_ABORT_4P5_M" 9 "DON_MIN_GORE_WIDTH_FOR_ABORT_4_M" 8 "DON_MIN_GORE_WIDTH_FOR_ABORT_3P5_M" 7 "DON_MIN_GORE_WIDTH_FOR_ABORT_3_M" 6 "DON_MIN_GORE_WIDTH_FOR_ABORT_2P5_M" 5 "DON_MIN_GORE_WIDTH_FOR_ABORT_2_M" 4 "DON_MIN_GORE_WIDTH_FOR_ABORT_1P5_M" 3 "DON_MIN_GORE_WIDTH_FOR_ABORT_1_M" 2 "DON_MIN_GORE_WIDTH_FOR_ABORT_0P5_M" 1 "DON_MIN_GORE_WIDTH_FOR_ABORT_0_M" 0 "DON_MIN_GORE_WIDTH_FOR_ABORT_DEFAULT" ;
VAL_ 1006 UI_donAlcProgGoreAbortThres 9 "DON_ALC_PROGRESS_GORE_ABORT_THRESHOLD_0P40" 8 "DON_ALC_PROGRESS_GORE_ABORT_THRESHOLD_0P35" 7 "DON_ALC_PROGRESS_GORE_ABORT_THRESHOLD_0P30" 6 "DON_ALC_PROGRESS_GORE_ABORT_THRESHOLD_0P25" 5 "DON_ALC_PROGRESS_GORE_ABORT_THRESHOLD_0P20" 4 "DON_ALC_PROGRESS_GORE_ABORT_THRESHOLD_0P15" 3 "DON_ALC_PROGRESS_GORE_ABORT_THRESHOLD_0P10" 2 "DON_ALC_PROGRESS_GORE_ABORT_THRESHOLD_0P05" 1 "DON_ALC_PROGRESS_GORE_ABORT_THRESHOLD_0P00" 0 "DON_ALC_PROGRESS_GORE_ABORT_THRESHOLD_DEFAULT" ;
VAL_ 1006 UI_donMinGoreWidthForAbortNotMap 11 "DON_MIN_GORE_WIDTH_FOR_ABORT_5_M" 10 "DON_MIN_GORE_WIDTH_FOR_ABORT_4P5_M" 9 "DON_MIN_GORE_WIDTH_FOR_ABORT_4_M" 8 "DON_MIN_GORE_WIDTH_FOR_ABORT_3P5_M" 7 "DON_MIN_GORE_WIDTH_FOR_ABORT_3_M" 6 "DON_MIN_GORE_WIDTH_FOR_ABORT_2P5_M" 5 "DON_MIN_GORE_WIDTH_FOR_ABORT_2_M" 4 "DON_MIN_GORE_WIDTH_FOR_ABORT_1P5_M" 3 "DON_MIN_GORE_WIDTH_FOR_ABORT_1_M" 2 "DON_MIN_GORE_WIDTH_FOR_ABORT_0P5_M" 1 "DON_MIN_GORE_WIDTH_FOR_ABORT_0_M" 0 "DON_MIN_GORE_WIDTH_FOR_ABORT_DEFAULT" ;
VAL_ 1006 UI_homelinkNearby 1 "HOMELINK_NEARBY" 0 "HOMELINK_NOT_NEARBY" ;
VAL_ 1006 UI_apmv3Branch 5 "DEMO" 4 "EAP" 3 "STAGE2" 2 "DEV" 1 "STAGE" 0 "LIVE" ;
VAL_ 1080 UI_anonDebugFlag1 1 "ON" 0 "OFF" ;
VAL_ 1080 UI_anonDebugFlag2 1 "ON" 0 "OFF" ;
VAL_ 1080 UI_anonDebugFlag3 1 "ON" 0 "OFF" ;
VAL_ 1080 UI_anonDebugFlag4 1 "ON" 0 "OFF" ;
VAL_ 1000 UI_autopilotControlRequest 1 "NEXT_GEN_CTRL" 0 "LEGACY_LAT_CTRL" ;
VAL_ 1000 UI_curvSpeedAdaptDisable 1 "CSA_OFF" 0 "CSA_ON" ;
VAL_ 1000 UI_lssLkaEnabled 1 "LKA_ON" 0 "LKA_OFF" ;
VAL_ 1000 UI_lssLdwEnabled 1 "LDW_ON" 0 "LDW_OFF" ;
VAL_ 1000 UI_exceptionListEnable 1 "EXCEPTION_LIST_ON" 0 "EXCEPTION_LIST_OFF" ;
VAL_ 1000 UI_roadCheckDisable 1 "RC_OFF" 0 "RC_ON" ;
VAL_ 1000 UI_driveOnMapsEnable 1 "DOM_ON" 0 "DOM_OFF" ;
VAL_ 1000 UI_handsOnRequirementDisable 1 "HANDS_ON_REQ_OFF" 0 "HANDS_ON_REQ_ON" ;
VAL_ 1000 UI_fuseLanesDisable 1 "FUSE_LANES_OFF" 0 "FUSE_LANES_ON" ;
VAL_ 1000 UI_fuseHPPDisable 1 "FUSE_HPP_OFF" 0 "FUSE_HPP_ON" ;
VAL_ 1000 UI_fuseVehiclesDisable 1 "FUSE_VEH_OFF" 0 "FUSE_VEH_ON" ;
VAL_ 1000 UI_visionSpeedType 3 "VISION_SPEED_OPTIMIZED" 2 "VISION_SPEED_TWO_SECOND" 1 "VISION_SPEED_ONE_SECOND" 0 "VISION_SPEED_DISABLED" ;
VAL_ 1000 UI_curvatureDatabaseOnly 1 "ON" 0 "OFF" ;
VAL_ 1000 UI_lssElkEnabled 1 "ELK_ON" 0 "ELK_OFF" ;
VAL_ 1000 UI_summonExitType 3 "SNA" 2 "TURN_LEFT" 1 "TURN_RIGHT" 0 "STRAIGHT" ;
VAL_ 1000 UI_summonEntryType 3 "SNA" 2 "TURN_LEFT" 1 "TURN_RIGHT" 0 "STRAIGHT" ;
VAL_ 1000 UI_selfParkRequest 15 "SNA" 12 "SMART_SUMMON_NO_OP" 11 "SMART_SUMMON" 10 "AUTO_SUMMON_PRIMED" 9 "AUTO_SUMMON_CANCEL" 8 "AUTO_SUMMON_REVERSE" 7 "AUTO_SUMMON_FORWARD" 6 "RESUME" 5 "PAUSE" 4 "PRIME" 3 "ABORT" 2 "SELF_PARK_REVERSE" 1 "SELF_PARK_FORWARD" 0 "NONE" ;
VAL_ 1000 UI_summonReverseDist 63 "SNA" ;
VAL_ 1000 UI_drivingSide 2 "DRIVING_SIDE_UNKNOWN" 1 "DRIVING_SIDE_RIGHT" 0 "DRIVING_SIDE_LEFT" ;
VAL_ 1000 UI_followNavRouteEnable 1 "NAV_ROUTE_ON" 0 "NAV_ROUTE_OFF" ;
VAL_ 1000 UI_ulcSpeedConfig 3 "SPEED_BASED_ULC_MAD_MAX" 2 "SPEED_BASED_ULC_AVERAGE" 1 "SPEED_BASED_ULC_MILD" 0 "SPEED_BASED_ULC_DISABLED" ;
VAL_ 1000 UI_ulcBlindSpotConfig 2 "MAD_MAX" 1 "AGGRESSIVE" 0 "STANDARD" ;
VAL_ 1000 UI_smartSummonType 2 "SMART_AUTOPARK" 1 "FIND_ME" 0 "PIN_DROP" ;
VAL_ 1000 UI_source3D 2 "XYZ_PREDICTION" 1 "Z_FROM_PATH_PREDICTION" 0 "Z_FROM_MAP" ;
VAL_ 968 UI_mapSpeedLimitDependency 7 "SNA" 6 "LANE" 5 "SEASON" 4 "TIME" 3 "SNOW" 2 "RAIN" 1 "SCHOOL" 0 "NONE" ;
VAL_ 968 UI_roadClass 6 "CLASS_6_MINOR" 5 "CLASS_5" 4 "CLASS_4" 3 "CLASS_3" 2 "CLASS_2" 1 "CLASS_1_MAJOR" 0 "UNKNOWN_INVALID_SNA" ;
VAL_ 968 UI_mapSpeedUnits 1 "KPH" 0 "MPH" ;
VAL_ 968 UI_mapSpeedLimit 31 "SNA" 30 "UNLIMITED" 29 "LESS_OR_EQ_160" 28 "LESS_OR_EQ_150" 27 "LESS_OR_EQ_140" 26 "LESS_OR_EQ_130" 25 "LESS_OR_EQ_120" 24 "LESS_OR_EQ_115" 23 "LESS_OR_EQ_110" 22 "LESS_OR_EQ_105" 21 "LESS_OR_EQ_100" 20 "LESS_OR_EQ_95" 19 "LESS_OR_EQ_90" 18 "LESS_OR_EQ_85" 17 "LESS_OR_EQ_80" 16 "LESS_OR_EQ_75" 15 "LESS_OR_EQ_70" 14 "LESS_OR_EQ_65" 13 "LESS_OR_EQ_60" 12 "LESS_OR_EQ_55" 11 "LESS_OR_EQ_50" 10 "LESS_OR_EQ_45" 9 "LESS_OR_EQ_40" 8 "LESS_OR_EQ_35" 7 "LESS_OR_EQ_30" 6 "LESS_OR_EQ_25" 5 "LESS_OR_EQ_20" 4 "LESS_OR_EQ_15" 3 "LESS_OR_EQ_10" 2 "LESS_OR_EQ_7" 1 "LESS_OR_EQ_5" 0 "UNKNOWN" ;
VAL_ 968 UI_mapSpeedLimitType 7 "UNKNOWN_SNA" 4 "BUMPS" 3 "DEPENDENT" 2 "ADVISORY" 1 "REGULAR" ;
VAL_ 968 UI_countryCode 1023 "SNA" 0 "UNKNOWN" ;
VAL_ 968 UI_nextBranchDist 31 "SNA" ;
VAL_ 568 UI_roadSign 5 "ROAD_SIGN_SPLINE_ID_FULL" 4 "ROAD_SIGN_SPEED_SPLINE" 3 "ROAD_SIGN_SPEED_LIMIT" 2 "ROAD_SIGN_TRAFFIC_LIGHT" 1 "ROAD_SIGN_STOP_SIGN" 0 "ROAD_SIGN_NONE" ;
VAL_ 568 UI_splineLocConfidence 0 "SNA" ;
VAL_ 568 UI_stopSignStopLineDist 1023 "SNA" ;
VAL_ 568 UI_stopSignStopLineConf 0 "SNA" ;
VAL_ 568 UI_trafficLightStopLineDist 1023 "SNA" ;
VAL_ 568 UI_trafficLightStopLineConf 0 "SNA" ;
VAL_ 568 UI_baseMapSpeedLimitMPS 255 "SNA" ;
VAL_ 568 UI_bottomQrtlFleetSpeedMPS 255 "SNA" ;
VAL_ 568 UI_topQrtlFleetSpeedMPS 255 "SNA" ;
VAL_ 568 UI_meanFleetSplineSpeedMPS 255 "SNA" ;
VAL_ 568 UI_medianFleetSpeedMPS 255 "SNA" ;
VAL_ 568 UI_meanFleetSplineAccelMPS2 255 "SNA" ;
VAL_ 568 UI_rampType 4 "INTERCHANGE_EXIT" 3 "INTERCHANGE_ENTRANCE" 2 "EXIT" 1 "ENTRANCE" 0 "NONE_SNA" ;
VAL_ 568 UI_valhallaRamp 2 "ON_RAMP" 1 "NOT_ON_RAMP" 0 "SNA" ;
VAL_ 568 UI_currSplineIdFull 0 "SNA" ;
VAL_ 641 UI_driverProfileRecallIndex 5 "UI_DRIVER_RECALL_5" 4 "UI_DRIVER_RECALL_4" 3 "UI_DRIVER_RECALL_3" 2 "UI_DRIVER_RECALL_2" 1 "UI_DRIVER_RECALL_1" 0 "UI_DRIVER_RECALL_SNA" ;
VAL_ 760 UI_mapSpeedLimitUnits 1 "KPH" 0 "MPH" ;
VAL_ 760 UI_userSpeedOffsetUnits 1 "KPH" 0 "MPH" ;
VAL_ 760 UI_conditionalSpeedLimit 31 "SNA" ;
VAL_ 984 UI_gpsAccuracy 127 "SNA" ;
VAL_ 986 UI_phoneGpsAccuracy 127 "SNA" ;
VAL_ 696 UI_radarTargetDx 255 "NO_OBJECT" ;
VAL_ 696 UI_radarTargetDxEnd 255 "NO_OBJECT" ;
VAL_ 712 UI_roadCurvHealth 3 "DATABASE" 2 "AVAILABLE" 1 "DEGRADED" 0 "UNAVAILABLE" ;
VAL_ 582 UI_solarAzimuthAngle -1 "SNA" ;
VAL_ 582 UI_solarAzimuthAngleCarRef 255 "SNA" ;
VAL_ 582 UI_isSunUp 1 "YES" 0 "NO_SNA" ;
VAL_ 582 UI_solarElevationAngle 127 "SNA" ;
VAL_ 824 UI_readyForDrive 1 "YES" 0 "NO_SNA" ;
VAL_ 824 UI_monitorModemPower 1 "ENABLE" 0 "DISABLE" ;
VAL_ 824 UI_factoryReset 3 "CUSTOMER" 2 "DIAGNOSTIC" 1 "DEVELOPER" 0 "NONE_SNA" ;
VAL_ 824 UI_cellNetworkTechnology 15 "CELL_NETWORK_SNA" 10 "CELL_NETWORK_WCDMA" 9 "CELL_NETWORK_CDMA" 8 "CELL_NETWORK_GSM" 7 "CELL_NETWORK_LTE" 6 "CELL_NETWORK_HSPA" 5 "CELL_NETWORK_HSUPA" 4 "CELL_NETWORK_HSDPA" 3 "CELL_NETWORK_UMTS" 2 "CELL_NETWORK_EDGE" 1 "CELL_NETWORK_GPRS" 0 "CELL_NETWORK_NONE" ;
VAL_ 824 UI_tegraCoreTemperature 255 "SNA" ;
VAL_ 824 UI_tegraAmbientTemperature 255 "SNA" ;
VAL_ 824 UI_autopilotTrial 3 "ACTIVE" 2 "STOP" 1 "START" 0 "NONE" ;
VAL_ 824 UI_cellSignalBars 7 "SNA" 5 "FIVE" 4 "FOUR" 3 "THREE" 2 "TWO" 1 "ONE" 0 "ZERO" ;
VAL_ 824 UI_hardwareType 2 "INFO_TWO" 1 "INFO_ONE" 0 "SNA" ;
VAL_ 1070 UI_linkState 2 "LINK_STATE_WIFI" 1 "LINK_STATE_CELL" 0 "LINK_STATE_NONE" ;
VAL_ 1070 UI_autopilotPowerStateRequest 2 "AUTOPILOT_SUSPEND" 1 "AUTOPILOT_SENTRY" 0 "AUTOPILOT_NOMINAL" ;
VAL_ 660 UI_suspensionLevelRequest 7 "LEVEL_REQUEST_VERY_HIGH_LEVEL_PERSIST" 6 "LEVEL_REQUEST_HIGH_LEVEL_PERSIST" 5 "LEVEL_REQUEST_VERY_HIGH_LEVEL_TEMPORARY" 4 "LEVEL_REQUEST_HIGH_LEVEL_TEMPORARY" 3 "LEVEL_REQUEST_STANDARD_LEVEL" 2 "LEVEL_REQUEST_LOW_LEVEL" 1 "LEVEL_REQUEST_VERY_LOW_LEVEL" 0 "LEVEL_REQUEST_NONE" ;
VAL_ 660 UI_adaptiveRideRequest 3 "ADAPTIVE_RIDE_REQUEST_ADVANCED" 2 "ADAPTIVE_RIDE_REQUEST_SPORT" 1 "ADAPTIVE_RIDE_REQUEST_AUTO" 0 "ADAPTIVE_RIDE_REQUEST_COMFORT" ;
VAL_ 660 UI_suspensionLoweringRequest 3 "SUSPENSION_LOWERING_REQUEST_SNA" 2 "SUSPENSION_LOWERING_REQUEST_AUTO" 1 "SUSPENSION_LOWERING_REQUEST_ALWAYS" 0 "SUSPENSION_LOWERING_REQUEST_NEVER" ;
VAL_ 660 UI_geofenceLevelingRequest 5 "GEOFENCE_LEVELING_REQUEST_SNA" 4 "GEOFENCE_LEVELING_REQUEST_VERY_HIGH_PERSIST" 3 "GEOFENCE_LEVELING_REQUEST_HIGH_PERSIST" 2 "GEOFENCE_LEVELING_REQUEST_VERY_HIGH_TEMPORARY" 1 "GEOFENCE_LEVELING_REQUEST_HIGH_TEMPORARY" 0 "GEOFENCE_LEVELING_REQUEST_NONE" ;
VAL_ 660 UI_jackModeToggleRequest 1 "JACK_MODE_TOGGLE_REQUEST_ACTIVE" 0 "JACK_MODE_TOGGLE_REQUEST_NONE" ;
VAL_ 627 UI_driverSeatHeatReq 3 "HEATER_REQUEST_LEVEL3" 2 "HEATER_REQUEST_LEVEL2" 1 "HEATER_REQUEST_LEVEL1" 0 "HEATER_REQUEST_OFF" ;
VAL_ 627 UI_passengerSeatHeatReq 3 "HEATER_REQUEST_LEVEL3" 2 "HEATER_REQUEST_LEVEL2" 1 "HEATER_REQUEST_LEVEL1" 0 "HEATER_REQUEST_OFF" ;
VAL_ 898 VCSEATD_CPULoadTotal 255 "SNA" ;
VAL_ 898 VCSEATD_CPULoad1msTask 255 "SNA" ;
VAL_ 898 VCSEATD_CPULoad10msTask 255 "SNA" ;
VAL_ 898 VCSEATD_CPULoad100msTask 255 "SNA" ;
VAL_ 898 VCSEATD_CPULoad1000msTask 255 "SNA" ;
VAL_ 578 VCSEATD_lumbarLVState 3 "LV_FAULT" 2 "LV_GOING_DOWN" 1 "LV_ON" 0 "LV_OFF" ;
VAL_ 1314 VCSEATD_alertClearedID 445 "VCSEATD_a445_drv8703SpiFaultDBG" 444 "VCSEATD_a444_drv8703Fault" 415 "VCSEATD_a415_ocsRebaseEgressDBG" 414 "VCSEATD_a414_ocsMissedIngressDBG" 413 "VCSEATD_a413_ocsSBRFaulted" 412 "VCSEATD_a412_ocsRebaselineDBG" 411 "VCSEATD_a411_ocsDataTimeout" 410 "VCSEATD_a410_ocsSlowDrift" 409 "VCSEATD_a409_ocsHeatPadNoConnect" 408 "VCSEATD_a408_ocsSensorDroop" 407 "VCSEATD_a407_ocsManufactureInvld" 406 "VCSEATD_a406_ocsCalibMismatch" 405 "VCSEATD_a405_ocsSensorDisconnect" 404 "VCSEATD_a404_ocsBackDisconnect" 403 "VCSEATD_a403_ocsSensorHigh" 402 "VCSEATD_a402_ocsSensorLow" 401 "VCSEATD_a401_ocsDiagContext" 400 "VCSEATD_a400_ocsCushionMismatch" 399 "VCSEATD_a399_ocsTHMIA" 398 "VCSEATD_a398_ocsTOSMIA" 397 "VCSEATD_a397_ocsTHInvalCalib" 396 "VCSEATD_a396_ocsSpareInvalCalib" 394 "VCSEATD_a394_ocsCushionInvlCalib" 393 "VCSEATD_a393_ocsTHNoCalib" 392 "VCSEATD_a392_ocsSpareNoCalib" 390 "VCSEATD_a390_ocsCushionNoCalib" 389 "VCSEATD_a389_ocsTHInvalid" 388 "VCSEATD_a388_ocsSpareShort" 387 "VCSEATD_a387_ocsSpareLow" 386 "VCSEATD_a386_ocsSpareHigh" 382 "VCSEATD_a382_ocsCushionShort" 381 "VCSEATD_a381_ocsCushionLow" 380 "VCSEATD_a380_ocsCushionHigh" 291 "VCSEATD_a291_buckleFaultedFront" 290 "VCSEATD_a290_occupancyFaultFront" 270 "VCSEATD_a270_seatLiftHCEncStlDbg" 269 "VCSEATD_a269_seatTiltHCEncStlDbg" 268 "VCSEATD_a268_seatBackHCEncStlDbg" 267 "VCSEATD_a267_seatTrackHCEncStl" 266 "VCSEATD_a266_seatLiftStallDebug" 265 "VCSEATD_a265_seatTiltStallDebug" 264 "VCSEATD_a264_seatBackStallDebug" 263 "VCSEATD_a263_seatTrackStallDebug" 254 "VCSEATD_a254_seatUncalLift" 253 "VCSEATD_a253_seatUncalTilt" 252 "VCSEATD_a252_seatUncalBack" 251 "VCSEATD_a251_seatUncalTrack" 242 "VCSEATD_a242_seatHeatTmpFront" 241 "VCSEATD_a241_seatHeatMIAFront" 240 "VCSEATD_a240_seatHeatShortFront" 239 "VCSEATD_a239_seatHeatIFront" 238 "VCSEATD_a238_lumbarValveMIA" 237 "VCSEATD_a237_lumbarOverPresB" 236 "VCSEATD_a236_lumbarOverPresA" 235 "VCSEATD_a235_seatCurrUnderLift" 234 "VCSEATD_a234_seatCurrUnderTilt" 233 "VCSEATD_a233_seatCurrUnderBack" 232 "VCSEATD_a232_seatCurrUnderTrack" 231 "VCSEATD_a231_seatEncOverLift" 230 "VCSEATD_a230_seatEncOverTilt" 229 "VCSEATD_a229_seatEncOverBack" 228 "VCSEATD_a228_seatEncOverTrack" 227 "VCSEATD_a227_seatEncStallLift" 226 "VCSEATD_a226_seatEncStallTilt" 225 "VCSEATD_a225_seatEncStallBack" 224 "VCSEATD_a224_seatEncStallTrack" 223 "VCSEATD_a223_seatCurrStallLift" 222 "VCSEATD_a222_seatCurrStallTilt" 221 "VCSEATD_a221_seatCurrStallBack" 220 "VCSEATD_a220_seatCurrStallTrack" 219 "VCSEATD_a219_motorCurrentDropout" 218 "VCSEATD_a218_motorDriverFault" 201 "VCSEATD_a201_motorDutyEncDisabl" 200 "VCSEATD_a200_motorPhantomEncoder" 64 "VCSEATD_a064_busSleepReqTimeout" 63 "VCSEATD_a063_SwitchFault" 62 "VCSEATD_a062_XCPWasConnected" 61 "VCSEATD_a061_XCPConnected" 60 "VCSEATD_a060_engineeringBuild" 59 "VCSEATD_a059_inputResistanceHigh" 58 "VCSEATD_a058_inputRHighSyncDebug" 46 "VCSEATD_a046_Task1000msError" 45 "VCSEATD_a045_Task100msError" 44 "VCSEATD_a044_Task10msError" 43 "VCSEATD_a043_Task1msError" 42 "VCSEATD_a042_HighStackUsage" 41 "VCSEATD_a041_HighCPULoad" 31 "VCSEATD_a031_UDSActive" 30 "VCSEATD_a030_ECULogUploadRequest" 22 "VCSEATD_a022_TaskInitError" 21 "VCSEATD_a021_TaskSchedulerError" 15 "VCSEATD_a015_NVMMAlert" 13 "VCSEATD_a013_AlertManagerFault" 12 "VCSEATD_a012_CPUReset" 10 "VCSEATD_a010_ExtSupplyVoltError" 5 "VCSEATD_a005_CANTXError" 3 "VCSEATD_a003_SWAssertion" 2 "VCSEATD_a002_PowerLossReset" 1 "VCSEATD_a001_WatchdogReset" 0 "VCSEATD_ALERT_DO_NOT_USE_ZERO" ;
VAL_ 1373 VCSEATD_alertID 445 "VCSEATD_a445_drv8703SpiFaultDBG" 444 "VCSEATD_a444_drv8703Fault" 415 "VCSEATD_a415_ocsRebaseEgressDBG" 414 "VCSEATD_a414_ocsMissedIngressDBG" 413 "VCSEATD_a413_ocsSBRFaulted" 412 "VCSEATD_a412_ocsRebaselineDBG" 411 "VCSEATD_a411_ocsDataTimeout" 410 "VCSEATD_a410_ocsSlowDrift" 409 "VCSEATD_a409_ocsHeatPadNoConnect" 408 "VCSEATD_a408_ocsSensorDroop" 407 "VCSEATD_a407_ocsManufactureInvld" 406 "VCSEATD_a406_ocsCalibMismatch" 405 "VCSEATD_a405_ocsSensorDisconnect" 404 "VCSEATD_a404_ocsBackDisconnect" 403 "VCSEATD_a403_ocsSensorHigh" 402 "VCSEATD_a402_ocsSensorLow" 401 "VCSEATD_a401_ocsDiagContext" 400 "VCSEATD_a400_ocsCushionMismatch" 399 "VCSEATD_a399_ocsTHMIA" 398 "VCSEATD_a398_ocsTOSMIA" 397 "VCSEATD_a397_ocsTHInvalCalib" 396 "VCSEATD_a396_ocsSpareInvalCalib" 394 "VCSEATD_a394_ocsCushionInvlCalib" 393 "VCSEATD_a393_ocsTHNoCalib" 392 "VCSEATD_a392_ocsSpareNoCalib" 390 "VCSEATD_a390_ocsCushionNoCalib" 389 "VCSEATD_a389_ocsTHInvalid" 388 "VCSEATD_a388_ocsSpareShort" 387 "VCSEATD_a387_ocsSpareLow" 386 "VCSEATD_a386_ocsSpareHigh" 382 "VCSEATD_a382_ocsCushionShort" 381 "VCSEATD_a381_ocsCushionLow" 380 "VCSEATD_a380_ocsCushionHigh" 291 "VCSEATD_a291_buckleFaultedFront" 290 "VCSEATD_a290_occupancyFaultFront" 270 "VCSEATD_a270_seatLiftHCEncStlDbg" 269 "VCSEATD_a269_seatTiltHCEncStlDbg" 268 "VCSEATD_a268_seatBackHCEncStlDbg" 267 "VCSEATD_a267_seatTrackHCEncStl" 266 "VCSEATD_a266_seatLiftStallDebug" 265 "VCSEATD_a265_seatTiltStallDebug" 264 "VCSEATD_a264_seatBackStallDebug" 263 "VCSEATD_a263_seatTrackStallDebug" 254 "VCSEATD_a254_seatUncalLift" 253 "VCSEATD_a253_seatUncalTilt" 252 "VCSEATD_a252_seatUncalBack" 251 "VCSEATD_a251_seatUncalTrack" 242 "VCSEATD_a242_seatHeatTmpFront" 241 "VCSEATD_a241_seatHeatMIAFront" 240 "VCSEATD_a240_seatHeatShortFront" 239 "VCSEATD_a239_seatHeatIFront" 238 "VCSEATD_a238_lumbarValveMIA" 237 "VCSEATD_a237_lumbarOverPresB" 236 "VCSEATD_a236_lumbarOverPresA" 235 "VCSEATD_a235_seatCurrUnderLift" 234 "VCSEATD_a234_seatCurrUnderTilt" 233 "VCSEATD_a233_seatCurrUnderBack" 232 "VCSEATD_a232_seatCurrUnderTrack" 231 "VCSEATD_a231_seatEncOverLift" 230 "VCSEATD_a230_seatEncOverTilt" 229 "VCSEATD_a229_seatEncOverBack" 228 "VCSEATD_a228_seatEncOverTrack" 227 "VCSEATD_a227_seatEncStallLift" 226 "VCSEATD_a226_seatEncStallTilt" 225 "VCSEATD_a225_seatEncStallBack" 224 "VCSEATD_a224_seatEncStallTrack" 223 "VCSEATD_a223_seatCurrStallLift" 222 "VCSEATD_a222_seatCurrStallTilt" 221 "VCSEATD_a221_seatCurrStallBack" 220 "VCSEATD_a220_seatCurrStallTrack" 219 "VCSEATD_a219_motorCurrentDropout" 218 "VCSEATD_a218_motorDriverFault" 201 "VCSEATD_a201_motorDutyEncDisabl" 200 "VCSEATD_a200_motorPhantomEncoder" 64 "VCSEATD_a064_busSleepReqTimeout" 63 "VCSEATD_a063_SwitchFault" 62 "VCSEATD_a062_XCPWasConnected" 61 "VCSEATD_a061_XCPConnected" 60 "VCSEATD_a060_engineeringBuild" 59 "VCSEATD_a059_inputResistanceHigh" 58 "VCSEATD_a058_inputRHighSyncDebug" 46 "VCSEATD_a046_Task1000msError" 45 "VCSEATD_a045_Task100msError" 44 "VCSEATD_a044_Task10msError" 43 "VCSEATD_a043_Task1msError" 42 "VCSEATD_a042_HighStackUsage" 41 "VCSEATD_a041_HighCPULoad" 31 "VCSEATD_a031_UDSActive" 30 "VCSEATD_a030_ECULogUploadRequest" 22 "VCSEATD_a022_TaskInitError" 21 "VCSEATD_a021_TaskSchedulerError" 15 "VCSEATD_a015_NVMMAlert" 13 "VCSEATD_a013_AlertManagerFault" 12 "VCSEATD_a012_CPUReset" 10 "VCSEATD_a010_ExtSupplyVoltError" 5 "VCSEATD_a005_CANTXError" 3 "VCSEATD_a003_SWAssertion" 2 "VCSEATD_a002_PowerLossReset" 1 "VCSEATD_a001_WatchdogReset" 0 "VCSEATD_ALERT_DO_NOT_USE_ZERO" ;
VAL_ 1373 VCSEATD_alertType 1 "ALERT_SET" 0 "ALERT_CLEARED" ;
VAL_ 1373 VCSEATD_a058_faultReason 1 "INPUT_POWER_SYNC_FAULT_REASON_DELTA_THRESHOLD" 0 "INPUT_POWER_SYNC_FAULT_REASON_THRESHOLD" ;
VAL_ 1373 VCSEATD_a220_seatMotorState 5 "SEAT_STATE_UNDEFINED" 4 "SEAT_STATE_CALIBRATING" 3 "SEAT_STATE_RECALLING" 2 "SEAT_STATE_MOVING_DOWN" 1 "SEAT_STATE_MOVING_UP" 0 "SEAT_STATE_STOPPED" ;
VAL_ 1373 VCSEATD_a220_seatSwitchBack 3 "SWITCH_SNA" 2 "SWITCH_FAULT" 1 "SWITCH_ON" 0 "SWITCH_OFF" ;
VAL_ 1373 VCSEATD_a220_seatSwitchForward 3 "SWITCH_SNA" 2 "SWITCH_FAULT" 1 "SWITCH_ON" 0 "SWITCH_OFF" ;
VAL_ 1373 VCSEATD_a221_seatMotorState 5 "SEAT_STATE_UNDEFINED" 4 "SEAT_STATE_CALIBRATING" 3 "SEAT_STATE_RECALLING" 2 "SEAT_STATE_MOVING_DOWN" 1 "SEAT_STATE_MOVING_UP" 0 "SEAT_STATE_STOPPED" ;
VAL_ 1373 VCSEATD_a221_seatSwitchBack 3 "SWITCH_SNA" 2 "SWITCH_FAULT" 1 "SWITCH_ON" 0 "SWITCH_OFF" ;
VAL_ 1373 VCSEATD_a221_seatSwitchForward 3 "SWITCH_SNA" 2 "SWITCH_FAULT" 1 "SWITCH_ON" 0 "SWITCH_OFF" ;
VAL_ 1373 VCSEATD_a222_seatMotorState 5 "SEAT_STATE_UNDEFINED" 4 "SEAT_STATE_CALIBRATING" 3 "SEAT_STATE_RECALLING" 2 "SEAT_STATE_MOVING_DOWN" 1 "SEAT_STATE_MOVING_UP" 0 "SEAT_STATE_STOPPED" ;
VAL_ 1373 VCSEATD_a222_seatSwitchBack 3 "SWITCH_SNA" 2 "SWITCH_FAULT" 1 "SWITCH_ON" 0 "SWITCH_OFF" ;
VAL_ 1373 VCSEATD_a222_seatSwitchForward 3 "SWITCH_SNA" 2 "SWITCH_FAULT" 1 "SWITCH_ON" 0 "SWITCH_OFF" ;
VAL_ 1373 VCSEATD_a223_seatMotorState 5 "SEAT_STATE_UNDEFINED" 4 "SEAT_STATE_CALIBRATING" 3 "SEAT_STATE_RECALLING" 2 "SEAT_STATE_MOVING_DOWN" 1 "SEAT_STATE_MOVING_UP" 0 "SEAT_STATE_STOPPED" ;
VAL_ 1373 VCSEATD_a223_seatSwitchBack 3 "SWITCH_SNA" 2 "SWITCH_FAULT" 1 "SWITCH_ON" 0 "SWITCH_OFF" ;
VAL_ 1373 VCSEATD_a223_seatSwitchForward 3 "SWITCH_SNA" 2 "SWITCH_FAULT" 1 "SWITCH_ON" 0 "SWITCH_OFF" ;
VAL_ 1373 VCSEATD_a224_seatMotorState 5 "SEAT_STATE_UNDEFINED" 4 "SEAT_STATE_CALIBRATING" 3 "SEAT_STATE_RECALLING" 2 "SEAT_STATE_MOVING_DOWN" 1 "SEAT_STATE_MOVING_UP" 0 "SEAT_STATE_STOPPED" ;
VAL_ 1373 VCSEATD_a224_seatSwitchBack 3 "SWITCH_SNA" 2 "SWITCH_FAULT" 1 "SWITCH_ON" 0 "SWITCH_OFF" ;
VAL_ 1373 VCSEATD_a224_seatSwitchForward 3 "SWITCH_SNA" 2 "SWITCH_FAULT" 1 "SWITCH_ON" 0 "SWITCH_OFF" ;
VAL_ 1373 VCSEATD_a225_seatMotorState 5 "SEAT_STATE_UNDEFINED" 4 "SEAT_STATE_CALIBRATING" 3 "SEAT_STATE_RECALLING" 2 "SEAT_STATE_MOVING_DOWN" 1 "SEAT_STATE_MOVING_UP" 0 "SEAT_STATE_STOPPED" ;
VAL_ 1373 VCSEATD_a225_seatSwitchBack 3 "SWITCH_SNA" 2 "SWITCH_FAULT" 1 "SWITCH_ON" 0 "SWITCH_OFF" ;
VAL_ 1373 VCSEATD_a225_seatSwitchForward 3 "SWITCH_SNA" 2 "SWITCH_FAULT" 1 "SWITCH_ON" 0 "SWITCH_OFF" ;
VAL_ 1373 VCSEATD_a226_seatMotorState 5 "SEAT_STATE_UNDEFINED" 4 "SEAT_STATE_CALIBRATING" 3 "SEAT_STATE_RECALLING" 2 "SEAT_STATE_MOVING_DOWN" 1 "SEAT_STATE_MOVING_UP" 0 "SEAT_STATE_STOPPED" ;
VAL_ 1373 VCSEATD_a226_seatSwitchBack 3 "SWITCH_SNA" 2 "SWITCH_FAULT" 1 "SWITCH_ON" 0 "SWITCH_OFF" ;
VAL_ 1373 VCSEATD_a226_seatSwitchForward 3 "SWITCH_SNA" 2 "SWITCH_FAULT" 1 "SWITCH_ON" 0 "SWITCH_OFF" ;
VAL_ 1373 VCSEATD_a227_seatMotorState 5 "SEAT_STATE_UNDEFINED" 4 "SEAT_STATE_CALIBRATING" 3 "SEAT_STATE_RECALLING" 2 "SEAT_STATE_MOVING_DOWN" 1 "SEAT_STATE_MOVING_UP" 0 "SEAT_STATE_STOPPED" ;
VAL_ 1373 VCSEATD_a227_seatSwitchBack 3 "SWITCH_SNA" 2 "SWITCH_FAULT" 1 "SWITCH_ON" 0 "SWITCH_OFF" ;
VAL_ 1373 VCSEATD_a227_seatSwitchForward 3 "SWITCH_SNA" 2 "SWITCH_FAULT" 1 "SWITCH_ON" 0 "SWITCH_OFF" ;
VAL_ 1373 VCSEATD_a228_seatMotorState 5 "SEAT_STATE_UNDEFINED" 4 "SEAT_STATE_CALIBRATING" 3 "SEAT_STATE_RECALLING" 2 "SEAT_STATE_MOVING_DOWN" 1 "SEAT_STATE_MOVING_UP" 0 "SEAT_STATE_STOPPED" ;
VAL_ 1373 VCSEATD_a228_seatSwitchBack 3 "SWITCH_SNA" 2 "SWITCH_FAULT" 1 "SWITCH_ON" 0 "SWITCH_OFF" ;
VAL_ 1373 VCSEATD_a228_seatSwitchForward 3 "SWITCH_SNA" 2 "SWITCH_FAULT" 1 "SWITCH_ON" 0 "SWITCH_OFF" ;
VAL_ 1373 VCSEATD_a229_seatMotorState 5 "SEAT_STATE_UNDEFINED" 4 "SEAT_STATE_CALIBRATING" 3 "SEAT_STATE_RECALLING" 2 "SEAT_STATE_MOVING_DOWN" 1 "SEAT_STATE_MOVING_UP" 0 "SEAT_STATE_STOPPED" ;
VAL_ 1373 VCSEATD_a229_seatSwitchBack 3 "SWITCH_SNA" 2 "SWITCH_FAULT" 1 "SWITCH_ON" 0 "SWITCH_OFF" ;
VAL_ 1373 VCSEATD_a229_seatSwitchForward 3 "SWITCH_SNA" 2 "SWITCH_FAULT" 1 "SWITCH_ON" 0 "SWITCH_OFF" ;
VAL_ 1373 VCSEATD_a230_seatMotorState 5 "SEAT_STATE_UNDEFINED" 4 "SEAT_STATE_CALIBRATING" 3 "SEAT_STATE_RECALLING" 2 "SEAT_STATE_MOVING_DOWN" 1 "SEAT_STATE_MOVING_UP" 0 "SEAT_STATE_STOPPED" ;
VAL_ 1373 VCSEATD_a230_seatSwitchBack 3 "SWITCH_SNA" 2 "SWITCH_FAULT" 1 "SWITCH_ON" 0 "SWITCH_OFF" ;
VAL_ 1373 VCSEATD_a230_seatSwitchForward 3 "SWITCH_SNA" 2 "SWITCH_FAULT" 1 "SWITCH_ON" 0 "SWITCH_OFF" ;
VAL_ 1373 VCSEATD_a231_seatMotorState 5 "SEAT_STATE_UNDEFINED" 4 "SEAT_STATE_CALIBRATING" 3 "SEAT_STATE_RECALLING" 2 "SEAT_STATE_MOVING_DOWN" 1 "SEAT_STATE_MOVING_UP" 0 "SEAT_STATE_STOPPED" ;
VAL_ 1373 VCSEATD_a231_seatSwitchBack 3 "SWITCH_SNA" 2 "SWITCH_FAULT" 1 "SWITCH_ON" 0 "SWITCH_OFF" ;
VAL_ 1373 VCSEATD_a231_seatSwitchForward 3 "SWITCH_SNA" 2 "SWITCH_FAULT" 1 "SWITCH_ON" 0 "SWITCH_OFF" ;
VAL_ 1373 VCSEATD_a232_seatMotorState 5 "SEAT_STATE_UNDEFINED" 4 "SEAT_STATE_CALIBRATING" 3 "SEAT_STATE_RECALLING" 2 "SEAT_STATE_MOVING_DOWN" 1 "SEAT_STATE_MOVING_UP" 0 "SEAT_STATE_STOPPED" ;
VAL_ 1373 VCSEATD_a232_seatSwitchBack 3 "SWITCH_SNA" 2 "SWITCH_FAULT" 1 "SWITCH_ON" 0 "SWITCH_OFF" ;
VAL_ 1373 VCSEATD_a232_seatSwitchForward 3 "SWITCH_SNA" 2 "SWITCH_FAULT" 1 "SWITCH_ON" 0 "SWITCH_OFF" ;
VAL_ 1373 VCSEATD_a233_seatMotorState 5 "SEAT_STATE_UNDEFINED" 4 "SEAT_STATE_CALIBRATING" 3 "SEAT_STATE_RECALLING" 2 "SEAT_STATE_MOVING_DOWN" 1 "SEAT_STATE_MOVING_UP" 0 "SEAT_STATE_STOPPED" ;
VAL_ 1373 VCSEATD_a233_seatSwitchBack 3 "SWITCH_SNA" 2 "SWITCH_FAULT" 1 "SWITCH_ON" 0 "SWITCH_OFF" ;
VAL_ 1373 VCSEATD_a233_seatSwitchForward 3 "SWITCH_SNA" 2 "SWITCH_FAULT" 1 "SWITCH_ON" 0 "SWITCH_OFF" ;
VAL_ 1373 VCSEATD_a234_seatMotorState 5 "SEAT_STATE_UNDEFINED" 4 "SEAT_STATE_CALIBRATING" 3 "SEAT_STATE_RECALLING" 2 "SEAT_STATE_MOVING_DOWN" 1 "SEAT_STATE_MOVING_UP" 0 "SEAT_STATE_STOPPED" ;
VAL_ 1373 VCSEATD_a234_seatSwitchBack 3 "SWITCH_SNA" 2 "SWITCH_FAULT" 1 "SWITCH_ON" 0 "SWITCH_OFF" ;
VAL_ 1373 VCSEATD_a234_seatSwitchForward 3 "SWITCH_SNA" 2 "SWITCH_FAULT" 1 "SWITCH_ON" 0 "SWITCH_OFF" ;
VAL_ 1373 VCSEATD_a235_seatMotorState 5 "SEAT_STATE_UNDEFINED" 4 "SEAT_STATE_CALIBRATING" 3 "SEAT_STATE_RECALLING" 2 "SEAT_STATE_MOVING_DOWN" 1 "SEAT_STATE_MOVING_UP" 0 "SEAT_STATE_STOPPED" ;
VAL_ 1373 VCSEATD_a235_seatSwitchBack 3 "SWITCH_SNA" 2 "SWITCH_FAULT" 1 "SWITCH_ON" 0 "SWITCH_OFF" ;
VAL_ 1373 VCSEATD_a235_seatSwitchForward 3 "SWITCH_SNA" 2 "SWITCH_FAULT" 1 "SWITCH_ON" 0 "SWITCH_OFF" ;
VAL_ 1373 VCSEATD_a236_lumbarAState 5 "SEAT_STATE_UNDEFINED" 4 "SEAT_STATE_CALIBRATING" 3 "SEAT_STATE_RECALLING" 2 "SEAT_STATE_MOVING_DOWN" 1 "SEAT_STATE_MOVING_UP" 0 "SEAT_STATE_STOPPED" ;
VAL_ 1373 VCSEATD_a236_lumbarBState 5 "SEAT_STATE_UNDEFINED" 4 "SEAT_STATE_CALIBRATING" 3 "SEAT_STATE_RECALLING" 2 "SEAT_STATE_MOVING_DOWN" 1 "SEAT_STATE_MOVING_UP" 0 "SEAT_STATE_STOPPED" ;
VAL_ 1373 VCSEATD_a237_lumbarAState 5 "SEAT_STATE_UNDEFINED" 4 "SEAT_STATE_CALIBRATING" 3 "SEAT_STATE_RECALLING" 2 "SEAT_STATE_MOVING_DOWN" 1 "SEAT_STATE_MOVING_UP" 0 "SEAT_STATE_STOPPED" ;
VAL_ 1373 VCSEATD_a237_lumbarBState 5 "SEAT_STATE_UNDEFINED" 4 "SEAT_STATE_CALIBRATING" 3 "SEAT_STATE_RECALLING" 2 "SEAT_STATE_MOVING_DOWN" 1 "SEAT_STATE_MOVING_UP" 0 "SEAT_STATE_STOPPED" ;
VAL_ 1373 VCSEATD_a238_lumbarAState 5 "SEAT_STATE_UNDEFINED" 4 "SEAT_STATE_CALIBRATING" 3 "SEAT_STATE_RECALLING" 2 "SEAT_STATE_MOVING_DOWN" 1 "SEAT_STATE_MOVING_UP" 0 "SEAT_STATE_STOPPED" ;
VAL_ 1373 VCSEATD_a238_lumbarBState 5 "SEAT_STATE_UNDEFINED" 4 "SEAT_STATE_CALIBRATING" 3 "SEAT_STATE_RECALLING" 2 "SEAT_STATE_MOVING_DOWN" 1 "SEAT_STATE_MOVING_UP" 0 "SEAT_STATE_STOPPED" ;
VAL_ 1373 VCSEATD_a251_seatMotorState 5 "SEAT_STATE_UNDEFINED" 4 "SEAT_STATE_CALIBRATING" 3 "SEAT_STATE_RECALLING" 2 "SEAT_STATE_MOVING_DOWN" 1 "SEAT_STATE_MOVING_UP" 0 "SEAT_STATE_STOPPED" ;
VAL_ 1373 VCSEATD_a251_seatSwitchBack 3 "SWITCH_SNA" 2 "SWITCH_FAULT" 1 "SWITCH_ON" 0 "SWITCH_OFF" ;
VAL_ 1373 VCSEATD_a251_seatSwitchForward 3 "SWITCH_SNA" 2 "SWITCH_FAULT" 1 "SWITCH_ON" 0 "SWITCH_OFF" ;
VAL_ 1373 VCSEATD_a252_seatMotorState 5 "SEAT_STATE_UNDEFINED" 4 "SEAT_STATE_CALIBRATING" 3 "SEAT_STATE_RECALLING" 2 "SEAT_STATE_MOVING_DOWN" 1 "SEAT_STATE_MOVING_UP" 0 "SEAT_STATE_STOPPED" ;
VAL_ 1373 VCSEATD_a252_seatSwitchBack 3 "SWITCH_SNA" 2 "SWITCH_FAULT" 1 "SWITCH_ON" 0 "SWITCH_OFF" ;
VAL_ 1373 VCSEATD_a252_seatSwitchForward 3 "SWITCH_SNA" 2 "SWITCH_FAULT" 1 "SWITCH_ON" 0 "SWITCH_OFF" ;
VAL_ 1373 VCSEATD_a253_seatMotorState 5 "SEAT_STATE_UNDEFINED" 4 "SEAT_STATE_CALIBRATING" 3 "SEAT_STATE_RECALLING" 2 "SEAT_STATE_MOVING_DOWN" 1 "SEAT_STATE_MOVING_UP" 0 "SEAT_STATE_STOPPED" ;
VAL_ 1373 VCSEATD_a253_seatSwitchBack 3 "SWITCH_SNA" 2 "SWITCH_FAULT" 1 "SWITCH_ON" 0 "SWITCH_OFF" ;
VAL_ 1373 VCSEATD_a253_seatSwitchForward 3 "SWITCH_SNA" 2 "SWITCH_FAULT" 1 "SWITCH_ON" 0 "SWITCH_OFF" ;
VAL_ 1373 VCSEATD_a254_seatMotorState 5 "SEAT_STATE_UNDEFINED" 4 "SEAT_STATE_CALIBRATING" 3 "SEAT_STATE_RECALLING" 2 "SEAT_STATE_MOVING_DOWN" 1 "SEAT_STATE_MOVING_UP" 0 "SEAT_STATE_STOPPED" ;
VAL_ 1373 VCSEATD_a254_seatSwitchBack 3 "SWITCH_SNA" 2 "SWITCH_FAULT" 1 "SWITCH_ON" 0 "SWITCH_OFF" ;
VAL_ 1373 VCSEATD_a254_seatSwitchForward 3 "SWITCH_SNA" 2 "SWITCH_FAULT" 1 "SWITCH_ON" 0 "SWITCH_OFF" ;
VAL_ 1373 VCSEATD_a263_seatMotorState 5 "SEAT_STATE_UNDEFINED" 4 "SEAT_STATE_CALIBRATING" 3 "SEAT_STATE_RECALLING" 2 "SEAT_STATE_MOVING_DOWN" 1 "SEAT_STATE_MOVING_UP" 0 "SEAT_STATE_STOPPED" ;
VAL_ 1373 VCSEATD_a264_seatMotorState 5 "SEAT_STATE_UNDEFINED" 4 "SEAT_STATE_CALIBRATING" 3 "SEAT_STATE_RECALLING" 2 "SEAT_STATE_MOVING_DOWN" 1 "SEAT_STATE_MOVING_UP" 0 "SEAT_STATE_STOPPED" ;
VAL_ 1373 VCSEATD_a265_seatMotorState 5 "SEAT_STATE_UNDEFINED" 4 "SEAT_STATE_CALIBRATING" 3 "SEAT_STATE_RECALLING" 2 "SEAT_STATE_MOVING_DOWN" 1 "SEAT_STATE_MOVING_UP" 0 "SEAT_STATE_STOPPED" ;
VAL_ 1373 VCSEATD_a266_seatMotorState 5 "SEAT_STATE_UNDEFINED" 4 "SEAT_STATE_CALIBRATING" 3 "SEAT_STATE_RECALLING" 2 "SEAT_STATE_MOVING_DOWN" 1 "SEAT_STATE_MOVING_UP" 0 "SEAT_STATE_STOPPED" ;
VAL_ 1373 VCSEATD_a267_seatMotorState 5 "SEAT_STATE_UNDEFINED" 4 "SEAT_STATE_CALIBRATING" 3 "SEAT_STATE_RECALLING" 2 "SEAT_STATE_MOVING_DOWN" 1 "SEAT_STATE_MOVING_UP" 0 "SEAT_STATE_STOPPED" ;
VAL_ 1373 VCSEATD_a268_seatMotorState 5 "SEAT_STATE_UNDEFINED" 4 "SEAT_STATE_CALIBRATING" 3 "SEAT_STATE_RECALLING" 2 "SEAT_STATE_MOVING_DOWN" 1 "SEAT_STATE_MOVING_UP" 0 "SEAT_STATE_STOPPED" ;
VAL_ 1373 VCSEATD_a269_seatMotorState 5 "SEAT_STATE_UNDEFINED" 4 "SEAT_STATE_CALIBRATING" 3 "SEAT_STATE_RECALLING" 2 "SEAT_STATE_MOVING_DOWN" 1 "SEAT_STATE_MOVING_UP" 0 "SEAT_STATE_STOPPED" ;
VAL_ 1373 VCSEATD_a270_seatMotorState 5 "SEAT_STATE_UNDEFINED" 4 "SEAT_STATE_CALIBRATING" 3 "SEAT_STATE_RECALLING" 2 "SEAT_STATE_MOVING_DOWN" 1 "SEAT_STATE_MOVING_UP" 0 "SEAT_STATE_STOPPED" ;
VAL_ 1373 VCSEATD_a401_occupancySwitch 3 "SWITCH_SNA" 2 "SWITCH_FAULT" 1 "SWITCH_ON" 0 "SWITCH_OFF" ;
VAL_ 1373 VCSEATD_a415_occupancyTimeMins 65535 "SNA" ;
VAL_ 892 VCSEATD_matrixIndex 7 "VCSEATD_AlertMatrix7" 6 "VCSEATD_AlertMatrix6" 4 "VCSEATD_AlertMatrix4" 3 "VCSEATD_AlertMatrix3" 1 "VCSEATD_AlertMatrix1" 0 "VCSEATD_AlertMatrix0" ;
VAL_ 866 VCSEATD_crashDetectedType 3 "CRASH_DETECTED_TYPE_SEVERE" 2 "CRASH_DETECTED_TYPE_MINOR_2" 1 "CRASH_DETECTED_TYPE_MINOR_1" 0 "CRASH_DETECTED_TYPE_NONE" ;
VAL_ 866 VCSEATD_crashState 3 "CRASH_STATE_SEVERE" 2 "CRASH_STATE_MINOR_2" 1 "CRASH_STATE_MINOR_1" 0 "CRASH_STATE_IDLE" ;
VAL_ 770 VCSEATD_infoIndex 255 "BC_INFO_END" 33 "BC_INFO_SUBCOMPONENT6" 32 "BC_INFO_SUBCOMPONENT5" 31 "BC_INFO_SUBCOMPONENT4" 24 "BC_INFO_SUBCOMPONENT3" 23 "BC_INFO_SUBCOMPONENT2" 20 "BC_INFO_UDS_PROTOCOL_BOOTCRC" 19 "BC_INFO_VERSION_DEPRECATED" 18 "BC_INFO_BOOTLOADER_GITHASH" 17 "BC_INFO_APP_GITHASH" 16 "BC_INFO_SUBCOMPONENT1" 15 "BC_INFO_BOOTLOADER_CRC" 14 "BC_INFO_BOOTLOADER_SVN" 13 "BC_INFO_APP_CRC" 11 "BC_INFO_PCBAID_ASSYID_USAGEID" 10 "BC_INFO_BUILD_HWID_COMPONENTID" 9 "BC_INFO_DEPRECATED_9" 8 "BC_INFO_DEPRECATED_8" 7 "BC_INFO_DEPRECATED_7" 6 "BC_INFO_DEPRECATED_6" 5 "BC_INFO_DEPRECATED_5" 4 "BC_INFO_DEPRECATED_4" 3 "BC_INFO_DEPRECATED_3" 2 "BC_INFO_DEPRECATED_2" 1 "BC_INFO_DEPRECATED_1" 0 "BC_INFO_DEPRECATED_0" ;
VAL_ 770 VCSEATD_infoBuildType 4 "INFO_MFG_BUILD" 3 "INFO_TRACEABLE_CI_BUILD" 2 "INFO_LOCAL_BUILD" 1 "INFO_PLATFORM_BUILD" 0 "INFO_UNKNOWN_BUILD" ;
VAL_ 770 VCSEATD_infoAssemblyId 255 "ASSEMBLY_SNA" 1 "ASSEMBLY1" ;
VAL_ 1841 VCSEATD_ocsSensorStatusIndex 6 "OCS_SENSOR_STATUS_INDEX_COUNT" 5 "OCS_SENSOR_STATUS_INDEX_DSS1" 4 "OCS_SENSOR_STATUS_INDEX_DSS0" 3 "OCS_SENSOR_STATUS_INDEX_TOS2" 2 "OCS_SENSOR_STATUS_INDEX_TOS1" 1 "OCS_SENSOR_STATUS_INDEX_TEMP" 0 "OCS_SENSOR_STATUS_INDEX_TOS0" ;
VAL_ 1841 VCSEATD_classificationRaw 7 "SEAT_OCCUPANT_CLASSIFICATON_SNA" 5 "SEAT_OCCUPANT_CLASSIFICATON_NOT_CONFIGURED" 4 "SEAT_OCCUPANT_CLASSIFICATON_INIT" 3 "SEAT_OCCUPANT_CLASSIFICATON_LARGE" 2 "SEAT_OCCUPANT_CLASSIFICATON_SMALL" 1 "SEAT_OCCUPANT_CLASSIFICATON_INHIBIT" 0 "SEAT_OCCUPANT_CLASSIFICATON_EMPTY" ;
VAL_ 1843 VCSEATD_ocsSensorStatus2Index 3 "OCS_SENSOR_STATUS2_INDEX_COUNT" 2 "OCS_SENSOR_STATUS2_INDEX_CALIB2" 1 "OCS_SENSOR_STATUS2_INDEX_CALIB1" 0 "OCS_SENSOR_STATUS2_INDEX_CALIB0" ;
SIG_GROUP_ 2015 UDS_functionalRequestData_Hi 1 : UDS_functionalRequestData_0 UDS_functionalRequestData_1 UDS_functionalRequestData_2 UDS_functionalRequestData_3;
SIG_GROUP_ 2015 UDS_functionalRequestData_Low 1 : UDS_functionalRequestData_4 UDS_functionalRequestData_5 UDS_functionalRequestData_6 UDS_functionalRequestData_7;
